VERSION "dbc-export 1 2026.26.6.5"

NS_ :

BS_:

BU_: ADSP APB APP APS APSB BB BMS CC CMP CMPD CP DAS DI DIF DIR DPB EPAS3P EPAS3S EPASTP EPASTS EPBL EPBR ESP EVSE FC GTW HCML HCMR HVP IBST ICR IDB LS OCS1P ODIN PARK PCS PCS2 PLG PM PMF PMR PNCD PTC RADC RCM RCM2 RCM3 RCU SCCM SCM SCS SDCR TAS TCU TCU2 TPMS TRCM UDS UI UIS UMC USM V2G VC VCBATT VCBATT0 VCBATT1 VCBATT2 VCCC VCFRONT VCFRONT1 VCFRONT2 VCLEFT VCRIGHT VCSEAT2L VCSEAT2R VCSEC VEH

BO_ 800 BMS_alertMatrix: 8 BMS
 SG_ BMS_matrixIndex M : 0|4@1+ (1,0) [0|15] "" Vector__XXX
 SG_ BMS_a001_Pack_Config_Mismatch m0 : 4|1@1+ (1,0) [0|1] "" Vector__XXX
 SG_ BMS_a002_Pack_Performance_Config m0 : 5|1@1+ (1,0) [0|1] "" Vector__XXX
 SG_ BMS_a003_SW_Pack_Birth_Date_Miss m0 : 6|1@1+ (1,0) [0|1] "" Vector__XXX
 SG_ BMS_a004_Cal_Vs_Serial_Birth_Dat m0 : 7|1@1+ (1,0) [0|1] "" Vector__XXX
 SG_ BMS_a016_Pack_Module_Id_Mismatch m0 : 19|1@1+ (1,0) [0|1] "" Vector__XXX
 SG_ BMS_a017_SW_Brick_OV m0 : 20|1@1+ (1,0) [0|1] "" Vector__XXX
 SG_ BMS_a018_SW_Brick_UV m0 : 21|1@1+ (1,0) [0|1] "" Vector__XXX
 SG_ BMS_a019_SW_Module_OT m0 : 22|1@1+ (1,0) [0|1] "" Vector__XXX
 SG_ BMS_a020_SW_Brick_Instability m0 : 23|1@1+ (1,0) [0|1] "" Vector__XXX
 SG_ BMS_a021_SW_Dr_Limits_Regulation m0 : 24|1@1+ (1,0) [0|1] "" Vector__XXX
 SG_ BMS_a022_SW_Over_Current m0 : 25|1@1+ (1,0) [0|1] "" Vector__XXX
 SG_ BMS_a023_SW_Stack_OV m0 : 26|1@1+ (1,0) [0|1] "" Vector__XXX
 SG_ BMS_a024_SW_Islanded_Brick m0 : 27|1@1+ (1,0) [0|1] "" Vector__XXX
 SG_ BMS_a025_SW_PwrBalance_Anomaly m0 : 28|1@1+ (1,0) [0|1] "" Vector__XXX
 SG_ BMS_a026_SW_HFCurrent_Anomaly m0 : 29|1@1+ (1,0) [0|1] "" Vector__XXX
 SG_ BMS_a027_SW_Repeated_Isolation_F m0 : 30|1@1+ (1,0) [0|1] "" Vector__XXX
 SG_ BMS_a028_ShuntAsicCurrentOffsetD m0 : 31|1@1+ (1,0) [0|1] "" Vector__XXX
 SG_ BMS_a029_dSoc_Limiting m0 : 32|1@1+ (1,0) [0|1] "" Vector__XXX
 SG_ BMS_a030_Impedance_Deviation m0 : 33|1@1+ (1,0) [0|1] "" Vector__XXX
 SG_ BMS_a031_AlertsSetDuringSleep m0 : 34|1@1+ (1,0) [0|1] "" Vector__XXX
 SG_ BMS_a032_VoltageLoss m0 : 35|1@1+ (1,0) [0|1] "" Vector__XXX
 SG_ BMS_a033_VoltageDeviation m0 : 36|1@1+ (1,0) [0|1] "" Vector__XXX
 SG_ BMS_a034_SW_Passive_Isolation m0 : 37|1@1+ (1,0) [0|1] "" Vector__XXX
 SG_ BMS_a035_SW_Isolation m0 : 38|1@1+ (1,0) [0|1] "" Vector__XXX
 SG_ BMS_a036_SW_HvpHvilFault m0 : 39|1@1+ (1,0) [0|1] "" Vector__XXX
 SG_ BMS_a037_SW_Flood_Port_Open m0 : 40|1@1+ (1,0) [0|1] "" Vector__XXX
 SG_ BMS_a039_SW_DC_Link_Over_Voltage m0 : 42|1@1+ (1,0) [0|1] "" Vector__XXX
 SG_ BMS_a040_SW_Watch_Dog_HW_Trigger m0 : 43|1@1+ (1,0) [0|1] "" Vector__XXX
 SG_ BMS_a041_SW_Destructive_Reset_So m0 : 44|1@1+ (1,0) [0|1] "" Vector__XXX
 SG_ BMS_a042_SW_MPU_Error m0 : 45|1@1+ (1,0) [0|1] "" Vector__XXX
 SG_ BMS_a043_SW_Watch_Dog_Reset m0 : 46|1@1+ (1,0) [0|1] "" Vector__XXX
 SG_ BMS_a044_SW_Assertion m0 : 47|1@1+ (1,0) [0|1] "" Vector__XXX
 SG_ BMS_a045_SW_Exception m0 : 48|1@1+ (1,0) [0|1] "" Vector__XXX
 SG_ BMS_a046_SW_Task_Stack_Usage m0 : 49|1@1+ (1,0) [0|1] "" Vector__XXX
 SG_ BMS_a047_SW_Task_Stack_Overflow m0 : 50|1@1+ (1,0) [0|1] "" Vector__XXX
 SG_ BMS_a048_SW_Watch_Dog_Warning m0 : 51|1@1+ (1,0) [0|1] "" Vector__XXX
 SG_ BMS_a049_SW_Thermal_Event m0 : 52|1@1+ (1,0) [0|1] "" Vector__XXX
 SG_ BMS_a050_SW_Brick_Voltage_MIA m0 : 53|1@1+ (1,0) [0|1] "" Vector__XXX
 SG_ BMS_a051_SW_HVC_Vref_Bad m0 : 54|1@1+ (1,0) [0|1] "" Vector__XXX
 SG_ BMS_a052_SW_PCS_MIA m0 : 55|1@1+ (1,0) [0|1] "" Vector__XXX
 SG_ BMS_a054_SW_Ver_Supply_Fault m0 : 57|1@1+ (1,0) [0|1] "" Vector__XXX
 SG_ BMS_a055_SW_HvChain_Model_Fault m0 : 58|1@1+ (1,0) [0|1] "" Vector__XXX
 SG_ BMS_a056_SW_Standby_Supply_Fault m0 : 59|1@1+ (1,0) [0|1] "" Vector__XXX
 SG_ BMS_a057_SW_Bandolier_Model_Warn m0 : 60|1@1+ (1,0) [0|1] "" Vector__XXX
 SG_ BMS_a058_SW_Bandolier_Model_Rese m0 : 61|1@1+ (1,0) [0|1] "" Vector__XXX
 SG_ BMS_a059_SW_Pack_Voltage_Sensing m0 : 62|1@1+ (1,0) [0|1] "" Vector__XXX
 SG_ BMS_a060_SW_Leakage_Test_Failure m0 : 63|1@1+ (1,0) [0|1] "" Vector__XXX
 SG_ BMS_a061_SW_BrickV_Change m1 : 4|1@1+ (1,0) [0|1] "" Vector__XXX
 SG_ BMS_a062_SW_BrickV_Imbalance m1 : 5|1@1+ (1,0) [0|1] "" Vector__XXX
 SG_ BMS_a063_SW_ChargePort_Fault m1 : 6|1@1+ (1,0) [0|1] "" Vector__XXX
 SG_ BMS_a064_SW_SOC_Imbalance m1 : 7|1@1+ (1,0) [0|1] "" Vector__XXX
 SG_ BMS_a065_SW_CAC_Imbalance m1 : 8|1@1+ (1,0) [0|1] "" Vector__XXX
 SG_ BMS_a066_SOC_Imbalance_Warning m1 : 9|1@1+ (1,0) [0|1] "" Vector__XXX
 SG_ BMS_a067_CAC_Imbalance_Limiting m1 : 10|1@1+ (1,0) [0|1] "" Vector__XXX
 SG_ BMS_a068_CAC_Imbalance_Limp m1 : 11|1@1+ (1,0) [0|1] "" Vector__XXX
 SG_ BMS_a069_SW_Low_Power m1 : 12|1@1+ (1,0) [0|1] "" Vector__XXX
 SG_ BMS_a070_BrickV_Imbalance_Limiti m1 : 13|1@1+ (1,0) [0|1] "" Vector__XXX
 SG_ BMS_a071_SW_SM_TransCon_Not_Met m1 : 14|1@1+ (1,0) [0|1] "" Vector__XXX
 SG_ BMS_a072_Module_Brick_Split m1 : 15|1@1+ (1,0) [0|1] "" Vector__XXX
 SG_ BMS_a073_Unexpected_Loss_Of_Lv m1 : 16|1@1+ (1,0) [0|1] "" Vector__XXX
 SG_ BMS_a074_Max_Charge_Level_Reduce m1 : 17|1@1+ (1,0) [0|1] "" Vector__XXX
 SG_ BMS_a075_SW_Chg_Disable_Failure m1 : 18|1@1+ (1,0) [0|1] "" Vector__XXX
 SG_ BMS_a076_SW_Dch_While_Charging m1 : 19|1@1+ (1,0) [0|1] "" Vector__XXX
 SG_ BMS_a077_SW_Charger_Regulation m1 : 20|1@1+ (1,0) [0|1] "" Vector__XXX
 SG_ BMS_a078_Rapid_Dch_While_Chargin m1 : 21|1@1+ (1,0) [0|1] "" Vector__XXX
 SG_ BMS_a079_Max_Charge_Level_Exceed m1 : 22|1@1+ (1,0) [0|1] "" Vector__XXX
 SG_ BMS_a080_SW_Pack_Ctr_Impedance m1 : 23|1@1+ (1,0) [0|1] "" Vector__XXX
 SG_ BMS_a081_SW_Ctr_Close_Blocked m1 : 24|1@1+ (1,0) [0|1] "" Vector__XXX
 SG_ BMS_a082_SW_Ctr_Force_Open m1 : 25|1@1+ (1,0) [0|1] "" Vector__XXX
 SG_ BMS_a083_SW_Ctr_Close_Failure m1 : 26|1@1+ (1,0) [0|1] "" Vector__XXX
 SG_ BMS_a084_SW_Sleep_Wake_Aborted m1 : 27|1@1+ (1,0) [0|1] "" Vector__XXX
 SG_ BMS_a085_SW_Pack_Contactor_Misma m1 : 28|1@1+ (1,0) [0|1] "" Vector__XXX
 SG_ BMS_a086_SW_FC_Contactor_Mismatc m1 : 29|1@1+ (1,0) [0|1] "" Vector__XXX
 SG_ BMS_a087_SW_Feim_Test_Blocked m1 : 30|1@1+ (1,0) [0|1] "" Vector__XXX
 SG_ BMS_a088_SW_VcFront_MIA_InDrive m1 : 31|1@1+ (1,0) [0|1] "" Vector__XXX
 SG_ BMS_a089_SW_VcFront_MIA m1 : 32|1@1+ (1,0) [0|1] "" Vector__XXX
 SG_ BMS_a090_SW_Gateway_MIA m1 : 33|1@1+ (1,0) [0|1] "" Vector__XXX
 SG_ BMS_a091_SW_ChargePort_MIA m1 : 34|1@1+ (1,0) [0|1] "" Vector__XXX
 SG_ BMS_a092_SW_ChargePort_Mia_On_Hv m1 : 35|1@1+ (1,0) [0|1] "" Vector__XXX
 SG_ BMS_a094_SW_Drive_Inverter_MIA m1 : 37|1@1+ (1,0) [0|1] "" Vector__XXX
 SG_ BMS_a095_SW_UI_MIA m1 : 38|1@1+ (1,0) [0|1] "" Vector__XXX
 SG_ BMS_a097_SW_BMB_Over_CAN_Communi m1 : 40|1@1+ (1,0) [0|1] "" Vector__XXX
 SG_ BMS_a098_SW_BMB_Data_Integrity_L m1 : 41|1@1+ (1,0) [0|1] "" Vector__XXX
 SG_ BMS_a099_SW_BMB_Communication m1 : 42|1@1+ (1,0) [0|1] "" Vector__XXX
 SG_ BMS_a100_ThermalEventSuspected m1 : 43|1@1+ (1,0) [0|1] "" Vector__XXX
 SG_ BMS_a105_SW_One_Module_Tsense m1 : 48|1@1+ (1,0) [0|1] "" Vector__XXX
 SG_ BMS_a106_SW_All_Module_Tsense m1 : 49|1@1+ (1,0) [0|1] "" Vector__XXX
 SG_ BMS_a107_SW_Stack_Voltage_MIA m1 : 50|1@1+ (1,0) [0|1] "" Vector__XXX
 SG_ BMS_a108_SW_BMB_Device_OT m1 : 51|1@1+ (1,0) [0|1] "" Vector__XXX
 SG_ BMS_a109_HW_BMB_Mute_Status_Mism m1 : 52|1@1+ (1,0) [0|1] "" Vector__XXX
 SG_ BMS_a110_LifeModel_AvgOffset_Cha m1 : 53|1@1+ (1,0) [0|1] "" Vector__XXX
 SG_ BMS_a111_LifeModel_Spread_Change m1 : 54|1@1+ (1,0) [0|1] "" Vector__XXX
 SG_ BMS_a112_LifeModel_Discontinuity m1 : 55|1@1+ (1,0) [0|1] "" Vector__XXX
 SG_ BMS_a115_Energy_Rubberbanding_Re m1 : 58|1@1+ (1,0) [0|1] "" Vector__XXX
 SG_ BMS_a117_SW_Delta_SOC_Weak_Short m1 : 60|1@1+ (1,0) [0|1] "" Vector__XXX
 SG_ BMS_a118_SW_Delta_SOC_Weak_Short m1 : 61|1@1+ (1,0) [0|1] "" Vector__XXX
 SG_ BMS_a119_Fast_Open_Vsh_Detected m1 : 62|1@1+ (1,0) [0|1] "" Vector__XXX
 SG_ BMS_a120_SW_Delta_SOC_User_Warni m1 : 63|1@1+ (1,0) [0|1] "" Vector__XXX
 SG_ BMS_a121_SW_NVRAM_Config_Error m2 : 4|1@1+ (1,0) [0|1] "" Vector__XXX
 SG_ BMS_a122_SW_BMS_Therm_Irrational m2 : 5|1@1+ (1,0) [0|1] "" Vector__XXX
 SG_ BMS_a123_SW_Internal_Isolation m2 : 6|1@1+ (1,0) [0|1] "" Vector__XXX
 SG_ BMS_a124_Battery_Coolant_Flood m2 : 7|1@1+ (1,0) [0|1] "" Vector__XXX
 SG_ BMS_a126_SW_Thermistor_Failure m2 : 9|1@1+ (1,0) [0|1] "" Vector__XXX
 SG_ BMS_a127_SW_shunt_SNA m2 : 10|1@1+ (1,0) [0|1] "" Vector__XXX
 SG_ BMS_a128_SW_shunt_MIA m2 : 11|1@1+ (1,0) [0|1] "" Vector__XXX
 SG_ BMS_a129_SW_VSH_Failure m2 : 12|1@1+ (1,0) [0|1] "" Vector__XXX
 SG_ BMS_a130_IO_CAN_Error m2 : 13|1@1+ (1,0) [0|1] "" Vector__XXX
 SG_ BMS_a131_Bleed_FET_Failure m2 : 14|1@1+ (1,0) [0|1] "" Vector__XXX
 SG_ BMS_a132_HW_BMB_OTP_Uncorrctbl m2 : 15|1@1+ (1,0) [0|1] "" Vector__XXX
 SG_ BMS_a133_IO_CAN_Bus_Off m2 : 16|1@1+ (1,0) [0|1] "" Vector__XXX
 SG_ BMS_a134_SW_Delayed_Ctr_Off m2 : 17|1@1+ (1,0) [0|1] "" Vector__XXX
 SG_ BMS_a135_HW_BMB_Diagnostics_Fail m2 : 18|1@1+ (1,0) [0|1] "" Vector__XXX
 SG_ BMS_a136_SW_Module_OT_Warning m2 : 19|1@1+ (1,0) [0|1] "" Vector__XXX
 SG_ BMS_a137_SW_Brick_UV_Warning m2 : 20|1@1+ (1,0) [0|1] "" Vector__XXX
 SG_ BMS_a138_SW_Brick_OV_Warning m2 : 21|1@1+ (1,0) [0|1] "" Vector__XXX
 SG_ BMS_a139_SW_DC_Link_V_Irrational m2 : 22|1@1+ (1,0) [0|1] "" Vector__XXX
 SG_ BMS_a140_HW_BMB_Status_Fault m2 : 23|1@1+ (1,0) [0|1] "" Vector__XXX
 SG_ BMS_a141_SW_BMB_Status_Warning m2 : 24|1@1+ (1,0) [0|1] "" Vector__XXX
 SG_ BMS_a142_SW_Isolation_Degradatio m2 : 25|1@1+ (1,0) [0|1] "" Vector__XXX
 SG_ BMS_a143_SW_CAC_Change m2 : 26|1@1+ (1,0) [0|1] "" Vector__XXX
 SG_ BMS_a144_Hvp_Config_Mismatch m2 : 27|1@1+ (1,0) [0|1] "" Vector__XXX
 SG_ BMS_a145_SW_SOC_Change m2 : 28|1@1+ (1,0) [0|1] "" Vector__XXX
 SG_ BMS_a146_SW_Brick_Overdischarged m2 : 29|1@1+ (1,0) [0|1] "" Vector__XXX
 SG_ BMS_a147_SW_SOC_High_Ah_Error m2 : 30|1@1+ (1,0) [0|1] "" Vector__XXX
 SG_ BMS_a148_SW_Unsupported_BMB_ASIC m2 : 31|1@1+ (1,0) [0|1] "" Vector__XXX
 SG_ BMS_a149_SW_Missing_Config_Block m2 : 32|1@1+ (1,0) [0|1] "" Vector__XXX
 SG_ BMS_a150_SW_Missing_Part_Number m2 : 33|1@1+ (1,0) [0|1] "" Vector__XXX
 SG_ BMS_a151_SW_external_isolation m2 : 34|1@1+ (1,0) [0|1] "" Vector__XXX
 SG_ BMS_a152_Isolation_In_Dc_Charge m2 : 35|1@1+ (1,0) [0|1] "" Vector__XXX
 SG_ BMS_a153_GridFormFaulted m2 : 36|1@1+ (1,0) [0|1] "" Vector__XXX
 SG_ BMS_a154_SW_Brick_OV_Warning_Sto m2 : 37|1@1+ (1,0) [0|1] "" Vector__XXX
 SG_ BMS_a155_SW_Weak_short_impedence m2 : 38|1@1+ (1,0) [0|1] "" Vector__XXX
 SG_ BMS_a156_SW_BMB_Vref_bad m2 : 39|1@1+ (1,0) [0|1] "" Vector__XXX
 SG_ BMS_a157_SW_Hist_Update_Missed m2 : 40|1@1+ (1,0) [0|1] "" Vector__XXX
 SG_ BMS_a158_SW_HVP_HVI_Comms m2 : 41|1@1+ (1,0) [0|1] "" Vector__XXX
 SG_ BMS_a159_SW_HVP_ECU_Error m2 : 42|1@1+ (1,0) [0|1] "" Vector__XXX
 SG_ BMS_a160_SW_FC_Ctr_Clean_Failed m2 : 43|1@1+ (1,0) [0|1] "" Vector__XXX
 SG_ BMS_a161_SW_BMB_Vref_warning m2 : 44|1@1+ (1,0) [0|1] "" Vector__XXX
 SG_ BMS_a162_SW_No_Power_For_Support m2 : 45|1@1+ (1,0) [0|1] "" Vector__XXX
 SG_ BMS_a163_GridFormAborted m2 : 46|1@1+ (1,0) [0|1] "" Vector__XXX
 SG_ BMS_a164_SW_Uncontrolled_Regen m2 : 47|1@1+ (1,0) [0|1] "" Vector__XXX
 SG_ BMS_a165_SW_Pack_Partial_Weld m2 : 48|1@1+ (1,0) [0|1] "" Vector__XXX
 SG_ BMS_a166_SW_Pack_Full_Weld m2 : 49|1@1+ (1,0) [0|1] "" Vector__XXX
 SG_ BMS_a167_SW_FC_Partial_Weld m2 : 50|1@1+ (1,0) [0|1] "" Vector__XXX
 SG_ BMS_a168_SW_FC_Full_Weld m2 : 51|1@1+ (1,0) [0|1] "" Vector__XXX
 SG_ BMS_a169_SW_FC_Pack_Weld m2 : 52|1@1+ (1,0) [0|1] "" Vector__XXX
 SG_ BMS_a170_SW_Limp_Mode m2 : 53|1@1+ (1,0) [0|1] "" Vector__XXX
 SG_ BMS_a171_SW_Stack_Voltage_Sense m2 : 54|1@1+ (1,0) [0|1] "" Vector__XXX
 SG_ BMS_a172_SW_Isolation_Failure_In m2 : 55|1@1+ (1,0) [0|1] "" Vector__XXX
 SG_ BMS_a173_FullPackEnergyDegraded m2 : 56|1@1+ (1,0) [0|1] "" Vector__XXX
 SG_ BMS_a174_SW_Charge_Failure m2 : 57|1@1+ (1,0) [0|1] "" Vector__XXX
 SG_ BMS_a175_Charge_Failure_External m2 : 58|1@1+ (1,0) [0|1] "" Vector__XXX
 SG_ BMS_a176_SW_GracefulPowerOff m2 : 59|1@1+ (1,0) [0|1] "" Vector__XXX
 SG_ BMS_a177_SW_Energy_Buffer_Size m2 : 60|1@1+ (1,0) [0|1] "" Vector__XXX
 SG_ BMS_a178_SW_Uncontrolled_Regen_P m2 : 61|1@1+ (1,0) [0|1] "" Vector__XXX
 SG_ BMS_a179_HvpGpoRequestActive m2 : 62|1@1+ (1,0) [0|1] "" Vector__XXX
 SG_ BMS_a180_SW_ECU_reset_blocked m2 : 63|1@1+ (1,0) [0|1] "" Vector__XXX
 SG_ BMS_a181_SW_Shunt_Over_Temperatu m3 : 4|1@1+ (1,0) [0|1] "" Vector__XXX
 SG_ BMS_a182_LifeModel_NoCurrentLoss m3 : 5|1@1+ (1,0) [0|1] "" Vector__XXX
 SG_ BMS_a183_LifeModel_StoDcrGrowth_ m3 : 6|1@1+ (1,0) [0|1] "" Vector__XXX
 SG_ BMS_a184_LifeModel_CyclingLoss_C m3 : 7|1@1+ (1,0) [0|1] "" Vector__XXX
 SG_ BMS_a185_LifeModel_CyclingDcrGro m3 : 8|1@1+ (1,0) [0|1] "" Vector__XXX
 SG_ BMS_a186_RippleHeatingChargeFaul m3 : 9|1@1+ (1,0) [0|1] "" Vector__XXX
 SG_ BMS_a187_RippleHeatingEmergencyS m3 : 10|1@1+ (1,0) [0|1] "" Vector__XXX
 SG_ BMS_a188_PowershareChargeCurrent m3 : 11|1@1+ (1,0) [0|1] "" Vector__XXX
 SG_ BMS_a189_PowershareDischargeCurr m3 : 12|1@1+ (1,0) [0|1] "" Vector__XXX
 SG_ BMS_a190_PowershareMaxVoltageVio m3 : 13|1@1+ (1,0) [0|1] "" Vector__XXX
 SG_ BMS_a191_PowershareMinVoltageVio m3 : 14|1@1+ (1,0) [0|1] "" Vector__XXX
 SG_ BMS_a192_PowershareExternalCharg m3 : 15|1@1+ (1,0) [0|1] "" Vector__XXX
 SG_ BMS_a193_PowershareMaxBrickVolta m3 : 16|1@1+ (1,0) [0|1] "" Vector__XXX
 SG_ BMS_a194_PowershareLimitViolatio m3 : 17|1@1+ (1,0) [0|1] "" Vector__XXX
 SG_ BMS_a195_SW_DeltaTempOverThresho m3 : 18|1@1+ (1,0) [0|1] "" Vector__XXX
 SG_ BMS_a196_SW_PackVoltageUnderThre m3 : 19|1@1+ (1,0) [0|1] "" Vector__XXX
 SG_ BMS_a197_SW_High_SOC_OV m3 : 20|1@1+ (1,0) [0|1] "" Vector__XXX
 SG_ BMS_a198_SW_SOC_Abrupt_Change m3 : 21|1@1+ (1,0) [0|1] "" Vector__XXX
 SG_ BMS_a199_GridFollowAborted m3 : 22|1@1+ (1,0) [0|1] "" Vector__XXX
 SG_ BMS_a200_GridFollowFaulted m3 : 23|1@1+ (1,0) [0|1] "" Vector__XXX
 SG_ BMS_a201_SW_Brick_OV_During_Char m3 : 24|1@1+ (1,0) [0|1] "" Vector__XXX
 SG_ BMS_a202_AcChargeFaulted m3 : 25|1@1+ (1,0) [0|1] "" Vector__XXX
 SG_ BMS_a204_AcCpEmergencyShutdownRe m3 : 27|1@1+ (1,0) [0|1] "" Vector__XXX
 SG_ BMS_a214_AcChargeAborted m3 : 37|1@1+ (1,0) [0|1] "" Vector__XXX
 SG_ BMS_a221_PcsEmergencyShutdownReq m3 : 44|1@1+ (1,0) [0|1] "" Vector__XXX
 SG_ BMS_a227_ExcessChargeCurrentInCh m3 : 50|1@1+ (1,0) [0|1] "" Vector__XXX
 SG_ BMS_a254_LdcsCacImbalance m4 : 17|1@1+ (1,0) [0|1] "" Vector__XXX
 SG_ BMS_a255_EstimatedRangeReduced m4 : 18|1@1+ (1,0) [0|1] "" Vector__XXX
 SG_ BMS_a256_SW_Low_Power_Warning m4 : 19|1@1+ (1,0) [0|1] "" Vector__XXX
 SG_ BMS_d257_internalIsolationFault m4 : 20|1@1+ (1,0) [0|1] "" Vector__XXX
 SG_ BMS_d258_externalIsolationFault m4 : 21|1@1+ (1,0) [0|1] "" Vector__XXX
 SG_ BMS_d259_highVoltageInterlockFai m4 : 22|1@1+ (1,0) [0|1] "" Vector__XXX
 SG_ BMS_d260_chargePortInterlockFail m4 : 23|1@1+ (1,0) [0|1] "" Vector__XXX
 SG_ BMS_d261_batteryPackCellVoltageH m4 : 24|1@1+ (1,0) [0|1] "" Vector__XXX
 SG_ BMS_d262_batteryPackLowStateOfCh m4 : 25|1@1+ (1,0) [0|1] "" Vector__XXX
 SG_ BMS_d263_batterySystemCurrentHig m4 : 26|1@1+ (1,0) [0|1] "" Vector__XXX
 SG_ BMS_d264_invalidFirmwareConfig m4 : 27|1@1+ (1,0) [0|1] "" Vector__XXX
 SG_ BMS_d265_replaceBatteryPack m4 : 28|1@1+ (1,0) [0|1] "" Vector__XXX
 SG_ BMS_d266_energyReserveVoltageLow m4 : 29|1@1+ (1,0) [0|1] "" Vector__XXX
 SG_ BMS_d267_batteryPackCellVoltageS m4 : 30|1@1+ (1,0) [0|1] "" Vector__XXX
 SG_ BMS_d268_hvpInvalidFirmwareConfi m4 : 31|1@1+ (1,0) [0|1] "" Vector__XXX
 SG_ BMS_d269_highVoltageFuseABlown m4 : 32|1@1+ (1,0) [0|1] "" Vector__XXX
 SG_ BMS_d270_hvpCommsLost m4 : 33|1@1+ (1,0) [0|1] "" Vector__XXX
 SG_ BMS_d271_batteryPackSensorFailur m4 : 34|1@1+ (1,0) [0|1] "" Vector__XXX
 SG_ BMS_d272_batteryPackSensorCommsL m4 : 35|1@1+ (1,0) [0|1] "" Vector__XXX
 SG_ BMS_d273_vcFrontCommsLost m4 : 36|1@1+ (1,0) [0|1] "" Vector__XXX
 SG_ BMS_d274_packCurrentSensorACircu m4 : 37|1@1+ (1,0) [0|1] "" Vector__XXX
 SG_ BMS_d275_packPosContactorACircui m4 : 38|1@1+ (1,0) [0|1] "" Vector__XXX
 SG_ BMS_d276_packPosContactorAStuckC m4 : 39|1@1+ (1,0) [0|1] "" Vector__XXX
 SG_ BMS_d277_packNegContactorACircui m4 : 40|1@1+ (1,0) [0|1] "" Vector__XXX
 SG_ BMS_d278_packNegContactorAStuckC m4 : 41|1@1+ (1,0) [0|1] "" Vector__XXX
 SG_ BMS_d279_fastChargePosContactorA m4 : 42|1@1+ (1,0) [0|1] "" Vector__XXX
 SG_ BMS_d280_fastChargePosContactorA m4 : 43|1@1+ (1,0) [0|1] "" Vector__XXX
 SG_ BMS_d281_fastChargePosContactorA m4 : 44|1@1+ (1,0) [0|1] "" Vector__XXX
 SG_ BMS_d282_fastChargeNegContactorA m4 : 45|1@1+ (1,0) [0|1] "" Vector__XXX
 SG_ BMS_d283_fastChargeNegContactorA m4 : 46|1@1+ (1,0) [0|1] "" Vector__XXX
 SG_ BMS_d284_fastChargeNegContactorA m4 : 47|1@1+ (1,0) [0|1] "" Vector__XXX
 SG_ BMS_d285_packVoltageSensorACircu m4 : 48|1@1+ (1,0) [0|1] "" Vector__XXX
 SG_ BMS_d286_dcLinkVoltageHigh m4 : 49|1@1+ (1,0) [0|1] "" Vector__XXX
 SG_ BMS_d287_systemIsolationWarning m4 : 50|1@1+ (1,0) [0|1] "" Vector__XXX
 SG_ BMS_d288_batteryPackCellVoltageL m4 : 51|1@1+ (1,0) [0|1] "" Vector__XXX
 SG_ BMS_d289_batteryPackAOverTempera m4 : 52|1@1+ (1,0) [0|1] "" Vector__XXX
 SG_ BMS_d290_batteryPackTempSensorAC m4 : 53|1@1+ (1,0) [0|1] "" Vector__XXX
 SG_ BMS_a291_SOC_Imbalance_By_Delta_ m4 : 54|1@1+ (1,0) [0|1] "" Vector__XXX
 SG_ BMS_a299_PowershareFailure m4 : 62|1@1+ (1,0) [0|1] "" Vector__XXX

BO_ 818 BMS_bmbMinMax: 6 BMS
 SG_ BMS_bmbMinMaxMultiplexer M : 0|2@1+ (1,0) [0|3] "" Vector__XXX
 SG_ BMS_thermistorNumTMin m0 : 2|4@1+ (1,0) [0|15] "" Vector__XXX
 SG_ BMS_thermistorNumTMax m0 : 8|4@1+ (1,0) [0|15] "" Vector__XXX
 SG_ BMS_thermistorTMax m0 : 16|8@1+ (0.5,-40) [-40|87.5] "DegC" Vector__XXX
 SG_ BMS_thermistorTMin m0 : 24|8@1+ (0.5,-40) [-40|87.5] "DegC" Vector__XXX
 SG_ BMS_thermistorTAvg m0 : 32|8@1+ (0.5,-40) [-40|87.5] "DegC" Vector__XXX
 SG_ BMS_brickVoltageMax m1 : 2|12@1+ (0.002,0) [0|5] "V" Vector__XXX
 SG_ BMS_brickVoltageMin m1 : 16|12@1+ (0.002,0) [0|5] "V" Vector__XXX
 SG_ BMS_brickNumVoltageMax m1 : 32|7@1+ (1,1) [1|128] "" Vector__XXX
 SG_ BMS_brickNumVoltageMin m1 : 40|7@1+ (1,1) [1|128] "" Vector__XXX

BO_ 1025 BMS_brickMeasurements: 8 BMS
 SG_ BMS_brickVoltageMultiplexer M : 0|8@1+ (1,0) [0|255] "" Vector__XXX
 SG_ BMS_brickVoltageCounter : 14|2@1+ (1,0) [0|3] "" Vector__XXX
 SG_ BMS_brickVoltageStatus1 m0 : 8|2@1+ (1,0) [0|3] "" Vector__XXX
 SG_ BMS_brickVoltageStatus2 m0 : 10|2@1+ (1,0) [0|3] "" Vector__XXX
 SG_ BMS_brickVoltageStatus3 m0 : 12|2@1+ (1,0) [0|3] "" Vector__XXX
 SG_ BMS_brickVoltage1 m0 : 16|16@1+ (0.0001,0) [0|5] "V" Vector__XXX
 SG_ BMS_brickVoltage2 m0 : 32|16@1+ (0.0001,0) [0|5] "V" Vector__XXX
 SG_ BMS_brickVoltage3 m0 : 48|16@1+ (0.0001,0) [0|5] "V" Vector__XXX
 SG_ BMS_brickVoltageStatus4 m1 : 8|2@1+ (1,0) [0|3] "" Vector__XXX
 SG_ BMS_brickVoltageStatus5 m1 : 10|2@1+ (1,0) [0|3] "" Vector__XXX
 SG_ BMS_brickVoltageStatus6 m1 : 12|2@1+ (1,0) [0|3] "" Vector__XXX
 SG_ BMS_brickVoltage4 m1 : 16|16@1+ (0.0001,0) [0|5] "V" Vector__XXX
 SG_ BMS_brickVoltage5 m1 : 32|16@1+ (0.0001,0) [0|5] "V" Vector__XXX
 SG_ BMS_brickVoltage6 m1 : 48|16@1+ (0.0001,0) [0|5] "V" Vector__XXX
 SG_ BMS_brickVoltageStatus7 m2 : 8|2@1+ (1,0) [0|3] "" Vector__XXX
 SG_ BMS_brickVoltageStatus8 m2 : 10|2@1+ (1,0) [0|3] "" Vector__XXX
 SG_ BMS_brickVoltageStatus9 m2 : 12|2@1+ (1,0) [0|3] "" Vector__XXX
 SG_ BMS_brickVoltage7 m2 : 16|16@1+ (0.0001,0) [0|5] "V" Vector__XXX
 SG_ BMS_brickVoltage8 m2 : 32|16@1+ (0.0001,0) [0|5] "V" Vector__XXX
 SG_ BMS_brickVoltage9 m2 : 48|16@1+ (0.0001,0) [0|5] "V" Vector__XXX
 SG_ BMS_brickVoltageStatus10 m3 : 8|2@1+ (1,0) [0|3] "" Vector__XXX
 SG_ BMS_brickVoltageStatus11 m3 : 10|2@1+ (1,0) [0|3] "" Vector__XXX
 SG_ BMS_brickVoltageStatus12 m3 : 12|2@1+ (1,0) [0|3] "" Vector__XXX
 SG_ BMS_brickVoltage10 m3 : 16|16@1+ (0.0001,0) [0|5] "V" Vector__XXX
 SG_ BMS_brickVoltage11 m3 : 32|16@1+ (0.0001,0) [0|5] "V" Vector__XXX
 SG_ BMS_brickVoltage12 m3 : 48|16@1+ (0.0001,0) [0|5] "V" Vector__XXX
 SG_ BMS_brickVoltageStatus13 m4 : 8|2@1+ (1,0) [0|3] "" Vector__XXX
 SG_ BMS_brickVoltageStatus14 m4 : 10|2@1+ (1,0) [0|3] "" Vector__XXX
 SG_ BMS_brickVoltageStatus15 m4 : 12|2@1+ (1,0) [0|3] "" Vector__XXX
 SG_ BMS_brickVoltage13 m4 : 16|16@1+ (0.0001,0) [0|5] "V" Vector__XXX
 SG_ BMS_brickVoltage14 m4 : 32|16@1+ (0.0001,0) [0|5] "V" Vector__XXX
 SG_ BMS_brickVoltage15 m4 : 48|16@1+ (0.0001,0) [0|5] "V" Vector__XXX
 SG_ BMS_brickVoltageStatus16 m5 : 8|2@1+ (1,0) [0|3] "" Vector__XXX
 SG_ BMS_brickVoltageStatus17 m5 : 10|2@1+ (1,0) [0|3] "" Vector__XXX
 SG_ BMS_brickVoltageStatus18 m5 : 12|2@1+ (1,0) [0|3] "" Vector__XXX
 SG_ BMS_brickVoltage16 m5 : 16|16@1+ (0.0001,0) [0|5] "V" Vector__XXX
 SG_ BMS_brickVoltage17 m5 : 32|16@1+ (0.0001,0) [0|5] "V" Vector__XXX
 SG_ BMS_brickVoltage18 m5 : 48|16@1+ (0.0001,0) [0|5] "V" Vector__XXX
 SG_ BMS_brickVoltageStatus19 m6 : 8|2@1+ (1,0) [0|3] "" Vector__XXX
 SG_ BMS_brickVoltageStatus20 m6 : 10|2@1+ (1,0) [0|3] "" Vector__XXX
 SG_ BMS_brickVoltageStatus21 m6 : 12|2@1+ (1,0) [0|3] "" Vector__XXX
 SG_ BMS_brickVoltage19 m6 : 16|16@1+ (0.0001,0) [0|5] "V" Vector__XXX
 SG_ BMS_brickVoltage20 m6 : 32|16@1+ (0.0001,0) [0|5] "V" Vector__XXX
 SG_ BMS_brickVoltage21 m6 : 48|16@1+ (0.0001,0) [0|5] "V" Vector__XXX
 SG_ BMS_brickVoltageStatus22 m7 : 8|2@1+ (1,0) [0|3] "" Vector__XXX
 SG_ BMS_brickVoltageStatus23 m7 : 10|2@1+ (1,0) [0|3] "" Vector__XXX
 SG_ BMS_brickVoltageStatus24 m7 : 12|2@1+ (1,0) [0|3] "" Vector__XXX
 SG_ BMS_brickVoltage22 m7 : 16|16@1+ (0.0001,0) [0|5] "V" Vector__XXX
 SG_ BMS_brickVoltage23 m7 : 32|16@1+ (0.0001,0) [0|5] "V" Vector__XXX
 SG_ BMS_brickVoltage24 m7 : 48|16@1+ (0.0001,0) [0|5] "V" Vector__XXX
 SG_ BMS_brickVoltageStatus25 m8 : 8|2@1+ (1,0) [0|3] "" Vector__XXX
 SG_ BMS_brickVoltageStatus26 m8 : 10|2@1+ (1,0) [0|3] "" Vector__XXX
 SG_ BMS_brickVoltageStatus27 m8 : 12|2@1+ (1,0) [0|3] "" Vector__XXX
 SG_ BMS_brickVoltage25 m8 : 16|16@1+ (0.0001,0) [0|5] "V" Vector__XXX
 SG_ BMS_brickVoltage26 m8 : 32|16@1+ (0.0001,0) [0|5] "V" Vector__XXX
 SG_ BMS_brickVoltage27 m8 : 48|16@1+ (0.0001,0) [0|5] "V" Vector__XXX
 SG_ BMS_brickVoltageStatus28 m9 : 8|2@1+ (1,0) [0|3] "" Vector__XXX
 SG_ BMS_brickVoltageStatus29 m9 : 10|2@1+ (1,0) [0|3] "" Vector__XXX
 SG_ BMS_brickVoltageStatus30 m9 : 12|2@1+ (1,0) [0|3] "" Vector__XXX
 SG_ BMS_brickVoltage28 m9 : 16|16@1+ (0.0001,0) [0|5] "V" Vector__XXX
 SG_ BMS_brickVoltage29 m9 : 32|16@1+ (0.0001,0) [0|5] "V" Vector__XXX
 SG_ BMS_brickVoltage30 m9 : 48|16@1+ (0.0001,0) [0|5] "V" Vector__XXX
 SG_ BMS_brickVoltageStatus31 m10 : 8|2@1+ (1,0) [0|3] "" Vector__XXX
 SG_ BMS_brickVoltageStatus32 m10 : 10|2@1+ (1,0) [0|3] "" Vector__XXX
 SG_ BMS_brickVoltageStatus33 m10 : 12|2@1+ (1,0) [0|3] "" Vector__XXX
 SG_ BMS_brickVoltage31 m10 : 16|16@1+ (0.0001,0) [0|5] "V" Vector__XXX
 SG_ BMS_brickVoltage32 m10 : 32|16@1+ (0.0001,0) [0|5] "V" Vector__XXX
 SG_ BMS_brickVoltage33 m10 : 48|16@1+ (0.0001,0) [0|5] "V" Vector__XXX
 SG_ BMS_brickVoltageStatus34 m11 : 8|2@1+ (1,0) [0|3] "" Vector__XXX
 SG_ BMS_brickVoltageStatus35 m11 : 10|2@1+ (1,0) [0|3] "" Vector__XXX
 SG_ BMS_brickVoltageStatus36 m11 : 12|2@1+ (1,0) [0|3] "" Vector__XXX
 SG_ BMS_brickVoltage34 m11 : 16|16@1+ (0.0001,0) [0|5] "V" Vector__XXX
 SG_ BMS_brickVoltage35 m11 : 32|16@1+ (0.0001,0) [0|5] "V" Vector__XXX
 SG_ BMS_brickVoltage36 m11 : 48|16@1+ (0.0001,0) [0|5] "V" Vector__XXX
 SG_ BMS_brickVoltageStatus37 m12 : 8|2@1+ (1,0) [0|3] "" Vector__XXX
 SG_ BMS_brickVoltageStatus38 m12 : 10|2@1+ (1,0) [0|3] "" Vector__XXX
 SG_ BMS_brickVoltageStatus39 m12 : 12|2@1+ (1,0) [0|3] "" Vector__XXX
 SG_ BMS_brickVoltage37 m12 : 16|16@1+ (0.0001,0) [0|5] "V" Vector__XXX
 SG_ BMS_brickVoltage38 m12 : 32|16@1+ (0.0001,0) [0|5] "V" Vector__XXX
 SG_ BMS_brickVoltage39 m12 : 48|16@1+ (0.0001,0) [0|5] "V" Vector__XXX
 SG_ BMS_brickVoltageStatus40 m13 : 8|2@1+ (1,0) [0|3] "" Vector__XXX
 SG_ BMS_brickVoltageStatus41 m13 : 10|2@1+ (1,0) [0|3] "" Vector__XXX
 SG_ BMS_brickVoltageStatus42 m13 : 12|2@1+ (1,0) [0|3] "" Vector__XXX
 SG_ BMS_brickVoltage40 m13 : 16|16@1+ (0.0001,0) [0|5] "V" Vector__XXX
 SG_ BMS_brickVoltage41 m13 : 32|16@1+ (0.0001,0) [0|5] "V" Vector__XXX
 SG_ BMS_brickVoltage42 m13 : 48|16@1+ (0.0001,0) [0|5] "V" Vector__XXX
 SG_ BMS_brickVoltageStatus43 m14 : 8|2@1+ (1,0) [0|3] "" Vector__XXX
 SG_ BMS_brickVoltageStatus44 m14 : 10|2@1+ (1,0) [0|3] "" Vector__XXX
 SG_ BMS_brickVoltageStatus45 m14 : 12|2@1+ (1,0) [0|3] "" Vector__XXX
 SG_ BMS_brickVoltage43 m14 : 16|16@1+ (0.0001,0) [0|5] "V" Vector__XXX
 SG_ BMS_brickVoltage44 m14 : 32|16@1+ (0.0001,0) [0|5] "V" Vector__XXX
 SG_ BMS_brickVoltage45 m14 : 48|16@1+ (0.0001,0) [0|5] "V" Vector__XXX
 SG_ BMS_brickVoltageStatus46 m15 : 8|2@1+ (1,0) [0|3] "" Vector__XXX
 SG_ BMS_brickVoltageStatus47 m15 : 10|2@1+ (1,0) [0|3] "" Vector__XXX
 SG_ BMS_brickVoltageStatus48 m15 : 12|2@1+ (1,0) [0|3] "" Vector__XXX
 SG_ BMS_brickVoltage46 m15 : 16|16@1+ (0.0001,0) [0|5] "V" Vector__XXX
 SG_ BMS_brickVoltage47 m15 : 32|16@1+ (0.0001,0) [0|5] "V" Vector__XXX
 SG_ BMS_brickVoltage48 m15 : 48|16@1+ (0.0001,0) [0|5] "V" Vector__XXX
 SG_ BMS_brickVoltageStatus49 m16 : 8|2@1+ (1,0) [0|3] "" Vector__XXX
 SG_ BMS_brickVoltageStatus50 m16 : 10|2@1+ (1,0) [0|3] "" Vector__XXX
 SG_ BMS_brickVoltageStatus51 m16 : 12|2@1+ (1,0) [0|3] "" Vector__XXX
 SG_ BMS_brickVoltage49 m16 : 16|16@1+ (0.0001,0) [0|5] "V" Vector__XXX
 SG_ BMS_brickVoltage50 m16 : 32|16@1+ (0.0001,0) [0|5] "V" Vector__XXX
 SG_ BMS_brickVoltage51 m16 : 48|16@1+ (0.0001,0) [0|5] "V" Vector__XXX
 SG_ BMS_brickVoltageStatus52 m17 : 8|2@1+ (1,0) [0|3] "" Vector__XXX
 SG_ BMS_brickVoltageStatus53 m17 : 10|2@1+ (1,0) [0|3] "" Vector__XXX
 SG_ BMS_brickVoltageStatus54 m17 : 12|2@1+ (1,0) [0|3] "" Vector__XXX
 SG_ BMS_brickVoltage52 m17 : 16|16@1+ (0.0001,0) [0|5] "V" Vector__XXX
 SG_ BMS_brickVoltage53 m17 : 32|16@1+ (0.0001,0) [0|5] "V" Vector__XXX
 SG_ BMS_brickVoltage54 m17 : 48|16@1+ (0.0001,0) [0|5] "V" Vector__XXX
 SG_ BMS_brickVoltageStatus55 m18 : 8|2@1+ (1,0) [0|3] "" Vector__XXX
 SG_ BMS_brickVoltageStatus56 m18 : 10|2@1+ (1,0) [0|3] "" Vector__XXX
 SG_ BMS_brickVoltageStatus57 m18 : 12|2@1+ (1,0) [0|3] "" Vector__XXX
 SG_ BMS_brickVoltage55 m18 : 16|16@1+ (0.0001,0) [0|5] "V" Vector__XXX
 SG_ BMS_brickVoltage56 m18 : 32|16@1+ (0.0001,0) [0|5] "V" Vector__XXX
 SG_ BMS_brickVoltage57 m18 : 48|16@1+ (0.0001,0) [0|5] "V" Vector__XXX
 SG_ BMS_brickVoltageStatus58 m19 : 8|2@1+ (1,0) [0|3] "" Vector__XXX
 SG_ BMS_brickVoltageStatus59 m19 : 10|2@1+ (1,0) [0|3] "" Vector__XXX
 SG_ BMS_brickVoltageStatus60 m19 : 12|2@1+ (1,0) [0|3] "" Vector__XXX
 SG_ BMS_brickVoltage58 m19 : 16|16@1+ (0.0001,0) [0|5] "V" Vector__XXX
 SG_ BMS_brickVoltage59 m19 : 32|16@1+ (0.0001,0) [0|5] "V" Vector__XXX
 SG_ BMS_brickVoltage60 m19 : 48|16@1+ (0.0001,0) [0|5] "V" Vector__XXX
 SG_ BMS_brickVoltageStatus61 m20 : 8|2@1+ (1,0) [0|3] "" Vector__XXX
 SG_ BMS_brickVoltageStatus62 m20 : 10|2@1+ (1,0) [0|3] "" Vector__XXX
 SG_ BMS_brickVoltageStatus63 m20 : 12|2@1+ (1,0) [0|3] "" Vector__XXX
 SG_ BMS_brickVoltage61 m20 : 16|16@1+ (0.0001,0) [0|5] "V" Vector__XXX
 SG_ BMS_brickVoltage62 m20 : 32|16@1+ (0.0001,0) [0|5] "V" Vector__XXX
 SG_ BMS_brickVoltage63 m20 : 48|16@1+ (0.0001,0) [0|5] "V" Vector__XXX
 SG_ BMS_brickVoltageStatus64 m21 : 8|2@1+ (1,0) [0|3] "" Vector__XXX
 SG_ BMS_brickVoltageStatus65 m21 : 10|2@1+ (1,0) [0|3] "" Vector__XXX
 SG_ BMS_brickVoltageStatus66 m21 : 12|2@1+ (1,0) [0|3] "" Vector__XXX
 SG_ BMS_brickVoltage64 m21 : 16|16@1+ (0.0001,0) [0|5] "V" Vector__XXX
 SG_ BMS_brickVoltage65 m21 : 32|16@1+ (0.0001,0) [0|5] "V" Vector__XXX
 SG_ BMS_brickVoltage66 m21 : 48|16@1+ (0.0001,0) [0|5] "V" Vector__XXX
 SG_ BMS_brickVoltageStatus67 m22 : 8|2@1+ (1,0) [0|3] "" Vector__XXX
 SG_ BMS_brickVoltageStatus68 m22 : 10|2@1+ (1,0) [0|3] "" Vector__XXX
 SG_ BMS_brickVoltageStatus69 m22 : 12|2@1+ (1,0) [0|3] "" Vector__XXX
 SG_ BMS_brickVoltage67 m22 : 16|16@1+ (0.0001,0) [0|5] "V" Vector__XXX
 SG_ BMS_brickVoltage68 m22 : 32|16@1+ (0.0001,0) [0|5] "V" Vector__XXX
 SG_ BMS_brickVoltage69 m22 : 48|16@1+ (0.0001,0) [0|5] "V" Vector__XXX
 SG_ BMS_brickVoltageStatus70 m23 : 8|2@1+ (1,0) [0|3] "" Vector__XXX
 SG_ BMS_brickVoltageStatus71 m23 : 10|2@1+ (1,0) [0|3] "" Vector__XXX
 SG_ BMS_brickVoltageStatus72 m23 : 12|2@1+ (1,0) [0|3] "" Vector__XXX
 SG_ BMS_brickVoltage70 m23 : 16|16@1+ (0.0001,0) [0|5] "V" Vector__XXX
 SG_ BMS_brickVoltage71 m23 : 32|16@1+ (0.0001,0) [0|5] "V" Vector__XXX
 SG_ BMS_brickVoltage72 m23 : 48|16@1+ (0.0001,0) [0|5] "V" Vector__XXX
 SG_ BMS_brickVoltageStatus73 m24 : 8|2@1+ (1,0) [0|3] "" Vector__XXX
 SG_ BMS_brickVoltageStatus74 m24 : 10|2@1+ (1,0) [0|3] "" Vector__XXX
 SG_ BMS_brickVoltageStatus75 m24 : 12|2@1+ (1,0) [0|3] "" Vector__XXX
 SG_ BMS_brickVoltage73 m24 : 16|16@1+ (0.0001,0) [0|5] "V" Vector__XXX
 SG_ BMS_brickVoltage74 m24 : 32|16@1+ (0.0001,0) [0|5] "V" Vector__XXX
 SG_ BMS_brickVoltage75 m24 : 48|16@1+ (0.0001,0) [0|5] "V" Vector__XXX
 SG_ BMS_brickVoltageStatus76 m25 : 8|2@1+ (1,0) [0|3] "" Vector__XXX
 SG_ BMS_brickVoltageStatus77 m25 : 10|2@1+ (1,0) [0|3] "" Vector__XXX
 SG_ BMS_brickVoltageStatus78 m25 : 12|2@1+ (1,0) [0|3] "" Vector__XXX
 SG_ BMS_brickVoltage76 m25 : 16|16@1+ (0.0001,0) [0|5] "V" Vector__XXX
 SG_ BMS_brickVoltage77 m25 : 32|16@1+ (0.0001,0) [0|5] "V" Vector__XXX
 SG_ BMS_brickVoltage78 m25 : 48|16@1+ (0.0001,0) [0|5] "V" Vector__XXX
 SG_ BMS_brickVoltageStatus79 m26 : 8|2@1+ (1,0) [0|3] "" Vector__XXX
 SG_ BMS_brickVoltageStatus80 m26 : 10|2@1+ (1,0) [0|3] "" Vector__XXX
 SG_ BMS_brickVoltageStatus81 m26 : 12|2@1+ (1,0) [0|3] "" Vector__XXX
 SG_ BMS_brickVoltage79 m26 : 16|16@1+ (0.0001,0) [0|5] "V" Vector__XXX
 SG_ BMS_brickVoltage80 m26 : 32|16@1+ (0.0001,0) [0|5] "V" Vector__XXX
 SG_ BMS_brickVoltage81 m26 : 48|16@1+ (0.0001,0) [0|5] "V" Vector__XXX
 SG_ BMS_brickVoltageStatus82 m27 : 8|2@1+ (1,0) [0|3] "" Vector__XXX
 SG_ BMS_brickVoltageStatus83 m27 : 10|2@1+ (1,0) [0|3] "" Vector__XXX
 SG_ BMS_brickVoltageStatus84 m27 : 12|2@1+ (1,0) [0|3] "" Vector__XXX
 SG_ BMS_brickVoltage82 m27 : 16|16@1+ (0.0001,0) [0|5] "V" Vector__XXX
 SG_ BMS_brickVoltage83 m27 : 32|16@1+ (0.0001,0) [0|5] "V" Vector__XXX
 SG_ BMS_brickVoltage84 m27 : 48|16@1+ (0.0001,0) [0|5] "V" Vector__XXX
 SG_ BMS_brickVoltageStatus85 m28 : 8|2@1+ (1,0) [0|3] "" Vector__XXX
 SG_ BMS_brickVoltageStatus86 m28 : 10|2@1+ (1,0) [0|3] "" Vector__XXX
 SG_ BMS_brickVoltageStatus87 m28 : 12|2@1+ (1,0) [0|3] "" Vector__XXX
 SG_ BMS_brickVoltage85 m28 : 16|16@1+ (0.0001,0) [0|5] "V" Vector__XXX
 SG_ BMS_brickVoltage86 m28 : 32|16@1+ (0.0001,0) [0|5] "V" Vector__XXX
 SG_ BMS_brickVoltage87 m28 : 48|16@1+ (0.0001,0) [0|5] "V" Vector__XXX
 SG_ BMS_brickVoltageStatus88 m29 : 8|2@1+ (1,0) [0|3] "" Vector__XXX
 SG_ BMS_brickVoltageStatus89 m29 : 10|2@1+ (1,0) [0|3] "" Vector__XXX
 SG_ BMS_brickVoltageStatus90 m29 : 12|2@1+ (1,0) [0|3] "" Vector__XXX
 SG_ BMS_brickVoltage88 m29 : 16|16@1+ (0.0001,0) [0|5] "V" Vector__XXX
 SG_ BMS_brickVoltage89 m29 : 32|16@1+ (0.0001,0) [0|5] "V" Vector__XXX
 SG_ BMS_brickVoltage90 m29 : 48|16@1+ (0.0001,0) [0|5] "V" Vector__XXX
 SG_ BMS_brickVoltageStatus91 m30 : 8|2@1+ (1,0) [0|3] "" Vector__XXX
 SG_ BMS_brickVoltageStatus92 m30 : 10|2@1+ (1,0) [0|3] "" Vector__XXX
 SG_ BMS_brickVoltageStatus93 m30 : 12|2@1+ (1,0) [0|3] "" Vector__XXX
 SG_ BMS_brickVoltage91 m30 : 16|16@1+ (0.0001,0) [0|5] "V" Vector__XXX
 SG_ BMS_brickVoltage92 m30 : 32|16@1+ (0.0001,0) [0|5] "V" Vector__XXX
 SG_ BMS_brickVoltage93 m30 : 48|16@1+ (0.0001,0) [0|5] "V" Vector__XXX
 SG_ BMS_brickVoltageStatus94 m31 : 8|2@1+ (1,0) [0|3] "" Vector__XXX
 SG_ BMS_brickVoltageStatus95 m31 : 10|2@1+ (1,0) [0|3] "" Vector__XXX
 SG_ BMS_brickVoltageStatus96 m31 : 12|2@1+ (1,0) [0|3] "" Vector__XXX
 SG_ BMS_brickVoltage94 m31 : 16|16@1+ (0.0001,0) [0|5] "V" Vector__XXX
 SG_ BMS_brickVoltage95 m31 : 32|16@1+ (0.0001,0) [0|5] "V" Vector__XXX
 SG_ BMS_brickVoltage96 m31 : 48|16@1+ (0.0001,0) [0|5] "V" Vector__XXX
 SG_ BMS_brickVoltageStatus97 m32 : 8|2@1+ (1,0) [0|3] "" Vector__XXX
 SG_ BMS_brickVoltageStatus98 m32 : 10|2@1+ (1,0) [0|3] "" Vector__XXX
 SG_ BMS_brickVoltageStatus99 m32 : 12|2@1+ (1,0) [0|3] "" Vector__XXX
 SG_ BMS_brickVoltage97 m32 : 16|16@1+ (0.0001,0) [0|5] "V" Vector__XXX
 SG_ BMS_brickVoltage98 m32 : 32|16@1+ (0.0001,0) [0|5] "V" Vector__XXX
 SG_ BMS_brickVoltage99 m32 : 48|16@1+ (0.0001,0) [0|5] "V" Vector__XXX
 SG_ BMS_brickVoltageStatus100 m33 : 8|2@1+ (1,0) [0|3] "" Vector__XXX
 SG_ BMS_brickVoltageStatus101 m33 : 10|2@1+ (1,0) [0|3] "" Vector__XXX
 SG_ BMS_brickVoltageStatus102 m33 : 12|2@1+ (1,0) [0|3] "" Vector__XXX
 SG_ BMS_brickVoltage100 m33 : 16|16@1+ (0.0001,0) [0|5] "V" Vector__XXX
 SG_ BMS_brickVoltage101 m33 : 32|16@1+ (0.0001,0) [0|5] "V" Vector__XXX
 SG_ BMS_brickVoltage102 m33 : 48|16@1+ (0.0001,0) [0|5] "V" Vector__XXX
 SG_ BMS_brickVoltageStatus103 m34 : 8|2@1+ (1,0) [0|3] "" Vector__XXX
 SG_ BMS_brickVoltageStatus104 m34 : 10|2@1+ (1,0) [0|3] "" Vector__XXX
 SG_ BMS_brickVoltageStatus105 m34 : 12|2@1+ (1,0) [0|3] "" Vector__XXX
 SG_ BMS_brickVoltage103 m34 : 16|16@1+ (0.0001,0) [0|5] "V" Vector__XXX
 SG_ BMS_brickVoltage104 m34 : 32|16@1+ (0.0001,0) [0|5] "V" Vector__XXX
 SG_ BMS_brickVoltage105 m34 : 48|16@1+ (0.0001,0) [0|5] "V" Vector__XXX
 SG_ BMS_brickVoltageStatus106 m35 : 8|2@1+ (1,0) [0|3] "" Vector__XXX
 SG_ BMS_brickVoltageStatus107 m35 : 10|2@1+ (1,0) [0|3] "" Vector__XXX
 SG_ BMS_brickVoltageStatus108 m35 : 12|2@1+ (1,0) [0|3] "" Vector__XXX
 SG_ BMS_brickVoltage106 m35 : 16|16@1+ (0.0001,0) [0|5] "V" Vector__XXX
 SG_ BMS_brickVoltage107 m35 : 32|16@1+ (0.0001,0) [0|5] "V" Vector__XXX
 SG_ BMS_brickVoltage108 m35 : 48|16@1+ (0.0001,0) [0|5] "V" Vector__XXX

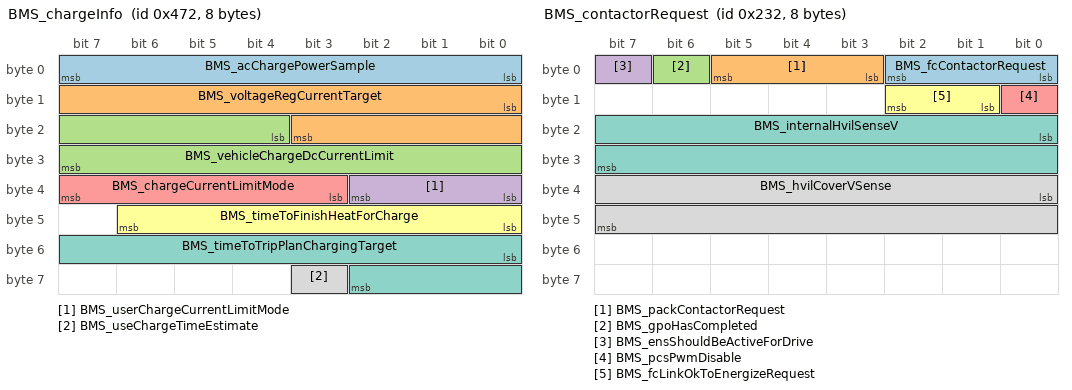
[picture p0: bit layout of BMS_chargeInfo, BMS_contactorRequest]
BO_ 1138 BMS_chargeInfo: 8 BMS
 SG_ BMS_acChargePowerSample : 0|8@1+ (0.1,0) [0|25] "kW" Vector__XXX
 SG_ BMS_voltageRegCurrentTarget : 8|12@1+ (0.5,0) [0|2047.5] "A" Vector__XXX
 SG_ BMS_vehicleChargeDcCurrentLimit : 20|12@1+ (0.5,0) [0|2047.5] "A" Vector__XXX
 SG_ BMS_userChargeCurrentLimitMode : 32|3@1+ (1,0) [0|7] "" Vector__XXX
 SG_ BMS_chargeCurrentLimitMode : 35|5@1+ (1,0) [0|31] "" Vector__XXX
 SG_ BMS_timeToFinishHeatForCharge : 40|7@1+ (5,0) [0|600] "min" Vector__XXX
 SG_ BMS_timeToTripPlanChargingTarget : 48|11@1+ (1,0) [0|2046] "min" Vector__XXX
 SG_ BMS_useChargeTimeEstimate : 59|1@1+ (1,0) [0|1] "" Vector__XXX

BO_ 562 BMS_contactorRequest: 8 BMS
 SG_ BMS_fcContactorRequest : 0|3@1+ (1,0) [0|7] "" Vector__XXX
 SG_ BMS_packContactorRequest : 3|3@1+ (1,0) [0|7] "" Vector__XXX
 SG_ BMS_gpoHasCompleted : 6|1@1+ (1,0) [0|1] "" Vector__XXX
 SG_ BMS_ensShouldBeActiveForDrive : 7|1@1+ (1,0) [0|1] "" Vector__XXX
 SG_ BMS_pcsPwmDisable : 8|1@1+ (1,0) [0|1] "" Vector__XXX
 SG_ BMS_fcLinkOkToEnergizeRequest : 9|2@1+ (1,0) [0|3] "" Vector__XXX
 SG_ BMS_internalHvilSenseV : 16|16@1+ (0.001,0) [0|65.534] "V" Vector__XXX
 SG_ BMS_hvilCoverVSense : 32|16@1+ (0.001,0) [0|65.534] "V" Vector__XXX

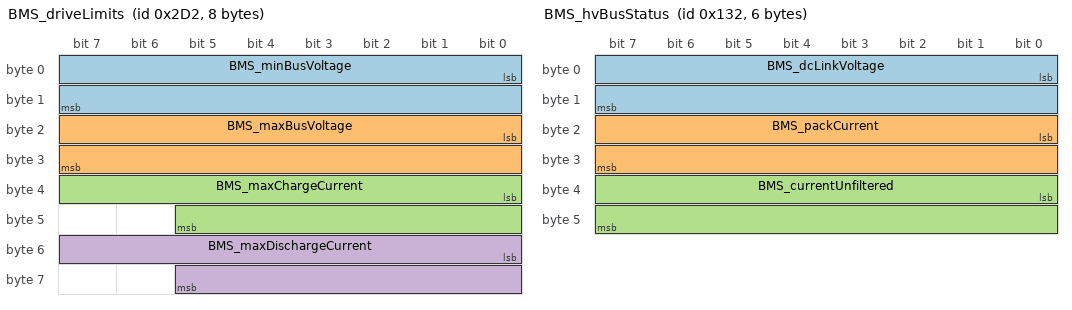
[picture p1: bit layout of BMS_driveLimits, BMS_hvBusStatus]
BO_ 722 BMS_driveLimits: 8 BMS
 SG_ BMS_minBusVoltage : 0|16@1+ (0.02,0) [0|1200] "V" Vector__XXX
 SG_ BMS_maxBusVoltage : 16|16@1+ (0.02,0) [0|1200] "V" Vector__XXX
 SG_ BMS_maxChargeCurrent : 32|14@1+ (0.1,0) [0|1638.2] "A" Vector__XXX
 SG_ BMS_maxDischargeCurrent : 48|14@1+ (0.15,0) [0|2455] "A" Vector__XXX

BO_ 690 BMS_energyStatus: 8 BMS
 SG_ BMS_energyStatusMultiplexer M : 0|2@1+ (1,0) [0|3] "" Vector__XXX
 SG_ BMS_nominalFullPackEnergy m0 : 16|16@1+ (0.02,0) [0|1310.68] "kWh" Vector__XXX
 SG_ BMS_nominalEnergyRemaining m0 : 32|16@1+ (0.02,0) [0|1310.68] "kWh" Vector__XXX
 SG_ BMS_idealEnergyRemaining m0 : 48|16@1+ (0.02,0) [0|1310.68] "kWh" Vector__XXX
 SG_ BMS_fullChargeComplete m1 : 15|1@1+ (1,0) [0|1] "" Vector__XXX
 SG_ BMS_energyBuffer m1 : 16|16@1+ (0.01,0) [0|655.34] "kWh" Vector__XXX
 SG_ BMS_expectedEnergyRemaining m1 : 32|16@1+ (0.02,0) [0|1310.68] "kWh" Vector__XXX
 SG_ BMS_energyToChargeComplete m1 : 48|16@1+ (0.02,0) [0|1310.68] "kWh" Vector__XXX
 SG_ BMS_energyRemainingDisplay m2 : 8|16@1+ (0.02,0) [0|1310.68] "kWh" Vector__XXX
 SG_ BMS_energyRemainingTDisplay m2 : 24|16@1+ (0.02,0) [0|1310.68] "kWh" Vector__XXX
 SG_ BMS_energyDisplayErrorBlendRate m2 : 40|12@1+ (0.0156288165599,0) [0|64] "%" Vector__XXX
 SG_ BMS_userFacingSoe m2 : 52|11@1+ (0.05,0) [0|100] "%" Vector__XXX

BO_ 306 BMS_hvBusStatus: 6 BMS
 SG_ BMS_dcLinkVoltage : 0|16@1+ (0.01,0) [0|655.35] "V" Vector__XXX
 SG_ BMS_packCurrent : 16|16@1- (0.1,0) [-3276.7|3276.7] "A" Vector__XXX
 SG_ BMS_currentUnfiltered : 32|16@1- (0.05,-822) [-2460.3|816.3] "A" Vector__XXX

BO_ 768 BMS_info: 8 BMS
 SG_ BMS_infoIndex M : 0|8@1+ (1,0) [0|255] "" Vector__XXX
 SG_ BMS_buildType m10 : 8|3@1+ (1,0) [0|7] "" Vector__XXX
 SG_ BMS_buildConfigId m10 : 16|16@1+ (1,0) [0|65535] "" Vector__XXX
 SG_ BMS_hardwareId m10 : 32|16@1+ (1,0) [0|65535] "" Vector__XXX
 SG_ BMS_componentId m10 : 48|16@1+ (1,0) [0|65535] "" Vector__XXX
 SG_ BMS_pcbaId m11 : 16|8@1+ (1,0) [0|255] "" Vector__XXX
 SG_ BMS_assemblyId m11 : 24|8@1+ (1,0) [0|255] "" Vector__XXX
 SG_ BMS_usageId m11 : 32|16@1+ (1,0) [0|65535] "" Vector__XXX
 SG_ BMS_subUsageId m11 : 48|16@1+ (1,0) [0|65535] "" Vector__XXX
 SG_ BMS_platformType m13 : 8|8@1+ (1,0) [0|255] "" Vector__XXX
 SG_ BMS_appCrc m13 : 32|32@1+ (1,0) [0|4294967295] "" Vector__XXX
 SG_ BMS_appGitHash m17 : 8|56@1+ (1,0) [0|7.20575940379e+16] "" Vector__XXX
 SG_ BMS_bootGitHash m18 : 8|56@1+ (1,0) [0|7.20575940379e+16] "" Vector__XXX
 SG_ BMS_bootUdsProtoVersion m20 : 8|8@1+ (1,0) [0|255] "" Vector__XXX
 SG_ BMS_bootCrc m20 : 32|32@1+ (1,0) [0|4294967295] "" Vector__XXX

BO_ 978 BMS_kwhCounter: 8 BMS
 SG_ BMS_kwhDischargeTotal : 0|32@1+ (0.001,0) [0|268435.456] "KWh" Vector__XXX
 SG_ BMS_kwhChargeTotal : 32|32@1+ (0.001,0) [0|268435.456] "KWh" Vector__XXX

BO_ 1010 BMS_kwhCountersMultiplexed: 8 BMS
 SG_ BMS_kwhCounter_Id M : 0|4@1+ (1,0) [0|15] "" Vector__XXX
 SG_ BMS_acChargerKwhTotal m0 : 8|32@1+ (0.001,0) [0|268435.456] "KWh" Vector__XXX
 SG_ BMS_dcChargerKwhTotal m1 : 8|32@1+ (0.001,0) [0|268435.456] "KWh" Vector__XXX
 SG_ BMS_kwhRegenChargeTotal m2 : 8|32@1+ (0.001,0) [0|268435.456] "KWh" Vector__XXX
 SG_ BMS_kwhDriveDischargeTotal m3 : 8|32@1+ (0.001,0) [0|268435.456] "KWh" Vector__XXX
 SG_ BMS_kwhDischargeTotalModule1 m4 : 8|28@1+ (0.001,0) [0|268435.455] "KWh" Vector__XXX
 SG_ BMS_kwhChargeTotalModule1 m4 : 36|28@1+ (0.001,0) [0|268435.455] "KWh" Vector__XXX
 SG_ BMS_kwhAcChargeTotalModule1 m5 : 8|28@1+ (0.001,0) [0|268435.455] "KWh" Vector__XXX
 SG_ BMS_kwhDcChargeTotalModule1 m5 : 36|28@1+ (0.001,0) [0|268435.455] "KWh" Vector__XXX
 SG_ BMS_kwhDischargeTotalModule2 m6 : 8|28@1+ (0.001,0) [0|268435.455] "KWh" Vector__XXX
 SG_ BMS_kwhChargeTotalModule2 m6 : 36|28@1+ (0.001,0) [0|268435.455] "KWh" Vector__XXX
 SG_ BMS_kwhAcChargeTotalModule2 m7 : 8|28@1+ (0.001,0) [0|268435.455] "KWh" Vector__XXX
 SG_ BMS_kwhDcChargeTotalModule2 m7 : 36|28@1+ (0.001,0) [0|268435.455] "KWh" Vector__XXX
 SG_ BMS_kwhDischargeTotalModule3 m8 : 8|28@1+ (0.001,0) [0|268435.455] "KWh" Vector__XXX
 SG_ BMS_kwhChargeTotalModule3 m8 : 36|28@1+ (0.001,0) [0|268435.455] "KWh" Vector__XXX
 SG_ BMS_kwhAcChargeTotalModule3 m9 : 8|28@1+ (0.001,0) [0|268435.455] "KWh" Vector__XXX
 SG_ BMS_kwhDcChargeTotalModule3 m9 : 36|28@1+ (0.001,0) [0|268435.455] "KWh" Vector__XXX
 SG_ BMS_kwhDischargeTotalModule4 m10 : 8|28@1+ (0.001,0) [0|268435.455] "KWh" Vector__XXX
 SG_ BMS_kwhChargeTotalModule4 m10 : 36|28@1+ (0.001,0) [0|268435.455] "KWh" Vector__XXX
 SG_ BMS_kwhAcChargeTotalModule4 m11 : 8|28@1+ (0.001,0) [0|268435.455] "KWh" Vector__XXX
 SG_ BMS_kwhDcChargeTotalModule4 m11 : 36|28@1+ (0.001,0) [0|268435.455] "KWh" Vector__XXX

BO_ 884 BMS_log1: 8 BMS
 SG_ BMS_log1MuxId M : 0|8@1+ (1,0) [0|255] "" Vector__XXX
 SG_ BMS_powerTransferStatus m4 : 16|4@1+ (1,0) [0|15] "" Vector__XXX
 SG_ BMS_extDcPrechargeVoltageLimit m4 : 20|12@1+ (0.146502256393,0) [0|599.926739929] "V" Vector__XXX
 SG_ BMS_dcChargeCurrentRequest m4 : 32|14@1- (0.25,0) [-2048|2047.75] "A" Vector__XXX
 SG_ BMS_dcChargeCurrentLimit m4 : 46|13@1- (0.5,0) [-2048|2047.5] "A" Vector__XXX
 SG_ BMS_dcDischargeEnabled m4 : 59|1@1+ (1,0) [0|1] "" Vector__XXX
 SG_ BMS_rippleChargeRetryCount m4 : 60|3@1+ (1,0) [0|7] "" Vector__XXX
 SG_ BMS_dcChargeVoltageLimit m5 : 8|12@1+ (0.146502256393,0) [0|599.926739929] "V" Vector__XXX
 SG_ BMS_dcChargePowerLimit m5 : 20|12@1- (1,0) [-2048|2047] "kW" Vector__XXX
 SG_ BMS_acRealPowerRequest m5 : 32|16@1- (0.002,0) [-40|40] "kW" Vector__XXX
 SG_ BMS_maxExtIsoFcLinkV m5 : 48|13@1+ (0.134293735027,0) [0|1099.99998361] "V" Vector__XXX
 SG_ BMS_minModeledPackTemp m6 : 8|11@1+ (0.1,-50) [-50|154.7] "C" Vector__XXX
 SG_ BMS_maxModeledPackTemp m6 : 19|11@1+ (0.1,-50) [-50|154.7] "C" Vector__XXX
 SG_ BMS_energyMaxPredictedBrickTemp m13 : 8|8@1+ (1,-50) [-50|205] "C" Vector__XXX
 SG_ BMS_energyTempGradientAtMaxTemp m13 : 16|9@1+ (0.1,0) [0|51.1] "C" Vector__XXX
 SG_ BMS_energyWalkMaxSoc m13 : 25|10@1+ (0.1,0) [0|102.3] "%" Vector__XXX
 SG_ BMS_energyWalkMinSoc m13 : 35|10@1+ (0.1,0) [0|102.3] "%" Vector__XXX
 SG_ BMS_chargeEnergyWalkState m13 : 45|2@1+ (1,0) [0|3] "" Vector__XXX
 SG_ BMS_packVoltage m13 : 48|16@1+ (0.01,0) [0|655.35] "V" Vector__XXX
 SG_ BMS_energyWalkMaxPackCurrent m14 : 8|16@1- (0.1,0) [-3276.7|3276.7] "A" Vector__XXX
 SG_ BMS_energyWalkMaxVehiclePower m14 : 24|11@1- (1,500) [-524|1523] "kW" Vector__XXX
 SG_ BMS_battTempPct m14 : 35|8@1+ (0.4,0) [0|100] "%" Vector__XXX
 SG_ BMS_powerTransferDisableType m14 : 43|2@1+ (1,0) [0|3] "" Vector__XXX
 SG_ BMS_powerTransferDisableReason m14 : 45|6@1+ (1,0) [0|63] "" Vector__XXX
 SG_ BMS_powerTransferWaitCondition m14 : 51|6@1+ (1,0) [0|63] "" Vector__XXX
 SG_ BMS_dischargeRetryCount m14 : 57|3@1+ (1,0) [0|7] "" Vector__XXX
 SG_ BMS_acChargeDesired m14 : 60|1@1+ (1,0) [0|1] "" Vector__XXX
 SG_ BMS_tetheringDesired m14 : 61|1@1+ (1,0) [0|1] "" Vector__XXX
 SG_ BMS_gridFormDesired m14 : 62|1@1+ (1,0) [0|1] "" Vector__XXX
 SG_ BMS_gridFollowDesired m14 : 63|1@1+ (1,0) [0|1] "" Vector__XXX

BO_ 946 BMS_log2: 8 BMS
 SG_ BMS_log2MuxId M : 0|7@1+ (1,0) [0|127] "" Vector__XXX
 SG_ BMS_maxChargeRestartNeededByVolt m0 : 7|1@1+ (1,0) [0|1] "" Vector__XXX
 SG_ BMS_cacAvg m0 : 8|13@1+ (0.1,0) [0|819.1] "Ah" Vector__XXX
 SG_ BMS_maxChargeNearComplete m0 : 21|1@1+ (1,0) [0|1] "" Vector__XXX
 SG_ BMS_cacMin m0 : 24|13@1+ (0.1,0) [0|819.1] "Ah" Vector__XXX
 SG_ BMS_cacMinBrickId m0 : 37|7@1+ (1,1) [1|128] "" Vector__XXX
 SG_ BMS_cacMax m0 : 44|13@1+ (0.1,0) [0|819.1] "Ah" Vector__XXX
 SG_ BMS_cacMaxBrickId m0 : 57|7@1+ (1,1) [1|128] "" Vector__XXX
 SG_ BMS_acRippleConfigNvramValid m18 : 7|1@1+ (1,0) [0|1] "" Vector__XXX
 SG_ BMS_hvChain_useLeakyBucket m18 : 8|1@1+ (1,0) [0|1] "" Vector__XXX
 SG_ BMS_hvChain_iLimit m18 : 9|14@1+ (0.2,0) [0|3275] "A" Vector__XXX
 SG_ BMS_hvChain_limitingState m18 : 23|9@1+ (1,1) [1|511] "" Vector__XXX
 SG_ BMS_hvChain_limitingStateTempera m18 : 32|13@1- (0.1,367.6) [-40|775] "DegC" Vector__XXX
 SG_ BMS_acRippleIsSupported m18 : 45|1@1+ (1,0) [0|1] "" Vector__XXX
 SG_ BMS_acRippleStartTemperatureMax m18 : 46|9@1+ (0.25,-25) [-25|100] "DegC" Vector__XXX
 SG_ BMS_acRippleStartTemperatureMin m18 : 55|9@1+ (0.25,-25) [-25|100] "DegC" Vector__XXX
 SG_ BMS_fcLinkTestDecayTime m20 : 8|10@1+ (2,0) [0|2044] "mS" Vector__XXX
 SG_ BMS_fcLinkTestTimeSinceLastRun m20 : 18|12@1+ (0.0175824183971,0) [0|71.99] "Hours" Vector__XXX
 SG_ BMS_pcsPrechargeRequest m20 : 30|2@1+ (1,0) [0|3] "" Vector__XXX
 SG_ BMS_pcsPrechargeTargetVoltage m20 : 32|16@1- (0.1,0) [-3276.8|3276.7] "V" Vector__XXX
 SG_ BMS_recentOvUvAlert m20 : 48|1@1+ (1,0) [0|1] "" Vector__XXX
 SG_ BMS_recentIsoAlert m20 : 49|1@1+ (1,0) [0|1] "" Vector__XXX
 SG_ BMS_recentBmbMiaAlert m20 : 50|1@1+ (1,0) [0|1] "" Vector__XXX
 SG_ BMS_cacBlendingConfigNvramValid m20 : 51|1@1+ (1,0) [0|1] "" Vector__XXX
 SG_ BMS_cacBlendingEnabled m20 : 52|1@1+ (1,0) [0|1] "" Vector__XXX
 SG_ BMS_cacBlendPercentPerCycle m20 : 53|10@1+ (0.001,0) [0|1.023] "%" Vector__XXX
 SG_ BMS_energyVariableChgRequested m21 : 8|1@1+ (1,0) [0|1] "" Vector__XXX
 SG_ BMS_packRestTime m21 : 9|12@1+ (0.0175824183971,0) [0|71.99] "Hours" Vector__XXX
 SG_ BMS_idealEnergyFloor m21 : 21|10@1+ (0.1,0) [0|102.2] "KWh" Vector__XXX
 SG_ BMS_thmGradientSlopeCondition m21 : 31|1@1+ (1,0) [0|1] "" Vector__XXX
 SG_ BMS_recentSlopeConditon m21 : 32|1@1+ (1,0) [0|1] "" Vector__XXX
 SG_ BMS_dynamicEnergyBuffer m21 : 33|10@1+ (0.1,0) [0|102.2] "KWh" Vector__XXX
 SG_ BMS_temperatureCondition m21 : 43|1@1+ (1,0) [0|1] "" Vector__XXX
 SG_ BMS_thmGradientSlope m21 : 44|10@1- (0.01,0) [-5.12|5.11] "C/min" Vector__XXX
 SG_ BMS_thmGradient m21 : 56|8@1+ (0.1,0) [0|25.5] "C" Vector__XXX
 SG_ BMS_epochTimeEstimate m29 : 8|32@1+ (1,0) [0|4294967295] "s" Vector__XXX
 SG_ BMS_histogramStartTimeIrrational m30 : 57|1@1+ (1,0) [0|1] "" Vector__XXX
 SG_ BMS_histogramDischargeThroughput m30 : 58|1@1+ (1,0) [0|1] "" Vector__XXX
 SG_ BMS_histogramChargeThroughputIrr m30 : 59|1@1+ (1,0) [0|1] "" Vector__XXX
 SG_ BMS_histogramTotalTimeIrrational m30 : 60|1@1+ (1,0) [0|1] "" Vector__XXX
 SG_ BMS_histogramStorageDataIsLow m30 : 61|1@1+ (1,0) [0|1] "" Vector__XXX
 SG_ BMS_tempVsSocTotalChgEnergy m31 : 7|25@1+ (0.000149011611938,0) [0|4999.99985097] "wh/wh" Vector__XXX
 SG_ BMS_powerVsVoltageTotalChgEnergy m31 : 32|25@1+ (0.000149011611938,0) [0|4999.99985097] "wh/wh" Vector__XXX
 SG_ BMS_lifeModelOutputsAreTrustwort m31 : 57|1@1+ (1,0) [0|1] "" Vector__XXX
 SG_ BMS_dSocNormalizedMin m33 : 8|12@1+ (0.0030517578125,-12.4969482422) [-12.4969482422|-0.003051757825] "%" Vector__XXX
 SG_ BMS_dSocNormalizedFiltMin m33 : 20|12@1+ (0.0030517578125,-12.4969482422) [-12.4969482422|-0.003051757825] "%" Vector__XXX
 SG_ BMS_dSocMinAlpha m33 : 32|12@1+ (0.0030517578125,-12.4969482422) [-12.4969482422|-0.003051757825] "%" Vector__XXX
 SG_ BMS_dSocMaxLowAlphaCounter m33 : 44|4@1+ (1,0) [0|15] "" Vector__XXX
 SG_ BMS_dSocMinAlphaBrickID m33 : 48|7@1+ (1,1) [1|128] "" Vector__XXX
 SG_ BMS_dSocCacMargin m33 : 55|9@1+ (0.0030517578125,0) [0|1.55639648438] "%" Vector__XXX
 SG_ BMS_lifeModelNoCurrentStorageCap m54 : 7|9@1+ (0.1,0) [0|51] "%" Vector__XXX
 SG_ BMS_lifeModelShortDcr m54 : 16|8@1+ (0.01,0) [0|2.54] "mOhm" Vector__XXX
 SG_ BMS_lifeModelLongDcr m54 : 24|13@1- (0.1,309.6) [-100|719] "mOhm" Vector__XXX
 SG_ BMS_lifeModelStorageCapacityLoss m54 : 37|9@1+ (0.1,0) [0|51] "%" Vector__XXX
 SG_ BMS_lifeModelThroughputCapacityL m54 : 46|9@1+ (0.1,0) [0|51] "%" Vector__XXX
 SG_ BMS_passiveCoolCellTargetT m54 : 55|9@1+ (0.25,-25) [-25|100] "DegC" Vector__XXX
 SG_ BMS_lifeModelAvgTempSeverity m55 : 8|5@1+ (0.1,0) [0|3] "-" Vector__XXX
 SG_ BMS_lifeModelDepthOfDischargeSev m55 : 16|8@1+ (0.01,0) [0|1.5] "-" Vector__XXX
 SG_ BMS_lifeModelHistogramCapacityLo m55 : 24|9@1+ (0.1,0) [0|51] "%" Vector__XXX
 SG_ BMS_lifeModelHistogramBrickCapac m55 : 33|13@1+ (0.1,0) [0|819] "Ah" Vector__XXX
 SG_ BMS_lifeModelDcrGrowthPercent m55 : 48|14@1- (0.1,200) [-100|500] "%" Vector__XXX
 SG_ BMS_nominalFullPackEnergyRaw m56 : 8|16@1+ (0.02,0) [0|1310.68] "kWh" Vector__XXX
 SG_ BMS_nominalEnergyRemainingBuffer m56 : 24|16@1+ (0.02,0) [0|1310.68] "kWh" Vector__XXX
 SG_ BMS_idealEnergyRemainingBuffered m56 : 40|16@1+ (0.02,0) [0|1310.68] "kWh" Vector__XXX
 SG_ BMS_largestSynchronizedCacErrorP m56 : 56|8@1+ (0.1,0) [0|25.4] "%" Vector__XXX
 SG_ BMS_lifeModelSpreadMinOffset m60 : 8|10@1- (0.1,0) [-51.1|51.1] "Ah" Vector__XXX
 SG_ BMS_lifeModelSpreadMaxOffset m60 : 18|10@1- (0.1,0) [-51.1|51.1] "Ah" Vector__XXX
 SG_ BMS_largestCacSpreadErrorLower m64 : 8|12@1+ (0.1,0) [0|409.4] "Ah" Vector__XXX
 SG_ BMS_lifeModelAverageCac m64 : 20|12@1+ (0.1,0) [0|409.4] "Ah" Vector__XXX
 SG_ BMS_lifeModelCacBrick1 m64 : 32|12@1+ (0.1,0) [0|409.4] "Ah" Vector__XXX
 SG_ BMS_lifeModelAverageOffset m64 : 44|10@1- (0.1,0) [-51.1|51.1] "Ah" Vector__XXX
 SG_ BMS_percentCacUpdatesInTimeWindo m64 : 54|10@1+ (0.1,0) [0|100] "%" Vector__XXX
 SG_ BMS_lifeModelMaxCacBrickId m65 : 8|8@1+ (1,1) [1|255] "" Vector__XXX
 SG_ BMS_lifeModelMaxCac m65 : 16|12@1+ (0.1,0) [0|409.4] "Ah" Vector__XXX
 SG_ BMS_lifeModelMinCacBrickId m65 : 28|8@1+ (1,1) [1|255] "" Vector__XXX
 SG_ BMS_lifeModelMinCac m65 : 36|12@1+ (0.1,0) [0|409.4] "Ah" Vector__XXX
 SG_ BMS_restingPointCacAvg m65 : 48|12@1+ (0.1,0) [0|409.4] "Ah" Vector__XXX
 SG_ BMS_cacEstimationSource m65 : 60|2@1+ (1,0) [0|3] "" Vector__XXX
 SG_ BMS_packCalibrationBirthDateBinn m67 : 26|32@1+ (1,0) [0|4294967295] "" Vector__XXX
 SG_ BMS_synchronizedCacMaxRaw m71 : 8|12@1+ (0.1,0) [0|409.4] "Ah" Vector__XXX
 SG_ BMS_synchronizedCacMinRaw m71 : 20|12@1+ (0.1,0) [0|409.4] "Ah" Vector__XXX
 SG_ BMS_largestSyncCacErrorStartSoc m71 : 32|10@1+ (0.1,0) [0|102.2] "%" Vector__XXX
 SG_ BMS_largestSyncCacErrorEndSoc m71 : 42|10@1+ (0.1,0) [0|102.2] "%" Vector__XXX
 SG_ BMS_runtimeSocConfigNvramValid m71 : 52|1@1+ (1,0) [0|1] "" Vector__XXX
 SG_ BMS_runtimeSocCorrectionsEnabled m71 : 53|1@1+ (1,0) [0|1] "" Vector__XXX
 SG_ BMS_rubberBandingEnabled m71 : 54|1@1+ (1,0) [0|1] "" Vector__XXX
 SG_ BMS_rubberBandingConfigNvramVali m71 : 55|1@1+ (1,0) [0|1] "" Vector__XXX
 SG_ BMS_runtimeSocMinTempForModel m71 : 56|6@1+ (0.5,0) [0|20] "DegC" Vector__XXX
 SG_ BMS_energyBufferConfigNvramValid m71 : 62|1@1+ (1,0) [0|1] "" Vector__XXX
 SG_ BMS_thermalEvent1pDetectConfigDi m71 : 63|1@1+ (1,0) [0|1] "" Vector__XXX
 SG_ BMS_sohEnergy m79 : 8|11@1+ (0.1,0) [0|204.6] "KWh" Vector__XXX
 SG_ BMS_fullCapacitySohEnergy m79 : 19|11@1+ (0.1,0) [0|204.6] "KWh" Vector__XXX
 SG_ BMS_calibratedCapacitySohEnergy m79 : 30|11@1+ (0.1,0) [0|204.6] "KWh" Vector__XXX
 SG_ BMS_estimatedCapacitySohEnergy m79 : 41|11@1+ (0.1,0) [0|204.6] "KWh" Vector__XXX
 SG_ BMS_prevUserFacingSohEnergy m79 : 52|11@1+ (0.1,0) [0|204.6] "KWh" Vector__XXX
 SG_ BMS_stateOfHealthMinCac m80 : 8|13@1+ (0.1,0) [0|819] "Ah" Vector__XXX
 SG_ BMS_lifeModelStorageLossPackAge m80 : 24|14@1+ (1,0) [0|16382] "days" Vector__XXX
 SG_ BMS_lifeModelThroughputDcrCycleC m80 : 38|12@1+ (1,0) [0|4094] "Cycles" Vector__XXX
 SG_ BMS_stateOfHealthMinCacLowerBoun m80 : 50|13@1+ (0.1,0) [0|819] "Ah" Vector__XXX
 SG_ BMS_energyWalkCounter m83 : 8|8@1+ (1,0) [0|255] "" Vector__XXX
 SG_ BMS_energyWalkTimeoutCounter m83 : 16|8@1+ (1,0) [0|255] "" Vector__XXX
 SG_ BMS_dynamicCcvEnabled m83 : 24|1@1+ (1,0) [0|1] "" Vector__XXX
 SG_ BMS_chargeTargetLookupSoc m83 : 25|10@1+ (0.1,0) [0|102.2] "%" Vector__XXX
 SG_ BMS_stateOfHealth m83 : 35|10@1+ (0.1,0) [0|100] "%" Vector__XXX
 SG_ BMS_avgShuntAsicCurrentOffset m83 : 48|15@1- (0.2,0) [-3276.6|3276.6] "mA" Vector__XXX
 SG_ BMS_cellAttributesGeneralAttribu m85 : 7|32@1+ (1,0) [1|4294967295] "" Vector__XXX
 SG_ BMS_cellAttributesPackManufactur m85 : 39|3@1+ (1,0) [1|7] "" Vector__XXX
 SG_ BMS_cellAttributesRemanufactured m85 : 42|1@1+ (1,0) [0|1] "" Vector__XXX
 SG_ BMS_cellAttributesConfigNvramVal m85 : 43|1@1+ (1,0) [0|1] "" Vector__XXX
 SG_ BMS_cellAttributesCellType m85 : 44|6@1+ (1,0) [1|63] "" Vector__XXX
 SG_ BMS_cellAttributesAutocloseAndSc m85 : 50|1@1+ (1,0) [0|1] "" Vector__XXX
 SG_ BMS_cellAttributesShipPackForFai m85 : 51|1@1+ (1,0) [0|1] "" Vector__XXX
 SG_ BMS_lifeModelThroughputCycleCoun m85 : 52|12@1+ (1,0) [0|4094] "Cycles" Vector__XXX
 SG_ BMS_limpChargeCurrentLimit m89 : 8|10@1+ (1,0) [0|1022] "A" Vector__XXX
 SG_ BMS_energyRemainingDisplayError m89 : 18|10@1- (0.1,0) [-50|50] "kWh" Vector__XXX
 SG_ BMS_energyRemainingTDisplayError m89 : 28|10@1- (0.1,0) [-50|50] "kWh" Vector__XXX
 SG_ BMS_numOfThermistors m89 : 38|5@1+ (1,0) [0|31] "" Vector__XXX
 SG_ BMS_numOfBricks m89 : 43|8@1+ (1,0) [0|255] "" Vector__XXX
 SG_ BMS_cellChargeDcCurrentLimit m89 : 51|12@1+ (0.5,0) [0|2047.5] "A" Vector__XXX
 SG_ BMS_socByDeltaVEnabled m90 : 8|1@1+ (1,0) [0|1] "" Vector__XXX
 SG_ BMS_socByDvMaxSocLimit m90 : 9|10@1+ (0.1,0) [0|102.2] "%" Vector__XXX
 SG_ BMS_socByDvVoltageChangeOverAh m90 : 19|9@1+ (0.002,0) [0|1] "V" Vector__XXX
 SG_ BMS_socByDvMaxSocByAhCorrected m90 : 28|10@1+ (0.1,0) [0|102.2] "%" Vector__XXX
 SG_ BMS_socByDvMaxBrickVoltage m90 : 40|12@1+ (0.002,0) [0|5] "V" Vector__XXX
 SG_ BMS_socByDvMaxBrickId m90 : 56|8@1+ (1,1) [1|256] "" Vector__XXX
 SG_ BMS_socByDvMaxSocByAhRaw m91 : 8|10@1+ (0.1,0) [0|102.2] "%" Vector__XXX
 SG_ BMS_voltageInstabilityExcessNois m91 : 18|12@1+ (0.1,0) [0|408] "counts" Vector__XXX
 SG_ BMS_maxModelThermistorTempDelta m91 : 30|10@1- (0.1,0) [-51.2|51.1] "C" Vector__XXX
 SG_ BMS_activeCoolCellTargetT m91 : 40|9@1+ (0.25,-25) [-25|100] "DegC" Vector__XXX
 SG_ BMS_cellTempTargetMode m91 : 49|4@1+ (1,0) [0|15] "" Vector__XXX
 SG_ BMS_minPackTempForChargeToStart m91 : 56|7@1+ (0.5,-40) [-40|23.5] "C" Vector__XXX

BO_ 914 BMS_packConfig: 8 BMS
 SG_ BMS_packConfigMultiplexer M : 0|8@1+ (1,0) [0|255] "" Vector__XXX
 SG_ BMS_reservedConfig_0 m0 : 8|6@1+ (1,0) [0|63] "" Vector__XXX
 SG_ BMS_moduleType m1 : 8|3@1+ (1,0) [0|7] "" Vector__XXX
 SG_ BMS_thermalPackType m1 : 11|4@1+ (1,0) [0|15] "" Vector__XXX
 SG_ BMS_packMass m1 : 16|8@1+ (1,300) [342|540] "kg" Vector__XXX
 SG_ BMS_platformMaxBusVoltage m1 : 24|10@1+ (1,300) [300|1300] "V" Vector__XXX
 SG_ BMS_standbySupplyContinuousPower m1 : 36|2@1+ (1,0) [0|3] "" Vector__XXX
 SG_ BMS_beginningOfLifePackEnergy m1 : 40|10@1+ (0.1,0) [0|102.2] "KWh" Vector__XXX

BO_TX_BU_ 800 : BMS;
BO_TX_BU_ 818 : BMS;
BO_TX_BU_ 1025 : BMS;
BO_TX_BU_ 1138 : BMS;
BO_TX_BU_ 562 : BMS;
BO_TX_BU_ 722 : BMS;
BO_TX_BU_ 690 : BMS;
BO_TX_BU_ 306 : BMS;
BO_TX_BU_ 768 : BMS;
BO_TX_BU_ 978 : BMS;
BO_TX_BU_ 1010 : BMS;
BO_TX_BU_ 884 : BMS;
BO_TX_BU_ 946 : BMS;
BO_TX_BU_ 914 : BMS;
CM_ BO_ 800 "High-voltage battery management system message: alert matrix";
CM_ SG_ 800 BMS_matrixIndex "High-voltage battery management system: matrix index";
CM_ SG_ 800 BMS_a001_Pack_Config_Mismatch "High-voltage battery management system: a001 pack config mismatch";
CM_ SG_ 800 BMS_a002_Pack_Performance_Config "High-voltage battery management system: a002 pack performance config mismatch";
CM_ SG_ 800 BMS_a003_SW_Pack_Birth_Date_Miss "High-voltage battery management system: a003 SW pack birth date missing";
CM_ SG_ 800 BMS_a004_Cal_Vs_Serial_Birth_Dat "High-voltage battery management system: a004 cal vs serial birth date mismatch";
CM_ SG_ 800 BMS_a016_Pack_Module_Id_Mismatch "High-voltage battery management system: a016 pack module id mismatch";
CM_ SG_ 800 BMS_a017_SW_Brick_OV "High-voltage battery management system: a017 SW brick OV";
CM_ SG_ 800 BMS_a018_SW_Brick_UV "High-voltage battery management system: a018 SW brick UV";
CM_ SG_ 800 BMS_a019_SW_Module_OT "High-voltage battery management system: a019 SW module OT";
CM_ SG_ 800 BMS_a020_SW_Brick_Instability "High-voltage battery management system: a020 SW brick instability";
CM_ SG_ 800 BMS_a021_SW_Dr_Limits_Regulation "High-voltage battery management system: a021 SW dr limits regulation";
CM_ SG_ 800 BMS_a022_SW_Over_Current "High-voltage battery management system: a022 SW over current";
CM_ SG_ 800 BMS_a023_SW_Stack_OV "High-voltage battery management system: a023 SW stack OV";
CM_ SG_ 800 BMS_a024_SW_Islanded_Brick "High-voltage battery management system: a024 SW islanded brick";
CM_ SG_ 800 BMS_a025_SW_PwrBalance_Anomaly "High-voltage battery management system: a025 SW pwr balance anomaly";
CM_ SG_ 800 BMS_a026_SW_HFCurrent_Anomaly "High-voltage battery management system: a026 SW HF current anomaly";
CM_ SG_ 800 BMS_a027_SW_Repeated_Isolation_F "High-voltage battery management system: a027 SW repeated isolation failure in drive";
CM_ SG_ 800 BMS_a028_ShuntAsicCurrentOffsetD "High-voltage battery management system: a028 shunt asic current offset deviation";
CM_ SG_ 800 BMS_a029_dSoc_Limiting "High-voltage battery management system: a029 d soc limiting";
CM_ SG_ 800 BMS_a030_Impedance_Deviation "High-voltage battery management system: a030 impedance deviation";
CM_ SG_ 800 BMS_a031_AlertsSetDuringSleep "High-voltage battery management system: a031 alerts set during sleep";
CM_ SG_ 800 BMS_a032_VoltageLoss "High-voltage battery management system: a032 voltage loss";
CM_ SG_ 800 BMS_a033_VoltageDeviation "High-voltage battery management system: a033 voltage deviation";
CM_ SG_ 800 BMS_a034_SW_Passive_Isolation "High-voltage battery management system: a034 SW passive isolation";
CM_ SG_ 800 BMS_a035_SW_Isolation "High-voltage battery management system: a035 SW isolation";
CM_ SG_ 800 BMS_a036_SW_HvpHvilFault "High-voltage battery management system: a036 SW hvp hvil fault";
CM_ SG_ 800 BMS_a037_SW_Flood_Port_Open "High-voltage battery management system: a037 SW flood port open";
CM_ SG_ 800 BMS_a039_SW_DC_Link_Over_Voltage "High-voltage battery management system: a039 SW DC link over voltage";
CM_ SG_ 800 BMS_a040_SW_Watch_Dog_HW_Trigger "High-voltage battery management system: a040 SW watch dog HW triggered";
CM_ SG_ 800 BMS_a041_SW_Destructive_Reset_So "High-voltage battery management system: a041 SW destructive reset source";
CM_ SG_ 800 BMS_a042_SW_MPU_Error "High-voltage battery management system: a042 SW MPU error";
CM_ SG_ 800 BMS_a043_SW_Watch_Dog_Reset "High-voltage battery management system: a043 SW watch dog reset";
CM_ SG_ 800 BMS_a044_SW_Assertion "High-voltage battery management system: a044 SW assertion";
CM_ SG_ 800 BMS_a045_SW_Exception "High-voltage battery management system: a045 SW exception";
CM_ SG_ 800 BMS_a046_SW_Task_Stack_Usage "High-voltage battery management system: a046 SW task stack usage";
CM_ SG_ 800 BMS_a047_SW_Task_Stack_Overflow "High-voltage battery management system: a047 SW task stack overflow";
CM_ SG_ 800 BMS_a048_SW_Watch_Dog_Warning "High-voltage battery management system: a048 SW watch dog warning";
CM_ SG_ 800 BMS_a049_SW_Thermal_Event "High-voltage battery management system: a049 SW thermal event";
CM_ SG_ 800 BMS_a050_SW_Brick_Voltage_MIA "High-voltage battery management system: a050 SW brick voltage MIA";
CM_ SG_ 800 BMS_a051_SW_HVC_Vref_Bad "High-voltage battery management system: a051 SW HVC vref bad";
CM_ SG_ 800 BMS_a052_SW_PCS_MIA "High-voltage battery management system: a052 SW PCS MIA";
CM_ SG_ 800 BMS_a054_SW_Ver_Supply_Fault "High-voltage battery management system: a054 SW ver supply fault";
CM_ SG_ 800 BMS_a055_SW_HvChain_Model_Fault "High-voltage battery management system: a055 SW hv chain model fault";
CM_ SG_ 800 BMS_a056_SW_Standby_Supply_Fault "High-voltage battery management system: a056 SW standby supply fault";
CM_ SG_ 800 BMS_a057_SW_Bandolier_Model_Warn "High-voltage battery management system: a057 SW bandolier model warning";
CM_ SG_ 800 BMS_a058_SW_Bandolier_Model_Rese "High-voltage battery management system: a058 SW bandolier model reset";
CM_ SG_ 800 BMS_a059_SW_Pack_Voltage_Sensing "High-voltage battery management system: a059 SW pack voltage sensing";
CM_ SG_ 800 BMS_a060_SW_Leakage_Test_Failure "High-voltage battery management system: a060 SW leakage test failure";
CM_ SG_ 800 BMS_a061_SW_BrickV_Change "High-voltage battery management system: a061 SW brick v change";
CM_ SG_ 800 BMS_a062_SW_BrickV_Imbalance "High-voltage battery management system: a062 SW brick v imbalance";
CM_ SG_ 800 BMS_a063_SW_ChargePort_Fault "High-voltage battery management system: a063 SW charge port fault";
CM_ SG_ 800 BMS_a064_SW_SOC_Imbalance "High-voltage battery management system: a064 SW SOC imbalance";
CM_ SG_ 800 BMS_a065_SW_CAC_Imbalance "High-voltage battery management system: a065 SW CAC imbalance";
CM_ SG_ 800 BMS_a066_SOC_Imbalance_Warning "High-voltage battery management system: a066 SOC imbalance warning";
CM_ SG_ 800 BMS_a067_CAC_Imbalance_Limiting "High-voltage battery management system: a067 CAC imbalance limiting";
CM_ SG_ 800 BMS_a068_CAC_Imbalance_Limp "High-voltage battery management system: a068 CAC imbalance limp";
CM_ SG_ 800 BMS_a069_SW_Low_Power "High-voltage battery management system: a069 SW low power";
CM_ SG_ 800 BMS_a070_BrickV_Imbalance_Limiti "High-voltage battery management system: a070 brick v imbalance limiting";
CM_ SG_ 800 BMS_a071_SW_SM_TransCon_Not_Met "High-voltage battery management system: a071 SW SM trans con not met";
CM_ SG_ 800 BMS_a072_Module_Brick_Split "High-voltage battery management system: a072 module brick split";
CM_ SG_ 800 BMS_a073_Unexpected_Loss_Of_Lv "High-voltage battery management system: a073 unexpected loss of lv";
CM_ SG_ 800 BMS_a074_Max_Charge_Level_Reduce "High-voltage battery management system: a074 max charge level reduced";
CM_ SG_ 800 BMS_a075_SW_Chg_Disable_Failure "High-voltage battery management system: a075 SW chg disable failure";
CM_ SG_ 800 BMS_a076_SW_Dch_While_Charging "High-voltage battery management system: a076 SW dch while charging";
CM_ SG_ 800 BMS_a077_SW_Charger_Regulation "High-voltage battery management system: a077 SW charger regulation";
CM_ SG_ 800 BMS_a078_Rapid_Dch_While_Chargin "High-voltage battery management system: a078 rapid dch while charging";
CM_ SG_ 800 BMS_a079_Max_Charge_Level_Exceed "High-voltage battery management system: a079 max charge level exceeded";
CM_ SG_ 800 BMS_a080_SW_Pack_Ctr_Impedance "High-voltage battery management system: a080 SW pack ctr impedance";
CM_ SG_ 800 BMS_a081_SW_Ctr_Close_Blocked "High-voltage battery management system: a081 SW ctr close blocked";
CM_ SG_ 800 BMS_a082_SW_Ctr_Force_Open "High-voltage battery management system: a082 SW ctr force open";
CM_ SG_ 800 BMS_a083_SW_Ctr_Close_Failure "High-voltage battery management system: a083 SW ctr close failure";
CM_ SG_ 800 BMS_a084_SW_Sleep_Wake_Aborted "High-voltage battery management system: a084 SW sleep wake aborted";
CM_ SG_ 800 BMS_a085_SW_Pack_Contactor_Misma "High-voltage battery management system: a085 SW pack contactor mismatch";
CM_ SG_ 800 BMS_a086_SW_FC_Contactor_Mismatc "High-voltage battery management system: a086 SW FC contactor mismatch";
CM_ SG_ 800 BMS_a087_SW_Feim_Test_Blocked "High-voltage battery management system: a087 SW feim test blocked";
CM_ SG_ 800 BMS_a088_SW_VcFront_MIA_InDrive "High-voltage battery management system: a088 SW vc front MIA in drive";
CM_ SG_ 800 BMS_a089_SW_VcFront_MIA "High-voltage battery management system: a089 SW vc front MIA";
CM_ SG_ 800 BMS_a090_SW_Gateway_MIA "High-voltage battery management system: a090 SW gateway MIA";
CM_ SG_ 800 BMS_a091_SW_ChargePort_MIA "High-voltage battery management system: a091 SW charge port MIA";
CM_ SG_ 800 BMS_a092_SW_ChargePort_Mia_On_Hv "High-voltage battery management system: a092 SW charge port mia on hvs";
CM_ SG_ 800 BMS_a094_SW_Drive_Inverter_MIA "High-voltage battery management system: a094 SW drive inverter MIA";
CM_ SG_ 800 BMS_a095_SW_UI_MIA "High-voltage battery management system: a095 SW UI MIA";
CM_ SG_ 800 BMS_a097_SW_BMB_Over_CAN_Communi "High-voltage battery management system: a097 SW BMB over CAN communication";
CM_ SG_ 800 BMS_a098_SW_BMB_Data_Integrity_L "High-voltage battery management system: a098 SW BMB data integrity loss";
CM_ SG_ 800 BMS_a099_SW_BMB_Communication "High-voltage battery management system: a099 SW BMB communication";
CM_ SG_ 800 BMS_a100_ThermalEventSuspected "High-voltage battery management system: a100 thermal event suspected";
CM_ SG_ 800 BMS_a105_SW_One_Module_Tsense "High-voltage battery management system: a105 SW one module tsense";
CM_ SG_ 800 BMS_a106_SW_All_Module_Tsense "High-voltage battery management system: a106 SW all module tsense";
CM_ SG_ 800 BMS_a107_SW_Stack_Voltage_MIA "High-voltage battery management system: a107 SW stack voltage MIA";
CM_ SG_ 800 BMS_a108_SW_BMB_Device_OT "High-voltage battery management system: a108 SW BMB device OT";
CM_ SG_ 800 BMS_a109_HW_BMB_Mute_Status_Mism "High-voltage battery management system: a109 HW BMB mute status mismatch";
CM_ SG_ 800 BMS_a110_LifeModel_AvgOffset_Cha "High-voltage battery management system: a110 life model avg offset change";
CM_ SG_ 800 BMS_a111_LifeModel_Spread_Change "High-voltage battery management system: a111 life model spread change";
CM_ SG_ 800 BMS_a112_LifeModel_Discontinuity "High-voltage battery management system: a112 life model discontinuity";
CM_ SG_ 800 BMS_a115_Energy_Rubberbanding_Re "High-voltage battery management system: a115 energy rubberbanding reset";
CM_ SG_ 800 BMS_a117_SW_Delta_SOC_Weak_Short "High-voltage battery management system: a117 SW delta SOC weak short";
CM_ SG_ 800 BMS_a118_SW_Delta_SOC_Weak_Short "High-voltage battery management system: a118 SW delta SOC weak short warning";
CM_ SG_ 800 BMS_a119_Fast_Open_Vsh_Detected "High-voltage battery management system: a119 fast open vsh detected";
CM_ SG_ 800 BMS_a120_SW_Delta_SOC_User_Warni "High-voltage battery management system: a120 SW delta SOC user warning";
CM_ SG_ 800 BMS_a121_SW_NVRAM_Config_Error "High-voltage battery management system: a121 SW NVRAM config error";
CM_ SG_ 800 BMS_a122_SW_BMS_Therm_Irrational "High-voltage battery management system: a122 SW BMS therm irrational";
CM_ SG_ 800 BMS_a123_SW_Internal_Isolation "High-voltage battery management system: a123 SW internal isolation";
CM_ SG_ 800 BMS_a124_Battery_Coolant_Flood "High-voltage battery management system: a124 battery coolant flood";
CM_ SG_ 800 BMS_a126_SW_Thermistor_Failure "High-voltage battery management system: a126 SW thermistor failure";
CM_ SG_ 800 BMS_a127_SW_shunt_SNA "High-voltage battery management system: a127 SW shunt SNA";
CM_ SG_ 800 BMS_a128_SW_shunt_MIA "High-voltage battery management system: a128 SW shunt MIA";
CM_ SG_ 800 BMS_a129_SW_VSH_Failure "High-voltage battery management system: a129 SW VSH failure";
CM_ SG_ 800 BMS_a130_IO_CAN_Error "High-voltage battery management system: a130 IO CAN error";
CM_ SG_ 800 BMS_a131_Bleed_FET_Failure "High-voltage battery management system: a131 bleed FET failure";
CM_ SG_ 800 BMS_a132_HW_BMB_OTP_Uncorrctbl "High-voltage battery management system: a132 HW BMB OTP uncorrctbl";
CM_ SG_ 800 BMS_a133_IO_CAN_Bus_Off "High-voltage battery management system: a133 IO CAN bus off";
CM_ SG_ 800 BMS_a134_SW_Delayed_Ctr_Off "High-voltage battery management system: a134 SW delayed ctr off";
CM_ SG_ 800 BMS_a135_HW_BMB_Diagnostics_Fail "High-voltage battery management system: a135 HW BMB diagnostics failure";
CM_ SG_ 800 BMS_a136_SW_Module_OT_Warning "High-voltage battery management system: a136 SW module OT warning";
CM_ SG_ 800 BMS_a137_SW_Brick_UV_Warning "High-voltage battery management system: a137 SW brick UV warning";
CM_ SG_ 800 BMS_a138_SW_Brick_OV_Warning "High-voltage battery management system: a138 SW brick OV warning";
CM_ SG_ 800 BMS_a139_SW_DC_Link_V_Irrational "High-voltage battery management system: a139 SW DC link v irrational";
CM_ SG_ 800 BMS_a140_HW_BMB_Status_Fault "High-voltage battery management system: a140 HW BMB status fault";
CM_ SG_ 800 BMS_a141_SW_BMB_Status_Warning "High-voltage battery management system: a141 SW BMB status warning";
CM_ SG_ 800 BMS_a142_SW_Isolation_Degradatio "High-voltage battery management system: a142 SW isolation degradation";
CM_ SG_ 800 BMS_a143_SW_CAC_Change "High-voltage battery management system: a143 SW CAC change";
CM_ SG_ 800 BMS_a144_Hvp_Config_Mismatch "High-voltage battery management system: a144 hvp config mismatch";
CM_ SG_ 800 BMS_a145_SW_SOC_Change "High-voltage battery management system: a145 SW SOC change";
CM_ SG_ 800 BMS_a146_SW_Brick_Overdischarged "High-voltage battery management system: a146 SW brick overdischarged";
CM_ SG_ 800 BMS_a147_SW_SOC_High_Ah_Error "High-voltage battery management system: a147 SW SOC high ah error";
CM_ SG_ 800 BMS_a148_SW_Unsupported_BMB_ASIC "High-voltage battery management system: a148 SW unsupported BMB ASIC type";
CM_ SG_ 800 BMS_a149_SW_Missing_Config_Block "High-voltage battery management system: a149 SW missing config block";
CM_ SG_ 800 BMS_a150_SW_Missing_Part_Number "High-voltage battery management system: a150 SW missing part number";
CM_ SG_ 800 BMS_a151_SW_external_isolation "High-voltage battery management system: a151 SW external isolation";
CM_ SG_ 800 BMS_a152_Isolation_In_Dc_Charge "High-voltage battery management system: a152 isolation in dc charge";
CM_ SG_ 800 BMS_a153_GridFormFaulted "High-voltage battery management system: a153 grid form faulted";
CM_ SG_ 800 BMS_a154_SW_Brick_OV_Warning_Sto "High-voltage battery management system: a154 SW brick OV warning stop charge";
CM_ SG_ 800 BMS_a155_SW_Weak_short_impedence "High-voltage battery management system: a155 SW weak short impedence";
CM_ SG_ 800 BMS_a156_SW_BMB_Vref_bad "High-voltage battery management system: a156 SW BMB vref bad";
CM_ SG_ 800 BMS_a157_SW_Hist_Update_Missed "High-voltage battery management system: a157 SW hist update missed";
CM_ SG_ 800 BMS_a158_SW_HVP_HVI_Comms "High-voltage battery management system: a158 SW HVP HVI comms";
CM_ SG_ 800 BMS_a159_SW_HVP_ECU_Error "High-voltage battery management system: a159 SW HVP ECU error";
CM_ SG_ 800 BMS_a160_SW_FC_Ctr_Clean_Failed "High-voltage battery management system: a160 SW FC ctr clean failed";
CM_ SG_ 800 BMS_a161_SW_BMB_Vref_warning "High-voltage battery management system: a161 SW BMB vref warning";
CM_ SG_ 800 BMS_a162_SW_No_Power_For_Support "High-voltage battery management system: a162 SW no power for support";
CM_ SG_ 800 BMS_a163_GridFormAborted "High-voltage battery management system: a163 grid form aborted";
CM_ SG_ 800 BMS_a164_SW_Uncontrolled_Regen "High-voltage battery management system: a164 SW uncontrolled regen";
CM_ SG_ 800 BMS_a165_SW_Pack_Partial_Weld "High-voltage battery management system: a165 SW pack partial weld";
CM_ SG_ 800 BMS_a166_SW_Pack_Full_Weld "High-voltage battery management system: a166 SW pack full weld";
CM_ SG_ 800 BMS_a167_SW_FC_Partial_Weld "High-voltage battery management system: a167 SW FC partial weld";
CM_ SG_ 800 BMS_a168_SW_FC_Full_Weld "High-voltage battery management system: a168 SW FC full weld";
CM_ SG_ 800 BMS_a169_SW_FC_Pack_Weld "High-voltage battery management system: a169 SW FC pack weld";
CM_ SG_ 800 BMS_a170_SW_Limp_Mode "High-voltage battery management system: a170 SW limp mode";
CM_ SG_ 800 BMS_a171_SW_Stack_Voltage_Sense "High-voltage battery management system: a171 SW stack voltage sense";
CM_ SG_ 800 BMS_a172_SW_Isolation_Failure_In "High-voltage battery management system: a172 SW isolation failure in drive warning";
CM_ SG_ 800 BMS_a173_FullPackEnergyDegraded "High-voltage battery management system: a173 full pack energy degraded";
CM_ SG_ 800 BMS_a174_SW_Charge_Failure "High-voltage battery management system: a174 SW charge failure";
CM_ SG_ 800 BMS_a175_Charge_Failure_External "High-voltage battery management system: a175 charge failure external";
CM_ SG_ 800 BMS_a176_SW_GracefulPowerOff "High-voltage battery management system: a176 SW graceful power off";
CM_ SG_ 800 BMS_a177_SW_Energy_Buffer_Size "High-voltage battery management system: a177 SW energy buffer size";
CM_ SG_ 800 BMS_a178_SW_Uncontrolled_Regen_P "High-voltage battery management system: a178 SW uncontrolled regen pwr b";
CM_ SG_ 800 BMS_a179_HvpGpoRequestActive "High-voltage battery management system: a179 hvp gpo request active";
CM_ SG_ 800 BMS_a180_SW_ECU_reset_blocked "High-voltage battery management system: a180 SW ECU reset blocked";
CM_ SG_ 800 BMS_a181_SW_Shunt_Over_Temperatu "High-voltage battery management system: a181 SW shunt over temperature";
CM_ SG_ 800 BMS_a182_LifeModel_NoCurrentLoss "High-voltage battery management system: a182 life model no current loss change";
CM_ SG_ 800 BMS_a183_LifeModel_StoDcrGrowth_ "High-voltage battery management system: a183 life model sto dcr growth change";
CM_ SG_ 800 BMS_a184_LifeModel_CyclingLoss_C "High-voltage battery management system: a184 life model cycling loss change";
CM_ SG_ 800 BMS_a185_LifeModel_CyclingDcrGro "High-voltage battery management system: a185 life model cycling dcr growth change";
CM_ SG_ 800 BMS_a186_RippleHeatingChargeFaul "High-voltage battery management system: a186 ripple heating charge fault";
CM_ SG_ 800 BMS_a187_RippleHeatingEmergencyS "High-voltage battery management system: a187 ripple heating emergency shutdown";
CM_ SG_ 800 BMS_a188_PowershareChargeCurrent "High-voltage battery management system: a188 powershare charge current violation";
CM_ SG_ 800 BMS_a189_PowershareDischargeCurr "High-voltage battery management system: a189 powershare discharge current violation";
CM_ SG_ 800 BMS_a190_PowershareMaxVoltageVio "High-voltage battery management system: a190 powershare max voltage violation";
CM_ SG_ 800 BMS_a191_PowershareMinVoltageVio "High-voltage battery management system: a191 powershare min voltage violation";
CM_ SG_ 800 BMS_a192_PowershareExternalCharg "High-voltage battery management system: a192 powershare external charge regulation";
CM_ SG_ 800 BMS_a193_PowershareMaxBrickVolta "High-voltage battery management system: a193 powershare max brick voltage violation";
CM_ SG_ 800 BMS_a194_PowershareLimitViolatio "High-voltage battery management system: a194 powershare limit violation";
CM_ SG_ 800 BMS_a195_SW_DeltaTempOverThresho "High-voltage battery management system: a195 SW delta temp over threshold";
CM_ SG_ 800 BMS_a196_SW_PackVoltageUnderThre "High-voltage battery management system: a196 SW pack voltage under threshold";
CM_ SG_ 800 BMS_a197_SW_High_SOC_OV "High-voltage battery management system: a197 SW high SOC OV";
CM_ SG_ 800 BMS_a198_SW_SOC_Abrupt_Change "High-voltage battery management system: a198 SW SOC abrupt change";
CM_ SG_ 800 BMS_a199_GridFollowAborted "High-voltage battery management system: a199 grid follow aborted";
CM_ SG_ 800 BMS_a200_GridFollowFaulted "High-voltage battery management system: a200 grid follow faulted";
CM_ SG_ 800 BMS_a201_SW_Brick_OV_During_Char "High-voltage battery management system: a201 SW brick OV during charge";
CM_ SG_ 800 BMS_a202_AcChargeFaulted "High-voltage battery management system: a202 ac charge faulted";
CM_ SG_ 800 BMS_a204_AcCpEmergencyShutdownRe "High-voltage battery management system: a204 ac cp emergency shutdown requested";
CM_ SG_ 800 BMS_a214_AcChargeAborted "High-voltage battery management system: a214 ac charge aborted";
CM_ SG_ 800 BMS_a221_PcsEmergencyShutdownReq "High-voltage battery management system: a221 pcs emergency shutdown requested";
CM_ SG_ 800 BMS_a227_ExcessChargeCurrentInCh "High-voltage battery management system: a227 excess charge current in charge";
CM_ SG_ 800 BMS_a254_LdcsCacImbalance "High-voltage battery management system: a254 ldcs cac imbalance";
CM_ SG_ 800 BMS_a255_EstimatedRangeReduced "High-voltage battery management system: a255 estimated range reduced";
CM_ SG_ 800 BMS_a256_SW_Low_Power_Warning "High-voltage battery management system: a256 SW low power warning";
CM_ SG_ 800 BMS_d257_internalIsolationFault "High-voltage battery management system: d257 internal isolation fault";
CM_ SG_ 800 BMS_d258_externalIsolationFault "High-voltage battery management system: d258 external isolation fault";
CM_ SG_ 800 BMS_d259_highVoltageInterlockFai "High-voltage battery management system: d259 high voltage interlock failure";
CM_ SG_ 800 BMS_d260_chargePortInterlockFail "High-voltage battery management system: d260 charge port interlock failure";
CM_ SG_ 800 BMS_d261_batteryPackCellVoltageH "High-voltage battery management system: d261 battery pack cell voltage high";
CM_ SG_ 800 BMS_d262_batteryPackLowStateOfCh "High-voltage battery management system: d262 battery pack low state of charge";
CM_ SG_ 800 BMS_d263_batterySystemCurrentHig "High-voltage battery management system: d263 battery system current high";
CM_ SG_ 800 BMS_d264_invalidFirmwareConfig "High-voltage battery management system: d264 invalid firmware config";
CM_ SG_ 800 BMS_d265_replaceBatteryPack "High-voltage battery management system: d265 replace battery pack";
CM_ SG_ 800 BMS_d266_energyReserveVoltageLow "High-voltage battery management system: d266 energy reserve voltage low";
CM_ SG_ 800 BMS_d267_batteryPackCellVoltageS "High-voltage battery management system: d267 battery pack cell voltage sense harness failure";
CM_ SG_ 800 BMS_d268_hvpInvalidFirmwareConfi "High-voltage battery management system: d268 hvp invalid firmware config";
CM_ SG_ 800 BMS_d269_highVoltageFuseABlown "High-voltage battery management system: d269 high voltage fuse a blown";
CM_ SG_ 800 BMS_d270_hvpCommsLost "High-voltage battery management system: d270 hvp comms lost";
CM_ SG_ 800 BMS_d271_batteryPackSensorFailur "High-voltage battery management system: d271 battery pack sensor failure";
CM_ SG_ 800 BMS_d272_batteryPackSensorCommsL "High-voltage battery management system: d272 battery pack sensor comms lost";
CM_ SG_ 800 BMS_d273_vcFrontCommsLost "High-voltage battery management system: d273 vc front comms lost";
CM_ SG_ 800 BMS_d274_packCurrentSensorACircu "High-voltage battery management system: d274 pack current sensor a circuit failure";
CM_ SG_ 800 BMS_d275_packPosContactorACircui "High-voltage battery management system: d275 pack pos contactor a circuit failure";
CM_ SG_ 800 BMS_d276_packPosContactorAStuckC "High-voltage battery management system: d276 pack pos contactor a stuck closed";
CM_ SG_ 800 BMS_d277_packNegContactorACircui "High-voltage battery management system: d277 pack neg contactor a circuit failure";
CM_ SG_ 800 BMS_d278_packNegContactorAStuckC "High-voltage battery management system: d278 pack neg contactor a stuck closed";
CM_ SG_ 800 BMS_d279_fastChargePosContactorA "High-voltage battery management system: d279 fast charge pos contactor a circuit failure";
CM_ SG_ 800 BMS_d280_fastChargePosContactorA "High-voltage battery management system: d280 fast charge pos contactor a stuck closed";
CM_ SG_ 800 BMS_d281_fastChargePosContactorA "High-voltage battery management system: d281 fast charge pos contactor a stuck open";
CM_ SG_ 800 BMS_d282_fastChargeNegContactorA "High-voltage battery management system: d282 fast charge neg contactor a circuit failure";
CM_ SG_ 800 BMS_d283_fastChargeNegContactorA "High-voltage battery management system: d283 fast charge neg contactor a stuck closed";
CM_ SG_ 800 BMS_d284_fastChargeNegContactorA "High-voltage battery management system: d284 fast charge neg contactor a stuck open";
CM_ SG_ 800 BMS_d285_packVoltageSensorACircu "High-voltage battery management system: d285 pack voltage sensor a circuit failure";
CM_ SG_ 800 BMS_d286_dcLinkVoltageHigh "High-voltage battery management system: d286 dc link voltage high";
CM_ SG_ 800 BMS_d287_systemIsolationWarning "High-voltage battery management system: d287 system isolation warning";
CM_ SG_ 800 BMS_d288_batteryPackCellVoltageL "High-voltage battery management system: d288 battery pack cell voltage low";
CM_ SG_ 800 BMS_d289_batteryPackAOverTempera "High-voltage battery management system: d289 battery pack a over temperature";
CM_ SG_ 800 BMS_d290_batteryPackTempSensorAC "High-voltage battery management system: d290 battery pack temp sensor a circuit failure";
CM_ SG_ 800 BMS_a291_SOC_Imbalance_By_Delta_ "High-voltage battery management system: a291 SOC imbalance by delta voltage over delta SOC";
CM_ SG_ 800 BMS_a299_PowershareFailure "High-voltage battery management system: a299 powershare failure";
CM_ BO_ 818 "High-voltage battery management system message: bmb min max";
CM_ SG_ 818 BMS_bmbMinMaxMultiplexer "High-voltage battery management system: bmb min max multiplexer";
CM_ SG_ 818 BMS_thermistorNumTMin "BMB module number with minimum temperature.";
CM_ SG_ 818 BMS_thermistorNumTMax "BMB module number with maximum temperature.";
CM_ SG_ 818 BMS_thermistorTMax "Max temperature of all valid filtered thermistors";
CM_ SG_ 818 BMS_thermistorTMin "Min temperature of all valid filtered thermistors";
CM_ SG_ 818 BMS_thermistorTAvg "Average temperature of all valid filtered thermistors";
CM_ SG_ 818 BMS_brickVoltageMax "Brick voltage maximum.";
CM_ SG_ 818 BMS_brickVoltageMin "Brick voltage minimum.";
CM_ SG_ 818 BMS_brickNumVoltageMax "Brick number with maximum voltage (1 indexed)";
CM_ SG_ 818 BMS_brickNumVoltageMin "Brick number with minimum voltage (1 indexed)";
CM_ BO_ 1025 "High-voltage battery management system message: brick measurements";
CM_ SG_ 1025 BMS_brickVoltageMultiplexer "High-voltage battery management system: brick voltage multiplexer";
CM_ SG_ 1025 BMS_brickVoltageCounter "High-voltage battery management system: brick voltage counter";
CM_ SG_ 1025 BMS_brickVoltageStatus1 "High-voltage battery management system: brick voltage status1";
CM_ SG_ 1025 BMS_brickVoltageStatus2 "High-voltage battery management system: brick voltage status2";
CM_ SG_ 1025 BMS_brickVoltageStatus3 "High-voltage battery management system: brick voltage status3";
CM_ SG_ 1025 BMS_brickVoltage1 "High-voltage battery management system: brick voltage1";
CM_ SG_ 1025 BMS_brickVoltage2 "High-voltage battery management system: brick voltage2";
CM_ SG_ 1025 BMS_brickVoltage3 "High-voltage battery management system: brick voltage3";
CM_ SG_ 1025 BMS_brickVoltageStatus4 "High-voltage battery management system: brick voltage status4";
CM_ SG_ 1025 BMS_brickVoltageStatus5 "High-voltage battery management system: brick voltage status5";
CM_ SG_ 1025 BMS_brickVoltageStatus6 "High-voltage battery management system: brick voltage status6";
CM_ SG_ 1025 BMS_brickVoltage4 "High-voltage battery management system: brick voltage4";
CM_ SG_ 1025 BMS_brickVoltage5 "High-voltage battery management system: brick voltage5";
CM_ SG_ 1025 BMS_brickVoltage6 "High-voltage battery management system: brick voltage6";
CM_ SG_ 1025 BMS_brickVoltageStatus7 "High-voltage battery management system: brick voltage status7";
CM_ SG_ 1025 BMS_brickVoltageStatus8 "High-voltage battery management system: brick voltage status8";
CM_ SG_ 1025 BMS_brickVoltageStatus9 "High-voltage battery management system: brick voltage status9";
CM_ SG_ 1025 BMS_brickVoltage7 "High-voltage battery management system: brick voltage7";
CM_ SG_ 1025 BMS_brickVoltage8 "High-voltage battery management system: brick voltage8";
CM_ SG_ 1025 BMS_brickVoltage9 "High-voltage battery management system: brick voltage9";
CM_ SG_ 1025 BMS_brickVoltageStatus10 "High-voltage battery management system: brick voltage status10";
CM_ SG_ 1025 BMS_brickVoltageStatus11 "High-voltage battery management system: brick voltage status11";
CM_ SG_ 1025 BMS_brickVoltageStatus12 "High-voltage battery management system: brick voltage status12";
CM_ SG_ 1025 BMS_brickVoltage10 "High-voltage battery management system: brick voltage10";
CM_ SG_ 1025 BMS_brickVoltage11 "High-voltage battery management system: brick voltage11";
CM_ SG_ 1025 BMS_brickVoltage12 "High-voltage battery management system: brick voltage12";
CM_ SG_ 1025 BMS_brickVoltageStatus13 "High-voltage battery management system: brick voltage status13";
CM_ SG_ 1025 BMS_brickVoltageStatus14 "High-voltage battery management system: brick voltage status14";
CM_ SG_ 1025 BMS_brickVoltageStatus15 "High-voltage battery management system: brick voltage status15";
CM_ SG_ 1025 BMS_brickVoltage13 "High-voltage battery management system: brick voltage13";
CM_ SG_ 1025 BMS_brickVoltage14 "High-voltage battery management system: brick voltage14";
CM_ SG_ 1025 BMS_brickVoltage15 "High-voltage battery management system: brick voltage15";
CM_ SG_ 1025 BMS_brickVoltageStatus16 "High-voltage battery management system: brick voltage status16";
CM_ SG_ 1025 BMS_brickVoltageStatus17 "High-voltage battery management system: brick voltage status17";
CM_ SG_ 1025 BMS_brickVoltageStatus18 "High-voltage battery management system: brick voltage status18";
CM_ SG_ 1025 BMS_brickVoltage16 "High-voltage battery management system: brick voltage16";
CM_ SG_ 1025 BMS_brickVoltage17 "High-voltage battery management system: brick voltage17";
CM_ SG_ 1025 BMS_brickVoltage18 "High-voltage battery management system: brick voltage18";
CM_ SG_ 1025 BMS_brickVoltageStatus19 "High-voltage battery management system: brick voltage status19";
CM_ SG_ 1025 BMS_brickVoltageStatus20 "High-voltage battery management system: brick voltage status20";
CM_ SG_ 1025 BMS_brickVoltageStatus21 "High-voltage battery management system: brick voltage status21";
CM_ SG_ 1025 BMS_brickVoltage19 "High-voltage battery management system: brick voltage19";
CM_ SG_ 1025 BMS_brickVoltage20 "High-voltage battery management system: brick voltage20";
CM_ SG_ 1025 BMS_brickVoltage21 "High-voltage battery management system: brick voltage21";
CM_ SG_ 1025 BMS_brickVoltageStatus22 "High-voltage battery management system: brick voltage status22";
CM_ SG_ 1025 BMS_brickVoltageStatus23 "High-voltage battery management system: brick voltage status23";
CM_ SG_ 1025 BMS_brickVoltageStatus24 "High-voltage battery management system: brick voltage status24";
CM_ SG_ 1025 BMS_brickVoltage22 "High-voltage battery management system: brick voltage22";
CM_ SG_ 1025 BMS_brickVoltage23 "High-voltage battery management system: brick voltage23";
CM_ SG_ 1025 BMS_brickVoltage24 "High-voltage battery management system: brick voltage24";
CM_ SG_ 1025 BMS_brickVoltageStatus25 "High-voltage battery management system: brick voltage status25";
CM_ SG_ 1025 BMS_brickVoltageStatus26 "High-voltage battery management system: brick voltage status26";
CM_ SG_ 1025 BMS_brickVoltageStatus27 "High-voltage battery management system: brick voltage status27";
CM_ SG_ 1025 BMS_brickVoltage25 "High-voltage battery management system: brick voltage25";
CM_ SG_ 1025 BMS_brickVoltage26 "High-voltage battery management system: brick voltage26";
CM_ SG_ 1025 BMS_brickVoltage27 "High-voltage battery management system: brick voltage27";
CM_ SG_ 1025 BMS_brickVoltageStatus28 "High-voltage battery management system: brick voltage status28";
CM_ SG_ 1025 BMS_brickVoltageStatus29 "High-voltage battery management system: brick voltage status29";
CM_ SG_ 1025 BMS_brickVoltageStatus30 "High-voltage battery management system: brick voltage status30";
CM_ SG_ 1025 BMS_brickVoltage28 "High-voltage battery management system: brick voltage28";
CM_ SG_ 1025 BMS_brickVoltage29 "High-voltage battery management system: brick voltage29";
CM_ SG_ 1025 BMS_brickVoltage30 "High-voltage battery management system: brick voltage30";
CM_ SG_ 1025 BMS_brickVoltageStatus31 "High-voltage battery management system: brick voltage status31";
CM_ SG_ 1025 BMS_brickVoltageStatus32 "High-voltage battery management system: brick voltage status32";
CM_ SG_ 1025 BMS_brickVoltageStatus33 "High-voltage battery management system: brick voltage status33";
CM_ SG_ 1025 BMS_brickVoltage31 "High-voltage battery management system: brick voltage31";
CM_ SG_ 1025 BMS_brickVoltage32 "High-voltage battery management system: brick voltage32";
CM_ SG_ 1025 BMS_brickVoltage33 "High-voltage battery management system: brick voltage33";
CM_ SG_ 1025 BMS_brickVoltageStatus34 "High-voltage battery management system: brick voltage status34";
CM_ SG_ 1025 BMS_brickVoltageStatus35 "High-voltage battery management system: brick voltage status35";
CM_ SG_ 1025 BMS_brickVoltageStatus36 "High-voltage battery management system: brick voltage status36";
CM_ SG_ 1025 BMS_brickVoltage34 "High-voltage battery management system: brick voltage34";
CM_ SG_ 1025 BMS_brickVoltage35 "High-voltage battery management system: brick voltage35";
CM_ SG_ 1025 BMS_brickVoltage36 "High-voltage battery management system: brick voltage36";
CM_ SG_ 1025 BMS_brickVoltageStatus37 "High-voltage battery management system: brick voltage status37";
CM_ SG_ 1025 BMS_brickVoltageStatus38 "High-voltage battery management system: brick voltage status38";
CM_ SG_ 1025 BMS_brickVoltageStatus39 "High-voltage battery management system: brick voltage status39";
CM_ SG_ 1025 BMS_brickVoltage37 "High-voltage battery management system: brick voltage37";
CM_ SG_ 1025 BMS_brickVoltage38 "High-voltage battery management system: brick voltage38";
CM_ SG_ 1025 BMS_brickVoltage39 "High-voltage battery management system: brick voltage39";
CM_ SG_ 1025 BMS_brickVoltageStatus40 "High-voltage battery management system: brick voltage status40";
CM_ SG_ 1025 BMS_brickVoltageStatus41 "High-voltage battery management system: brick voltage status41";
CM_ SG_ 1025 BMS_brickVoltageStatus42 "High-voltage battery management system: brick voltage status42";
CM_ SG_ 1025 BMS_brickVoltage40 "High-voltage battery management system: brick voltage40";
CM_ SG_ 1025 BMS_brickVoltage41 "High-voltage battery management system: brick voltage41";
CM_ SG_ 1025 BMS_brickVoltage42 "High-voltage battery management system: brick voltage42";
CM_ SG_ 1025 BMS_brickVoltageStatus43 "High-voltage battery management system: brick voltage status43";
CM_ SG_ 1025 BMS_brickVoltageStatus44 "High-voltage battery management system: brick voltage status44";
CM_ SG_ 1025 BMS_brickVoltageStatus45 "High-voltage battery management system: brick voltage status45";
CM_ SG_ 1025 BMS_brickVoltage43 "High-voltage battery management system: brick voltage43";
CM_ SG_ 1025 BMS_brickVoltage44 "High-voltage battery management system: brick voltage44";
CM_ SG_ 1025 BMS_brickVoltage45 "High-voltage battery management system: brick voltage45";
CM_ SG_ 1025 BMS_brickVoltageStatus46 "High-voltage battery management system: brick voltage status46";
CM_ SG_ 1025 BMS_brickVoltageStatus47 "High-voltage battery management system: brick voltage status47";
CM_ SG_ 1025 BMS_brickVoltageStatus48 "High-voltage battery management system: brick voltage status48";
CM_ SG_ 1025 BMS_brickVoltage46 "High-voltage battery management system: brick voltage46";
CM_ SG_ 1025 BMS_brickVoltage47 "High-voltage battery management system: brick voltage47";
CM_ SG_ 1025 BMS_brickVoltage48 "High-voltage battery management system: brick voltage48";
CM_ SG_ 1025 BMS_brickVoltageStatus49 "High-voltage battery management system: brick voltage status49";
CM_ SG_ 1025 BMS_brickVoltageStatus50 "High-voltage battery management system: brick voltage status50";
CM_ SG_ 1025 BMS_brickVoltageStatus51 "High-voltage battery management system: brick voltage status51";
CM_ SG_ 1025 BMS_brickVoltage49 "High-voltage battery management system: brick voltage49";
CM_ SG_ 1025 BMS_brickVoltage50 "High-voltage battery management system: brick voltage50";
CM_ SG_ 1025 BMS_brickVoltage51 "High-voltage battery management system: brick voltage51";
CM_ SG_ 1025 BMS_brickVoltageStatus52 "High-voltage battery management system: brick voltage status52";
CM_ SG_ 1025 BMS_brickVoltageStatus53 "High-voltage battery management system: brick voltage status53";
CM_ SG_ 1025 BMS_brickVoltageStatus54 "High-voltage battery management system: brick voltage status54";
CM_ SG_ 1025 BMS_brickVoltage52 "High-voltage battery management system: brick voltage52";
CM_ SG_ 1025 BMS_brickVoltage53 "High-voltage battery management system: brick voltage53";
CM_ SG_ 1025 BMS_brickVoltage54 "High-voltage battery management system: brick voltage54";
CM_ SG_ 1025 BMS_brickVoltageStatus55 "High-voltage battery management system: brick voltage status55";
CM_ SG_ 1025 BMS_brickVoltageStatus56 "High-voltage battery management system: brick voltage status56";
CM_ SG_ 1025 BMS_brickVoltageStatus57 "High-voltage battery management system: brick voltage status57";
CM_ SG_ 1025 BMS_brickVoltage55 "High-voltage battery management system: brick voltage55";
CM_ SG_ 1025 BMS_brickVoltage56 "High-voltage battery management system: brick voltage56";
CM_ SG_ 1025 BMS_brickVoltage57 "High-voltage battery management system: brick voltage57";
CM_ SG_ 1025 BMS_brickVoltageStatus58 "High-voltage battery management system: brick voltage status58";
CM_ SG_ 1025 BMS_brickVoltageStatus59 "High-voltage battery management system: brick voltage status59";
CM_ SG_ 1025 BMS_brickVoltageStatus60 "High-voltage battery management system: brick voltage status60";
CM_ SG_ 1025 BMS_brickVoltage58 "High-voltage battery management system: brick voltage58";
CM_ SG_ 1025 BMS_brickVoltage59 "High-voltage battery management system: brick voltage59";
CM_ SG_ 1025 BMS_brickVoltage60 "High-voltage battery management system: brick voltage60";
CM_ SG_ 1025 BMS_brickVoltageStatus61 "High-voltage battery management system: brick voltage status61";
CM_ SG_ 1025 BMS_brickVoltageStatus62 "High-voltage battery management system: brick voltage status62";
CM_ SG_ 1025 BMS_brickVoltageStatus63 "High-voltage battery management system: brick voltage status63";
CM_ SG_ 1025 BMS_brickVoltage61 "High-voltage battery management system: brick voltage61";
CM_ SG_ 1025 BMS_brickVoltage62 "High-voltage battery management system: brick voltage62";
CM_ SG_ 1025 BMS_brickVoltage63 "High-voltage battery management system: brick voltage63";
CM_ SG_ 1025 BMS_brickVoltageStatus64 "High-voltage battery management system: brick voltage status64";
CM_ SG_ 1025 BMS_brickVoltageStatus65 "High-voltage battery management system: brick voltage status65";
CM_ SG_ 1025 BMS_brickVoltageStatus66 "High-voltage battery management system: brick voltage status66";
CM_ SG_ 1025 BMS_brickVoltage64 "High-voltage battery management system: brick voltage64";
CM_ SG_ 1025 BMS_brickVoltage65 "High-voltage battery management system: brick voltage65";
CM_ SG_ 1025 BMS_brickVoltage66 "High-voltage battery management system: brick voltage66";
CM_ SG_ 1025 BMS_brickVoltageStatus67 "High-voltage battery management system: brick voltage status67";
CM_ SG_ 1025 BMS_brickVoltageStatus68 "High-voltage battery management system: brick voltage status68";
CM_ SG_ 1025 BMS_brickVoltageStatus69 "High-voltage battery management system: brick voltage status69";
CM_ SG_ 1025 BMS_brickVoltage67 "High-voltage battery management system: brick voltage67";
CM_ SG_ 1025 BMS_brickVoltage68 "High-voltage battery management system: brick voltage68";
CM_ SG_ 1025 BMS_brickVoltage69 "High-voltage battery management system: brick voltage69";
CM_ SG_ 1025 BMS_brickVoltageStatus70 "High-voltage battery management system: brick voltage status70";
CM_ SG_ 1025 BMS_brickVoltageStatus71 "High-voltage battery management system: brick voltage status71";
CM_ SG_ 1025 BMS_brickVoltageStatus72 "High-voltage battery management system: brick voltage status72";
CM_ SG_ 1025 BMS_brickVoltage70 "High-voltage battery management system: brick voltage70";
CM_ SG_ 1025 BMS_brickVoltage71 "High-voltage battery management system: brick voltage71";
CM_ SG_ 1025 BMS_brickVoltage72 "High-voltage battery management system: brick voltage72";
CM_ SG_ 1025 BMS_brickVoltageStatus73 "High-voltage battery management system: brick voltage status73";
CM_ SG_ 1025 BMS_brickVoltageStatus74 "High-voltage battery management system: brick voltage status74";
CM_ SG_ 1025 BMS_brickVoltageStatus75 "High-voltage battery management system: brick voltage status75";
CM_ SG_ 1025 BMS_brickVoltage73 "High-voltage battery management system: brick voltage73";
CM_ SG_ 1025 BMS_brickVoltage74 "High-voltage battery management system: brick voltage74";
CM_ SG_ 1025 BMS_brickVoltage75 "High-voltage battery management system: brick voltage75";
CM_ SG_ 1025 BMS_brickVoltageStatus76 "High-voltage battery management system: brick voltage status76";
CM_ SG_ 1025 BMS_brickVoltageStatus77 "High-voltage battery management system: brick voltage status77";
CM_ SG_ 1025 BMS_brickVoltageStatus78 "High-voltage battery management system: brick voltage status78";
CM_ SG_ 1025 BMS_brickVoltage76 "High-voltage battery management system: brick voltage76";
CM_ SG_ 1025 BMS_brickVoltage77 "High-voltage battery management system: brick voltage77";
CM_ SG_ 1025 BMS_brickVoltage78 "High-voltage battery management system: brick voltage78";
CM_ SG_ 1025 BMS_brickVoltageStatus79 "High-voltage battery management system: brick voltage status79";
CM_ SG_ 1025 BMS_brickVoltageStatus80 "High-voltage battery management system: brick voltage status80";
CM_ SG_ 1025 BMS_brickVoltageStatus81 "High-voltage battery management system: brick voltage status81";
CM_ SG_ 1025 BMS_brickVoltage79 "High-voltage battery management system: brick voltage79";
CM_ SG_ 1025 BMS_brickVoltage80 "High-voltage battery management system: brick voltage80";
CM_ SG_ 1025 BMS_brickVoltage81 "High-voltage battery management system: brick voltage81";
CM_ SG_ 1025 BMS_brickVoltageStatus82 "High-voltage battery management system: brick voltage status82";
CM_ SG_ 1025 BMS_brickVoltageStatus83 "High-voltage battery management system: brick voltage status83";
CM_ SG_ 1025 BMS_brickVoltageStatus84 "High-voltage battery management system: brick voltage status84";
CM_ SG_ 1025 BMS_brickVoltage82 "High-voltage battery management system: brick voltage82";
CM_ SG_ 1025 BMS_brickVoltage83 "High-voltage battery management system: brick voltage83";
CM_ SG_ 1025 BMS_brickVoltage84 "High-voltage battery management system: brick voltage84";
CM_ SG_ 1025 BMS_brickVoltageStatus85 "High-voltage battery management system: brick voltage status85";
CM_ SG_ 1025 BMS_brickVoltageStatus86 "High-voltage battery management system: brick voltage status86";
CM_ SG_ 1025 BMS_brickVoltageStatus87 "High-voltage battery management system: brick voltage status87";
CM_ SG_ 1025 BMS_brickVoltage85 "High-voltage battery management system: brick voltage85";
CM_ SG_ 1025 BMS_brickVoltage86 "High-voltage battery management system: brick voltage86";
CM_ SG_ 1025 BMS_brickVoltage87 "High-voltage battery management system: brick voltage87";
CM_ SG_ 1025 BMS_brickVoltageStatus88 "High-voltage battery management system: brick voltage status88";
CM_ SG_ 1025 BMS_brickVoltageStatus89 "High-voltage battery management system: brick voltage status89";
CM_ SG_ 1025 BMS_brickVoltageStatus90 "High-voltage battery management system: brick voltage status90";
CM_ SG_ 1025 BMS_brickVoltage88 "High-voltage battery management system: brick voltage88";
CM_ SG_ 1025 BMS_brickVoltage89 "High-voltage battery management system: brick voltage89";
CM_ SG_ 1025 BMS_brickVoltage90 "High-voltage battery management system: brick voltage90";
CM_ SG_ 1025 BMS_brickVoltageStatus91 "High-voltage battery management system: brick voltage status91";
CM_ SG_ 1025 BMS_brickVoltageStatus92 "High-voltage battery management system: brick voltage status92";
CM_ SG_ 1025 BMS_brickVoltageStatus93 "High-voltage battery management system: brick voltage status93";
CM_ SG_ 1025 BMS_brickVoltage91 "High-voltage battery management system: brick voltage91";
CM_ SG_ 1025 BMS_brickVoltage92 "High-voltage battery management system: brick voltage92";
CM_ SG_ 1025 BMS_brickVoltage93 "High-voltage battery management system: brick voltage93";
CM_ SG_ 1025 BMS_brickVoltageStatus94 "High-voltage battery management system: brick voltage status94";
CM_ SG_ 1025 BMS_brickVoltageStatus95 "High-voltage battery management system: brick voltage status95";
CM_ SG_ 1025 BMS_brickVoltageStatus96 "High-voltage battery management system: brick voltage status96";
CM_ SG_ 1025 BMS_brickVoltage94 "High-voltage battery management system: brick voltage94";
CM_ SG_ 1025 BMS_brickVoltage95 "High-voltage battery management system: brick voltage95";
CM_ SG_ 1025 BMS_brickVoltage96 "High-voltage battery management system: brick voltage96";
CM_ SG_ 1025 BMS_brickVoltageStatus97 "High-voltage battery management system: brick voltage status97";
CM_ SG_ 1025 BMS_brickVoltageStatus98 "High-voltage battery management system: brick voltage status98";
CM_ SG_ 1025 BMS_brickVoltageStatus99 "High-voltage battery management system: brick voltage status99";
CM_ SG_ 1025 BMS_brickVoltage97 "High-voltage battery management system: brick voltage97";
CM_ SG_ 1025 BMS_brickVoltage98 "High-voltage battery management system: brick voltage98";
CM_ SG_ 1025 BMS_brickVoltage99 "High-voltage battery management system: brick voltage99";
CM_ SG_ 1025 BMS_brickVoltageStatus100 "High-voltage battery management system: brick voltage status100";
CM_ SG_ 1025 BMS_brickVoltageStatus101 "High-voltage battery management system: brick voltage status101";
CM_ SG_ 1025 BMS_brickVoltageStatus102 "High-voltage battery management system: brick voltage status102";
CM_ SG_ 1025 BMS_brickVoltage100 "High-voltage battery management system: brick voltage100";
CM_ SG_ 1025 BMS_brickVoltage101 "High-voltage battery management system: brick voltage101";
CM_ SG_ 1025 BMS_brickVoltage102 "High-voltage battery management system: brick voltage102";
CM_ SG_ 1025 BMS_brickVoltageStatus103 "High-voltage battery management system: brick voltage status103";
CM_ SG_ 1025 BMS_brickVoltageStatus104 "High-voltage battery management system: brick voltage status104";
CM_ SG_ 1025 BMS_brickVoltageStatus105 "High-voltage battery management system: brick voltage status105";
CM_ SG_ 1025 BMS_brickVoltage103 "High-voltage battery management system: brick voltage103";
CM_ SG_ 1025 BMS_brickVoltage104 "High-voltage battery management system: brick voltage104";
CM_ SG_ 1025 BMS_brickVoltage105 "High-voltage battery management system: brick voltage105";
CM_ SG_ 1025 BMS_brickVoltageStatus106 "High-voltage battery management system: brick voltage status106";
CM_ SG_ 1025 BMS_brickVoltageStatus107 "High-voltage battery management system: brick voltage status107";
CM_ SG_ 1025 BMS_brickVoltageStatus108 "High-voltage battery management system: brick voltage status108";
CM_ SG_ 1025 BMS_brickVoltage106 "High-voltage battery management system: brick voltage106";
CM_ SG_ 1025 BMS_brickVoltage107 "High-voltage battery management system: brick voltage107";
CM_ SG_ 1025 BMS_brickVoltage108 "High-voltage battery management system: brick voltage108";
CM_ BO_ 1138 "High-voltage battery management system message: charge info";
CM_ SG_ 1138 BMS_acChargePowerSample "High-voltage battery management system: ac charge power sample; raw 255 = signal not available (SNA)";
CM_ SG_ 1138 BMS_voltageRegCurrentTarget "DC current target based on voltage regulator";
CM_ SG_ 1138 BMS_vehicleChargeDcCurrentLimit "Charge current target after all aggregating all vehicle-side limits, exclude EVSE limits";
CM_ SG_ 1138 BMS_userChargeCurrentLimitMode "BMS' user-facing reason for charge being either limited or not limited";
CM_ SG_ 1138 BMS_chargeCurrentLimitMode "BMS charging current limiting factor";
CM_ SG_ 1138 BMS_timeToFinishHeatForCharge "High-voltage battery management system: time to finish heat for charge; raw 127 = signal not available (SNA)";
CM_ SG_ 1138 BMS_timeToTripPlanChargingTarget "High-voltage battery management system: time to trip plan charging target; raw 2047 = signal not available (SNA)";
CM_ SG_ 1138 BMS_useChargeTimeEstimate "High-voltage battery management system: use charge time estimate";
CM_ BO_ 562 "High-voltage battery management system message: contactor request";
CM_ SG_ 562 BMS_fcContactorRequest "Request indicating which state the BMS would like the fast charge contactors to enter. Position from firmware; message assignment inferred.";
CM_ SG_ 562 BMS_packContactorRequest "Request indicating which state the BMS would like the pack contactors to enter. Position from firmware; message assignment inferred.";
CM_ SG_ 562 BMS_gpoHasCompleted "Position from firmware; message assignment inferred.";
CM_ SG_ 562 BMS_ensShouldBeActiveForDrive "Position from firmware; message assignment inferred.";
CM_ SG_ 562 BMS_pcsPwmDisable "Position from firmware; message assignment inferred.";
CM_ SG_ 562 BMS_fcLinkOkToEnergizeRequest "Position from firmware; message assignment inferred.";
CM_ SG_ 562 BMS_internalHvilSenseV "High-voltage battery management system: internal hvil sense v";
CM_ SG_ 562 BMS_hvilCoverVSense "High-voltage battery management system: hvil cover v sense";
CM_ BO_ 722 "High-voltage battery management system message: drive limits";
CM_ SG_ 722 BMS_minBusVoltage "Calculated min bus voltage limit";
CM_ SG_ 722 BMS_maxBusVoltage "Calculated max bus voltage limit for the pack";
CM_ SG_ 722 BMS_maxChargeCurrent "Calculated max charge current limit for the pack";
CM_ SG_ 722 BMS_maxDischargeCurrent "Calculated max discharge current limit for the pack";
CM_ BO_ 690 "High-voltage battery management system message: energy status";
CM_ SG_ 690 BMS_energyStatusMultiplexer "High-voltage battery management system: energy status multiplexer";
CM_ SG_ 690 BMS_nominalFullPackEnergy "Full pack energy based on calculated pack energy from the full pack discharge energy walk; raw 65535 = signal not available (SNA)";
CM_ SG_ 690 BMS_nominalEnergyRemaining "Nominal energy remaining based on calculated pack energy from the nominal discharge energy walk; raw 65535 = signal not available (SNA)";
CM_ SG_ 690 BMS_idealEnergyRemaining "Ideal energy remaining based on calculated pack energy from ideal discharge energy walk; raw 65535 = signal not available (SNA)";
CM_ SG_ 690 BMS_fullChargeComplete "Indicates BMS is fully charged";
CM_ SG_ 690 BMS_energyBuffer "Rough indication of confidence in the energy estimation; raw 65535 = signal not available (SNA)";
CM_ SG_ 690 BMS_expectedEnergyRemaining "High-voltage battery management system: expected energy remaining; raw 65535 = signal not available (SNA)";
CM_ SG_ 690 BMS_energyToChargeComplete "Calculated energy required to reach charge complete; raw 65535 = signal not available (SNA)";
CM_ SG_ 690 BMS_energyRemainingDisplay "Rubber-banding energy remaining to be used for the UI facing miles remaining display; raw 65535 = signal not available (SNA)";
CM_ SG_ 690 BMS_energyRemainingTDisplay "Rubber-banding energy remaining to be used for the UI facing miles remaining display; raw 65535 = signal not available (SNA)";
CM_ SG_ 690 BMS_energyDisplayErrorBlendRate "Rubber-banding blend rate to be used to ensure consistency between the gauge display and UI energy algorithms";
CM_ SG_ 690 BMS_userFacingSoe "User facing state of energy; raw 2047 = signal not available (SNA)";
CM_ BO_ 306 "High-voltage battery management system message: hv bus status";
CM_ SG_ 306 BMS_dcLinkVoltage "High-voltage battery management system: dc link voltage";
CM_ SG_ 306 BMS_packCurrent "Current measured at the HV contactors of the HV battery; raw 32768 = signal not available (SNA)";
CM_ SG_ 306 BMS_currentUnfiltered "Pack current with no filters applied; raw 32768 = signal not available (SNA)";
CM_ BO_ 768 "High-voltage battery management system message: info";
CM_ SG_ 768 BMS_infoIndex "High-voltage battery management system: info index";
CM_ SG_ 768 BMS_buildType "High-voltage battery management system: build type";
CM_ SG_ 768 BMS_buildConfigId "High-voltage battery management system: build config id";
CM_ SG_ 768 BMS_hardwareId "High-voltage battery management system: hardware id";
CM_ SG_ 768 BMS_componentId "High-voltage battery management system: component id";
CM_ SG_ 768 BMS_pcbaId "BMS' assigned PCBA ID";
CM_ SG_ 768 BMS_assemblyId "BMS' assigned assembly ID";
CM_ SG_ 768 BMS_usageId "BMS' assigned usage ID";
CM_ SG_ 768 BMS_subUsageId "BMS' assigned subusage ID";
CM_ SG_ 768 BMS_platformType "High-voltage battery management system: platform type";
CM_ SG_ 768 BMS_appCrc "High-voltage battery management system: app crc";
CM_ SG_ 768 BMS_appGitHash "High-voltage battery management system: app git hash";
CM_ SG_ 768 BMS_bootGitHash "High-voltage battery management system: boot git hash";
CM_ SG_ 768 BMS_bootUdsProtoVersion "High-voltage battery management system: boot uds proto version";
CM_ SG_ 768 BMS_bootCrc "High-voltage battery management system: boot crc";
CM_ BO_ 978 "High-voltage battery management system message: kwh counter";
CM_ SG_ 978 BMS_kwhDischargeTotal "Total energy-lost kWh count during discharging";
CM_ SG_ 978 BMS_kwhChargeTotal "Total energy-gained kWh count during charging";
CM_ BO_ 1010 "High-voltage battery management system message: kwh counters multiplexed";
CM_ SG_ 1010 BMS_kwhCounter_Id "High-voltage battery management system: kwh counter id";
CM_ SG_ 1010 BMS_acChargerKwhTotal "Total energy-gained kWh count during AC charge";
CM_ SG_ 1010 BMS_dcChargerKwhTotal "Total energy-gained kWh count during DC charging";
CM_ SG_ 1010 BMS_kwhRegenChargeTotal "Total energy-gained kWh count during charging with regen";
CM_ SG_ 1010 BMS_kwhDriveDischargeTotal "Total energy-lost kWh count during discharging while driving";
CM_ SG_ 1010 BMS_kwhDischargeTotalModule1 "Total energy-lost kWh count during discharging for module number (1 indexed)";
CM_ SG_ 1010 BMS_kwhChargeTotalModule1 "Total energy-gained kWh count for module number (1 indexed)";
CM_ SG_ 1010 BMS_kwhAcChargeTotalModule1 "Total energy-gained kWh count during AC charge for module number (1 indexed)";
CM_ SG_ 1010 BMS_kwhDcChargeTotalModule1 "Total energy-gained kWh count during DC charge for module number (1 indexed)";
CM_ SG_ 1010 BMS_kwhDischargeTotalModule2 "Total energy-lost kWh count during discharging for module number (1 indexed)";
CM_ SG_ 1010 BMS_kwhChargeTotalModule2 "Total energy-gained kWh count for module number (1 indexed)";
CM_ SG_ 1010 BMS_kwhAcChargeTotalModule2 "Total energy-gained kWh count during AC charge for module number (1 indexed)";
CM_ SG_ 1010 BMS_kwhDcChargeTotalModule2 "Total energy-gained kWh count during DC charge for module number (1 indexed)";
CM_ SG_ 1010 BMS_kwhDischargeTotalModule3 "Total energy-lost kWh count during discharging for module number (1 indexed)";
CM_ SG_ 1010 BMS_kwhChargeTotalModule3 "Total energy-gained kWh count for module number (1 indexed)";
CM_ SG_ 1010 BMS_kwhAcChargeTotalModule3 "Total energy-gained kWh count during AC charge for module number (1 indexed)";
CM_ SG_ 1010 BMS_kwhDcChargeTotalModule3 "Total energy-gained kWh count during DC charge for module number (1 indexed)";
CM_ SG_ 1010 BMS_kwhDischargeTotalModule4 "Total energy-lost kWh count during discharging for module number (1 indexed)";
CM_ SG_ 1010 BMS_kwhChargeTotalModule4 "Total energy-gained kWh count for module number (1 indexed)";
CM_ SG_ 1010 BMS_kwhAcChargeTotalModule4 "Total energy-gained kWh count during AC charge for module number (1 indexed)";
CM_ SG_ 1010 BMS_kwhDcChargeTotalModule4 "Total energy-gained kWh count during DC charge for module number (1 indexed)";
CM_ BO_ 884 "High-voltage battery management system message: log1";
CM_ SG_ 884 BMS_log1MuxId "High-voltage battery management system: log1 mux id";
CM_ SG_ 884 BMS_powerTransferStatus "Reports the Battery Management System (BMS) power transfer interface state.";
CM_ SG_ 884 BMS_extDcPrechargeVoltageLimit "High-voltage battery management system: ext dc precharge voltage limit";
CM_ SG_ 884 BMS_dcChargeCurrentRequest "The BMS's instantaneous DC charge current request to the EVSE";
CM_ SG_ 884 BMS_dcChargeCurrentLimit "The vehicle's charge current limit on a DC EVSE's output";
CM_ SG_ 884 BMS_dcDischargeEnabled "High-voltage battery management system: dc discharge enabled";
CM_ SG_ 884 BMS_rippleChargeRetryCount "High-voltage battery management system: ripple charge retry count";
CM_ SG_ 884 BMS_dcChargeVoltageLimit "The vehicle's charge voltage limit on a DC EVSE's output";
CM_ SG_ 884 BMS_dcChargePowerLimit "Max power limit for pack during DC charging";
CM_ SG_ 884 BMS_acRealPowerRequest "Reports the instantaneous real AC power command during active power transfer.";
CM_ SG_ 884 BMS_maxExtIsoFcLinkV "The max voltage read on the FC link during the external isolation check";
CM_ SG_ 884 BMS_minModeledPackTemp "High-voltage battery management system: min modeled pack temp";
CM_ SG_ 884 BMS_maxModeledPackTemp "High-voltage battery management system: max modeled pack temp";
CM_ SG_ 884 BMS_energyMaxPredictedBrickTemp "High-voltage battery management system: energy max predicted brick temp";
CM_ SG_ 884 BMS_energyTempGradientAtMaxTemp "High-voltage battery management system: energy temp gradient at max temp";
CM_ SG_ 884 BMS_energyWalkMaxSoc "High-voltage battery management system: energy walk max soc";
CM_ SG_ 884 BMS_energyWalkMinSoc "High-voltage battery management system: energy walk min soc";
CM_ SG_ 884 BMS_chargeEnergyWalkState "High-voltage battery management system: charge energy walk state";
CM_ SG_ 884 BMS_packVoltage "Measures voltage on the battery side of the High Voltage (HV) contactors.";
CM_ SG_ 884 BMS_energyWalkMaxPackCurrent "High-voltage battery management system: energy walk max pack current; raw 32768 = signal not available (SNA)";
CM_ SG_ 884 BMS_energyWalkMaxVehiclePower "High-voltage battery management system: energy walk max vehicle power";
CM_ SG_ 884 BMS_battTempPct "High-voltage battery management system: batt temp pct; raw 255 = signal not available (SNA)";
CM_ SG_ 884 BMS_powerTransferDisableType "High-voltage battery management system: power transfer disable type";
CM_ SG_ 884 BMS_powerTransferDisableReason "High-voltage battery management system: power transfer disable reason";
CM_ SG_ 884 BMS_powerTransferWaitCondition "High-voltage battery management system: power transfer wait condition";
CM_ SG_ 884 BMS_dischargeRetryCount "High-voltage battery management system: discharge retry count";
CM_ SG_ 884 BMS_acChargeDesired "High-voltage battery management system: ac charge desired";
CM_ SG_ 884 BMS_tetheringDesired "High-voltage battery management system: tethering desired";
CM_ SG_ 884 BMS_gridFormDesired "High-voltage battery management system: grid form desired";
CM_ SG_ 884 BMS_gridFollowDesired "High-voltage battery management system: grid follow desired";
CM_ BO_ 946 "High-voltage battery management system message: log2";
CM_ SG_ 946 BMS_log2MuxId "High-voltage battery management system: log2 mux id";
CM_ SG_ 946 BMS_maxChargeRestartNeededByVolt "High-voltage battery management system: max charge restart needed by voltage";
CM_ SG_ 946 BMS_cacAvg "BMS Calculated Ah Capacity (CAC). This is the average of all the brick CACs";
CM_ SG_ 946 BMS_maxChargeNearComplete "High-voltage battery management system: max charge near complete";
CM_ SG_ 946 BMS_cacMin "BMS Calculated Ah Capacity (CAC). This is the min of all the brick CACs";
CM_ SG_ 946 BMS_cacMinBrickId "High-voltage battery management system: cac min brick id";
CM_ SG_ 946 BMS_cacMax "BMS Calculated Ah Capacity (CAC). This is the max of all the brick CACs";
CM_ SG_ 946 BMS_cacMaxBrickId "High-voltage battery management system: cac max brick id";
CM_ SG_ 946 BMS_acRippleConfigNvramValid "High-voltage battery management system: ac ripple config nvram valid";
CM_ SG_ 946 BMS_hvChain_useLeakyBucket "Is the leaky bucket being used - an indicator of the HV Chain Model health";
CM_ SG_ 946 BMS_hvChain_iLimit "High-voltage battery management system: hv chain i limit; raw 16383 = signal not available (SNA)";
CM_ SG_ 946 BMS_hvChain_limitingState "High-voltage battery management system: hv chain limiting state; raw 511 = signal not available (SNA)";
CM_ SG_ 946 BMS_hvChain_limitingStateTempera "High-voltage battery management system: hv chain limiting state temperature; raw 4096 = signal not available (SNA)";
CM_ SG_ 946 BMS_acRippleIsSupported "High-voltage battery management system: ac ripple is supported";
CM_ SG_ 946 BMS_acRippleStartTemperatureMax "High-voltage battery management system: ac ripple start temperature max";
CM_ SG_ 946 BMS_acRippleStartTemperatureMin "High-voltage battery management system: ac ripple start temperature min";
CM_ SG_ 946 BMS_fcLinkTestDecayTime "High-voltage battery management system: fc link test decay time; raw 1023 = signal not available (SNA)";
CM_ SG_ 946 BMS_fcLinkTestTimeSinceLastRun "High-voltage battery management system: fc link test time since last run";
CM_ SG_ 946 BMS_pcsPrechargeRequest "Enum indicating the active precharge request type from BMS to PCS";
CM_ SG_ 946 BMS_pcsPrechargeTargetVoltage "Target voltage for precharging HV bus";
CM_ SG_ 946 BMS_recentOvUvAlert "At least one of the Brick OV or UV alerts has been active recently; consumed by BMS_a049_SW_Thermal_Event set condition";
CM_ SG_ 946 BMS_recentIsoAlert "At least one of the isolation alerts has been active recently; consumed by BMS_a049_SW_Thermal_Event set condition";
CM_ SG_ 946 BMS_recentBmbMiaAlert "At least one of the BMB communication alerts has been active recently; consumed by BMS_a049_SW_Thermal_Event set condition";
CM_ SG_ 946 BMS_cacBlendingConfigNvramValid "High-voltage battery management system: cac blending config nvram valid";
CM_ SG_ 946 BMS_cacBlendingEnabled "High-voltage battery management system: cac blending enabled";
CM_ SG_ 946 BMS_cacBlendPercentPerCycle "High-voltage battery management system: cac blend percent per cycle";
CM_ SG_ 946 BMS_energyVariableChgRequested "High-voltage battery management system: energy variable chg requested";
CM_ SG_ 946 BMS_packRestTime "Minimum resting time of all bricks";
CM_ SG_ 946 BMS_idealEnergyFloor "Ideal energy estimate based on the min bounded SOC that accounts for accumulated shunt error; raw 1023 = signal not available (SNA)";
CM_ SG_ 946 BMS_thmGradientSlopeCondition "High-voltage battery management system: thm gradient slope condition";
CM_ SG_ 946 BMS_recentSlopeConditon "High-voltage battery management system: recent slope conditon";
CM_ SG_ 946 BMS_dynamicEnergyBuffer "BMS estimate of energy error based on SOC measurement inaccuracy; raw 1023 = signal not available (SNA)";
CM_ SG_ 946 BMS_temperatureCondition "High-voltage battery management system: temperature condition";
CM_ SG_ 946 BMS_thmGradientSlope "High-voltage battery management system: thm gradient slope";
CM_ SG_ 946 BMS_thmGradient "High-voltage battery management system: thm gradient";
CM_ SG_ 946 BMS_epochTimeEstimate "High-voltage battery management system: epoch time estimate";
CM_ SG_ 946 BMS_histogramStartTimeIrrational "High-voltage battery management system: histogram start time irrational";
CM_ SG_ 946 BMS_histogramDischargeThroughput "High-voltage battery management system: histogram discharge throughput irrational";
CM_ SG_ 946 BMS_histogramChargeThroughputIrr "High-voltage battery management system: histogram charge throughput irrational";
CM_ SG_ 946 BMS_histogramTotalTimeIrrational "High-voltage battery management system: histogram total time irrational";
CM_ SG_ 946 BMS_histogramStorageDataIsLow "High-voltage battery management system: histogram storage data is low";
CM_ SG_ 946 BMS_tempVsSocTotalChgEnergy "High-voltage battery management system: temp vs soc total chg energy";
CM_ SG_ 946 BMS_powerVsVoltageTotalChgEnergy "High-voltage battery management system: power vs voltage total chg energy";
CM_ SG_ 946 BMS_lifeModelOutputsAreTrustwort "High-voltage battery management system: life model outputs are trustworthy";
CM_ SG_ 946 BMS_dSocNormalizedMin "High-voltage battery management system: d soc normalized min; raw 4095 = signal not available (SNA)";
CM_ SG_ 946 BMS_dSocNormalizedFiltMin "High-voltage battery management system: d soc normalized filt min; raw 4095 = signal not available (SNA)";
CM_ SG_ 946 BMS_dSocMinAlpha "minimum calculated alpha value across all bricks and all dSOC calculations; raw 4095 = signal not available (SNA)";
CM_ SG_ 946 BMS_dSocMaxLowAlphaCounter "High-voltage battery management system: d soc max low alpha counter";
CM_ SG_ 946 BMS_dSocMinAlphaBrickID "High-voltage battery management system: d soc min alpha brick ID";
CM_ SG_ 946 BMS_dSocCacMargin "High-voltage battery management system: d soc cac margin; raw 511 = signal not available (SNA)";
CM_ SG_ 946 BMS_lifeModelNoCurrentStorageCap "High-voltage battery management system: life model no current storage capacity loss; raw 511 = signal not available (SNA)";
CM_ SG_ 946 BMS_lifeModelShortDcr "High-voltage battery management system: life model short dcr; raw 255 = signal not available (SNA)";
CM_ SG_ 946 BMS_lifeModelLongDcr "High-voltage battery management system: life model long dcr; raw 4096 = signal not available (SNA)";
CM_ SG_ 946 BMS_lifeModelStorageCapacityLoss "High-voltage battery management system: life model storage capacity loss; raw 511 = signal not available (SNA)";
CM_ SG_ 946 BMS_lifeModelThroughputCapacityL "High-voltage battery management system: life model throughput capacity loss; raw 511 = signal not available (SNA)";
CM_ SG_ 946 BMS_passiveCoolCellTargetT "High-voltage battery management system: passive cool cell target t";
CM_ SG_ 946 BMS_lifeModelAvgTempSeverity "High-voltage battery management system: life model avg temp severity; raw 31 = signal not available (SNA)";
CM_ SG_ 946 BMS_lifeModelDepthOfDischargeSev "High-voltage battery management system: life model depth of discharge severity; raw 255 = signal not available (SNA)";
CM_ SG_ 946 BMS_lifeModelHistogramCapacityLo "High-voltage battery management system: life model histogram capacity loss; raw 511 = signal not available (SNA)";
CM_ SG_ 946 BMS_lifeModelHistogramBrickCapac "High-voltage battery management system: life model histogram brick capacity; raw 8191 = signal not available (SNA)";
CM_ SG_ 946 BMS_lifeModelDcrGrowthPercent "High-voltage battery management system: life model dcr growth percent; raw 8192 = signal not available (SNA)";
CM_ SG_ 946 BMS_nominalFullPackEnergyRaw "Non-latched version of BMS_nominalEnergyRemaining; raw 65535 = signal not available (SNA)";
CM_ SG_ 946 BMS_nominalEnergyRemainingBuffer "Buffered version of BMS_nominalEnergyRemaining; raw 65535 = signal not available (SNA)";
CM_ SG_ 946 BMS_idealEnergyRemainingBuffered "Buffered version of BMS_idealEnergyRemaining; raw 65535 = signal not available (SNA)";
CM_ SG_ 946 BMS_largestSynchronizedCacErrorP "High-voltage battery management system: largest synchronized cac error pct; raw 255 = signal not available (SNA)";
CM_ SG_ 946 BMS_lifeModelSpreadMinOffset "High-voltage battery management system: life model spread min offset";
CM_ SG_ 946 BMS_lifeModelSpreadMaxOffset "High-voltage battery management system: life model spread max offset";
CM_ SG_ 946 BMS_largestCacSpreadErrorLower "High-voltage battery management system: largest cac spread error lower; raw 4095 = signal not available (SNA)";
CM_ SG_ 946 BMS_lifeModelAverageCac "High-voltage battery management system: life model average cac; raw 4095 = signal not available (SNA)";
CM_ SG_ 946 BMS_lifeModelCacBrick1 "High-voltage battery management system: life model cac brick1; raw 4095 = signal not available (SNA)";
CM_ SG_ 946 BMS_lifeModelAverageOffset "High-voltage battery management system: life model average offset; raw 512 = signal not available (SNA)";
CM_ SG_ 946 BMS_percentCacUpdatesInTimeWindo "High-voltage battery management system: percent cac updates in time window";
CM_ SG_ 946 BMS_lifeModelMaxCacBrickId "High-voltage battery management system: life model max cac brick id; raw 255 = signal not available (SNA)";
CM_ SG_ 946 BMS_lifeModelMaxCac "High-voltage battery management system: life model max cac; raw 4095 = signal not available (SNA)";
CM_ SG_ 946 BMS_lifeModelMinCacBrickId "High-voltage battery management system: life model min cac brick id; raw 255 = signal not available (SNA)";
CM_ SG_ 946 BMS_lifeModelMinCac "High-voltage battery management system: life model min cac; raw 4095 = signal not available (SNA)";
CM_ SG_ 946 BMS_restingPointCacAvg "High-voltage battery management system: resting point cac avg; raw 4095 = signal not available (SNA)";
CM_ SG_ 946 BMS_cacEstimationSource "High-voltage battery management system: cac estimation source";
CM_ SG_ 946 BMS_packCalibrationBirthDateBinn "High-voltage battery management system: pack calibration birth date binned";
CM_ SG_ 946 BMS_synchronizedCacMaxRaw "High-voltage battery management system: synchronized cac max raw; raw 4095 = signal not available (SNA)";
CM_ SG_ 946 BMS_synchronizedCacMinRaw "High-voltage battery management system: synchronized cac min raw; raw 4095 = signal not available (SNA)";
CM_ SG_ 946 BMS_largestSyncCacErrorStartSoc "Start SOC for CAC update from the brick with the highest synchronized CAC error";
CM_ SG_ 946 BMS_largestSyncCacErrorEndSoc "Start SOC for CAC update from the brick with the highest synchronized CAC error";
CM_ SG_ 946 BMS_runtimeSocConfigNvramValid "High-voltage battery management system: runtime soc config nvram valid";
CM_ SG_ 946 BMS_runtimeSocCorrectionsEnabled "High-voltage battery management system: runtime soc corrections enabled";
CM_ SG_ 946 BMS_rubberBandingEnabled "Reports whether rubber banding of output energy corrections is enabled.";
CM_ SG_ 946 BMS_rubberBandingConfigNvramVali "High-voltage battery management system: rubber banding config nvram valid";
CM_ SG_ 946 BMS_runtimeSocMinTempForModel "High-voltage battery management system: runtime soc min temp for model";
CM_ SG_ 946 BMS_energyBufferConfigNvramValid "High-voltage battery management system: energy buffer config nvram valid";
CM_ SG_ 946 BMS_thermalEvent1pDetectConfigDi "High-voltage battery management system: thermal event1p detect config disabled";
CM_ SG_ 946 BMS_sohEnergy "Battery SOH energy estimate. If calibrated SOH capacity is unavailable, this value is a filtered result from brick CACs; raw 2047 = signal not available (SNA)";
CM_ SG_ 946 BMS_fullCapacitySohEnergy "Energy estimate using nominal brick capacity at maximum SOC using SOH retention test conditions; raw 2047 = signal not available (SNA)";
CM_ SG_ 946 BMS_calibratedCapacitySohEnergy "Energy estimate using CAC from the most recent valid SOH test at maximum SOC using SOH retention test conditions; raw 2047 = signal not available (SNA)";
CM_ SG_ 946 BMS_estimatedCapacitySohEnergy "Energy estimate using filtered brick capacities at maximum SOC using SOH retention test conditions; raw 2047 = signal not available (SNA)";
CM_ SG_ 946 BMS_prevUserFacingSohEnergy "The last soh energy stored in NVM for rate limiting purposes; raw 2047 = signal not available (SNA)";
CM_ SG_ 946 BMS_stateOfHealthMinCac "Reports the minimum Calculated Amp-hour Capacity (CAC) by aged Open Circuit Voltage (OCV) raw values across bricks that could be used in State of Health (SOH) calculations; raw 8191 = signal not available (SNA)";
CM_ SG_ 946 BMS_lifeModelStorageLossPackAge "High-voltage battery management system: life model storage loss pack age; raw 16383 = signal not available (SNA)";
CM_ SG_ 946 BMS_lifeModelThroughputDcrCycleC "High-voltage battery management system: life model throughput dcr cycle count; raw 4095 = signal not available (SNA)";
CM_ SG_ 946 BMS_stateOfHealthMinCacLowerBoun "Reports the minimum Calculated Amp-hour Capacity (CAC) by aged Open Circuit Voltage (OCV) raw lower bound values across bricks that could be used in State of Health (SOH) calculations; raw 8191 = signal not available (SNA)";
CM_ SG_ 946 BMS_energyWalkCounter "High-voltage battery management system: energy walk counter";
CM_ SG_ 946 BMS_energyWalkTimeoutCounter "High-voltage battery management system: energy walk timeout counter";
CM_ SG_ 946 BMS_dynamicCcvEnabled "High-voltage battery management system: dynamic ccv enabled";
CM_ SG_ 946 BMS_chargeTargetLookupSoc "High-voltage battery management system: charge target lookup soc";
CM_ SG_ 946 BMS_stateOfHealth "Most recent battery capacity estimate, from a successful SOH test in %; raw 1023 = signal not available (SNA)";
CM_ SG_ 946 BMS_avgShuntAsicCurrentOffset "High-voltage battery management system: avg shunt asic current offset; raw 16384 = signal not available (SNA)";
CM_ SG_ 946 BMS_cellAttributesGeneralAttribu "High-voltage battery management system: cell attributes general attributes; raw 0 = signal not available (SNA)";
CM_ SG_ 946 BMS_cellAttributesPackManufactur "High-voltage battery management system: cell attributes pack manufacturing location; raw 0 = signal not available (SNA)";
CM_ SG_ 946 BMS_cellAttributesRemanufactured "High-voltage battery management system: cell attributes remanufactured pack";
CM_ SG_ 946 BMS_cellAttributesConfigNvramVal "High-voltage battery management system: cell attributes config nvram valid";
CM_ SG_ 946 BMS_cellAttributesCellType "High-voltage battery management system: cell attributes cell type; raw 0 = signal not available (SNA)";
CM_ SG_ 946 BMS_cellAttributesAutocloseAndSc "High-voltage battery management system: cell attributes autoclose and scrap pack on field return";
CM_ SG_ 946 BMS_cellAttributesShipPackForFai "High-voltage battery management system: cell attributes ship pack for failure analysis";
CM_ SG_ 946 BMS_lifeModelThroughputCycleCoun "High-voltage battery management system: life model throughput cycle count; raw 4095 = signal not available (SNA)";
CM_ SG_ 946 BMS_limpChargeCurrentLimit "DC current limit based on limp mode; raw 1023 = signal not available (SNA)";
CM_ SG_ 946 BMS_energyRemainingDisplayError "High-voltage battery management system: energy remaining display error";
CM_ SG_ 946 BMS_energyRemainingTDisplayError "High-voltage battery management system: energy remaining t display error";
CM_ SG_ 946 BMS_numOfThermistors "Measures the number of thermistors in the battery pack for temperature monitoring.";
CM_ SG_ 946 BMS_numOfBricks "Measures the number of battery bricks (modules or cell groups) in the pack.";
CM_ SG_ 946 BMS_cellChargeDcCurrentLimit "DC current target based on cell voltage & temp tables";
CM_ SG_ 946 BMS_socByDeltaVEnabled "High-voltage battery management system: soc by delta v enabled";
CM_ SG_ 946 BMS_socByDvMaxSocLimit "High-voltage battery management system: soc by dv max soc limit";
CM_ SG_ 946 BMS_socByDvVoltageChangeOverAh "High-voltage battery management system: soc by dv voltage change over ah";
CM_ SG_ 946 BMS_socByDvMaxSocByAhCorrected "High-voltage battery management system: soc by dv max soc by ah corrected";
CM_ SG_ 946 BMS_socByDvMaxBrickVoltage "High-voltage battery management system: soc by dv max brick voltage";
CM_ SG_ 946 BMS_socByDvMaxBrickId "High-voltage battery management system: soc by dv max brick id";
CM_ SG_ 946 BMS_socByDvMaxSocByAhRaw "High-voltage battery management system: soc by dv max soc by ah raw";
CM_ SG_ 946 BMS_voltageInstabilityExcessNois "High-voltage battery management system: voltage instability excess noise log";
CM_ SG_ 946 BMS_maxModelThermistorTempDelta "High-voltage battery management system: max model thermistor temp delta; raw 512 = signal not available (SNA)";
CM_ SG_ 946 BMS_activeCoolCellTargetT "High-voltage battery management system: active cool cell target t";
CM_ SG_ 946 BMS_cellTempTargetMode "Operating mode of the thermal controls for the Battery Management System (BMS)";
CM_ SG_ 946 BMS_minPackTempForChargeToStart "High-voltage battery management system: min pack temp for charge to start";
CM_ BO_ 914 "High-voltage battery management system message: pack config";
CM_ SG_ 914 BMS_packConfigMultiplexer "High-voltage battery management system: pack config multiplexer";
CM_ SG_ 914 BMS_reservedConfig_0 "High-voltage battery management system: reserved config 0";
CM_ SG_ 914 BMS_moduleType "High-voltage battery management system: module type";
CM_ SG_ 914 BMS_thermalPackType "High-voltage battery management system: thermal pack type";
CM_ SG_ 914 BMS_packMass "High-voltage battery management system: pack mass";
CM_ SG_ 914 BMS_platformMaxBusVoltage "High-voltage battery management system: platform max bus voltage";
CM_ SG_ 914 BMS_standbySupplyContinuousPower "High-voltage battery management system: standby supply continuous power limit";
CM_ SG_ 914 BMS_beginningOfLifePackEnergy "High-voltage battery management system: beginning of life pack energy; raw 1023 = signal not available (SNA)";
BA_DEF_ BO_ "GenMsgCycleTime" INT 0 3600000;
BA_DEF_ BO_ "GenMsgSendType" ENUM "Cyclic","NotUsed","NotUsed","NotUsed","NotUsed","NotUsed","NotUsed","IfActive","NoMsgSendType","NotUsed";
BA_DEF_ BO_ "VFrameFormat" ENUM "StandardCAN","ExtendedCAN","reserved","J1939PG","reserved","reserved","reserved","reserved","reserved","reserved","reserved","reserved","reserved","reserved","StandardCAN_FD","ExtendedCAN_FD";
BA_DEF_ BO_ "CANFD_BRS" ENUM "0","1";
BA_DEF_ SG_ "GenSigSNA" STRING;
BA_DEF_ SG_ "SystemSignalLongSymbol" STRING;
BA_DEF_ SG_ "Confidence" ENUM "validated","plausible","layout-only","contradicted";
BA_DEF_DEF_ "GenMsgCycleTime" 0;
BA_DEF_DEF_ "GenMsgSendType" "NoMsgSendType";
BA_DEF_DEF_ "VFrameFormat" "StandardCAN";
BA_DEF_DEF_ "CANFD_BRS" "1";
BA_DEF_DEF_ "GenSigSNA" "";
BA_DEF_DEF_ "SystemSignalLongSymbol" "";
BA_DEF_DEF_ "Confidence" "layout-only";
BA_ "GenMsgCycleTime" BO_ 800 1000;
BA_ "GenMsgSendType" BO_ 800 0;
BA_ "GenMsgCycleTime" BO_ 818 1000;
BA_ "GenMsgSendType" BO_ 818 0;
BA_ "GenMsgCycleTime" BO_ 1025 1000;
BA_ "GenMsgSendType" BO_ 1025 0;
BA_ "GenMsgCycleTime" BO_ 1138 1000;
BA_ "GenMsgSendType" BO_ 1138 0;
BA_ "GenMsgCycleTime" BO_ 562 1000;
BA_ "GenMsgSendType" BO_ 562 0;
BA_ "GenMsgCycleTime" BO_ 722 100;
BA_ "GenMsgSendType" BO_ 722 0;
BA_ "GenMsgCycleTime" BO_ 690 2000;
BA_ "GenMsgSendType" BO_ 690 0;
BA_ "GenMsgCycleTime" BO_ 306 10;
BA_ "GenMsgSendType" BO_ 306 0;
BA_ "GenMsgCycleTime" BO_ 768 1000;
BA_ "GenMsgSendType" BO_ 768 0;
BA_ "GenMsgCycleTime" BO_ 978 1000;
BA_ "GenMsgSendType" BO_ 978 0;
BA_ "GenMsgCycleTime" BO_ 1010 1000;
BA_ "GenMsgSendType" BO_ 1010 0;
BA_ "GenMsgCycleTime" BO_ 884 1000;
BA_ "GenMsgSendType" BO_ 884 0;
BA_ "GenMsgCycleTime" BO_ 946 30000;
BA_ "GenMsgSendType" BO_ 946 0;
BA_ "GenMsgCycleTime" BO_ 914 1000;
BA_ "GenMsgSendType" BO_ 914 0;
BA_ "Confidence" SG_ 800 BMS_matrixIndex 1;
BA_ "SystemSignalLongSymbol" SG_ 800 BMS_a002_Pack_Performance_Config "BMS_a002_Pack_Performance_Config_Mismatch";
BA_ "SystemSignalLongSymbol" SG_ 800 BMS_a003_SW_Pack_Birth_Date_Miss "BMS_a003_SW_Pack_Birth_Date_Missing";
BA_ "SystemSignalLongSymbol" SG_ 800 BMS_a004_Cal_Vs_Serial_Birth_Dat "BMS_a004_Cal_Vs_Serial_Birth_Date_Mismatch";
BA_ "SystemSignalLongSymbol" SG_ 800 BMS_a027_SW_Repeated_Isolation_F "BMS_a027_SW_Repeated_Isolation_Failure_In_Drive";
BA_ "SystemSignalLongSymbol" SG_ 800 BMS_a028_ShuntAsicCurrentOffsetD "BMS_a028_ShuntAsicCurrentOffsetDeviation";
BA_ "SystemSignalLongSymbol" SG_ 800 BMS_a040_SW_Watch_Dog_HW_Trigger "BMS_a040_SW_Watch_Dog_HW_Triggered";
BA_ "SystemSignalLongSymbol" SG_ 800 BMS_a041_SW_Destructive_Reset_So "BMS_a041_SW_Destructive_Reset_Source";
BA_ "SystemSignalLongSymbol" SG_ 800 BMS_a057_SW_Bandolier_Model_Warn "BMS_a057_SW_Bandolier_Model_Warning";
BA_ "SystemSignalLongSymbol" SG_ 800 BMS_a058_SW_Bandolier_Model_Rese "BMS_a058_SW_Bandolier_Model_Reset";
BA_ "SystemSignalLongSymbol" SG_ 800 BMS_a070_BrickV_Imbalance_Limiti "BMS_a070_BrickV_Imbalance_Limiting";
BA_ "SystemSignalLongSymbol" SG_ 800 BMS_a074_Max_Charge_Level_Reduce "BMS_a074_Max_Charge_Level_Reduced";
BA_ "SystemSignalLongSymbol" SG_ 800 BMS_a078_Rapid_Dch_While_Chargin "BMS_a078_Rapid_Dch_While_Charging";
BA_ "SystemSignalLongSymbol" SG_ 800 BMS_a079_Max_Charge_Level_Exceed "BMS_a079_Max_Charge_Level_Exceeded";
BA_ "SystemSignalLongSymbol" SG_ 800 BMS_a085_SW_Pack_Contactor_Misma "BMS_a085_SW_Pack_Contactor_Mismatch";
BA_ "SystemSignalLongSymbol" SG_ 800 BMS_a086_SW_FC_Contactor_Mismatc "BMS_a086_SW_FC_Contactor_Mismatch";
BA_ "SystemSignalLongSymbol" SG_ 800 BMS_a092_SW_ChargePort_Mia_On_Hv "BMS_a092_SW_ChargePort_Mia_On_Hvs";
BA_ "SystemSignalLongSymbol" SG_ 800 BMS_a097_SW_BMB_Over_CAN_Communi "BMS_a097_SW_BMB_Over_CAN_Communication";
BA_ "SystemSignalLongSymbol" SG_ 800 BMS_a098_SW_BMB_Data_Integrity_L "BMS_a098_SW_BMB_Data_Integrity_Loss";
BA_ "SystemSignalLongSymbol" SG_ 800 BMS_a109_HW_BMB_Mute_Status_Mism "BMS_a109_HW_BMB_Mute_Status_Mismatch";
BA_ "SystemSignalLongSymbol" SG_ 800 BMS_a110_LifeModel_AvgOffset_Cha "BMS_a110_LifeModel_AvgOffset_Change";
BA_ "SystemSignalLongSymbol" SG_ 800 BMS_a115_Energy_Rubberbanding_Re "BMS_a115_Energy_Rubberbanding_Reset";
BA_ "SystemSignalLongSymbol" SG_ 800 BMS_a118_SW_Delta_SOC_Weak_Short "BMS_a118_SW_Delta_SOC_Weak_Short_Warning";
BA_ "SystemSignalLongSymbol" SG_ 800 BMS_a120_SW_Delta_SOC_User_Warni "BMS_a120_SW_Delta_SOC_User_Warning";
BA_ "SystemSignalLongSymbol" SG_ 800 BMS_a135_HW_BMB_Diagnostics_Fail "BMS_a135_HW_BMB_Diagnostics_Failure";
BA_ "SystemSignalLongSymbol" SG_ 800 BMS_a142_SW_Isolation_Degradatio "BMS_a142_SW_Isolation_Degradation";
BA_ "SystemSignalLongSymbol" SG_ 800 BMS_a148_SW_Unsupported_BMB_ASIC "BMS_a148_SW_Unsupported_BMB_ASIC_Type";
BA_ "SystemSignalLongSymbol" SG_ 800 BMS_a154_SW_Brick_OV_Warning_Sto "BMS_a154_SW_Brick_OV_Warning_Stop_Charge";
BA_ "SystemSignalLongSymbol" SG_ 800 BMS_a172_SW_Isolation_Failure_In "BMS_a172_SW_Isolation_Failure_In_Drive_Warning";
BA_ "SystemSignalLongSymbol" SG_ 800 BMS_a178_SW_Uncontrolled_Regen_P "BMS_a178_SW_Uncontrolled_Regen_PwrB";
BA_ "SystemSignalLongSymbol" SG_ 800 BMS_a181_SW_Shunt_Over_Temperatu "BMS_a181_SW_Shunt_Over_Temperature";
BA_ "SystemSignalLongSymbol" SG_ 800 BMS_a182_LifeModel_NoCurrentLoss "BMS_a182_LifeModel_NoCurrentLoss_Change";
BA_ "SystemSignalLongSymbol" SG_ 800 BMS_a183_LifeModel_StoDcrGrowth_ "BMS_a183_LifeModel_StoDcrGrowth_Change";
BA_ "SystemSignalLongSymbol" SG_ 800 BMS_a184_LifeModel_CyclingLoss_C "BMS_a184_LifeModel_CyclingLoss_Change";
BA_ "SystemSignalLongSymbol" SG_ 800 BMS_a185_LifeModel_CyclingDcrGro "BMS_a185_LifeModel_CyclingDcrGrowth_Change";
BA_ "SystemSignalLongSymbol" SG_ 800 BMS_a186_RippleHeatingChargeFaul "BMS_a186_RippleHeatingChargeFault";
BA_ "SystemSignalLongSymbol" SG_ 800 BMS_a187_RippleHeatingEmergencyS "BMS_a187_RippleHeatingEmergencyShutdown";
BA_ "SystemSignalLongSymbol" SG_ 800 BMS_a188_PowershareChargeCurrent "BMS_a188_PowershareChargeCurrentViolation";
BA_ "SystemSignalLongSymbol" SG_ 800 BMS_a189_PowershareDischargeCurr "BMS_a189_PowershareDischargeCurrentViolation";
BA_ "SystemSignalLongSymbol" SG_ 800 BMS_a190_PowershareMaxVoltageVio "BMS_a190_PowershareMaxVoltageViolation";
BA_ "SystemSignalLongSymbol" SG_ 800 BMS_a191_PowershareMinVoltageVio "BMS_a191_PowershareMinVoltageViolation";
BA_ "SystemSignalLongSymbol" SG_ 800 BMS_a192_PowershareExternalCharg "BMS_a192_PowershareExternalChargeRegulation";
BA_ "SystemSignalLongSymbol" SG_ 800 BMS_a193_PowershareMaxBrickVolta "BMS_a193_PowershareMaxBrickVoltageViolation";
BA_ "SystemSignalLongSymbol" SG_ 800 BMS_a194_PowershareLimitViolatio "BMS_a194_PowershareLimitViolation";
BA_ "SystemSignalLongSymbol" SG_ 800 BMS_a195_SW_DeltaTempOverThresho "BMS_a195_SW_DeltaTempOverThreshold";
BA_ "SystemSignalLongSymbol" SG_ 800 BMS_a196_SW_PackVoltageUnderThre "BMS_a196_SW_PackVoltageUnderThreshold";
BA_ "SystemSignalLongSymbol" SG_ 800 BMS_a201_SW_Brick_OV_During_Char "BMS_a201_SW_Brick_OV_During_Charge";
BA_ "SystemSignalLongSymbol" SG_ 800 BMS_a204_AcCpEmergencyShutdownRe "BMS_a204_AcCpEmergencyShutdownRequested";
BA_ "SystemSignalLongSymbol" SG_ 800 BMS_a221_PcsEmergencyShutdownReq "BMS_a221_PcsEmergencyShutdownRequested";
BA_ "SystemSignalLongSymbol" SG_ 800 BMS_a227_ExcessChargeCurrentInCh "BMS_a227_ExcessChargeCurrentInCharge";
BA_ "SystemSignalLongSymbol" SG_ 800 BMS_d259_highVoltageInterlockFai "BMS_d259_highVoltageInterlockFailure";
BA_ "SystemSignalLongSymbol" SG_ 800 BMS_d260_chargePortInterlockFail "BMS_d260_chargePortInterlockFailure";
BA_ "SystemSignalLongSymbol" SG_ 800 BMS_d261_batteryPackCellVoltageH "BMS_d261_batteryPackCellVoltageHigh";
BA_ "SystemSignalLongSymbol" SG_ 800 BMS_d262_batteryPackLowStateOfCh "BMS_d262_batteryPackLowStateOfCharge";
BA_ "SystemSignalLongSymbol" SG_ 800 BMS_d263_batterySystemCurrentHig "BMS_d263_batterySystemCurrentHigh";
BA_ "SystemSignalLongSymbol" SG_ 800 BMS_d267_batteryPackCellVoltageS "BMS_d267_batteryPackCellVoltageSenseHarnessFailure";
BA_ "SystemSignalLongSymbol" SG_ 800 BMS_d268_hvpInvalidFirmwareConfi "BMS_d268_hvpInvalidFirmwareConfig";
BA_ "SystemSignalLongSymbol" SG_ 800 BMS_d271_batteryPackSensorFailur "BMS_d271_batteryPackSensorFailure";
BA_ "SystemSignalLongSymbol" SG_ 800 BMS_d272_batteryPackSensorCommsL "BMS_d272_batteryPackSensorCommsLost";
BA_ "SystemSignalLongSymbol" SG_ 800 BMS_d274_packCurrentSensorACircu "BMS_d274_packCurrentSensorACircuitFailure";
BA_ "SystemSignalLongSymbol" SG_ 800 BMS_d275_packPosContactorACircui "BMS_d275_packPosContactorACircuitFailure";
BA_ "SystemSignalLongSymbol" SG_ 800 BMS_d276_packPosContactorAStuckC "BMS_d276_packPosContactorAStuckClosed";
BA_ "SystemSignalLongSymbol" SG_ 800 BMS_d277_packNegContactorACircui "BMS_d277_packNegContactorACircuitFailure";
BA_ "SystemSignalLongSymbol" SG_ 800 BMS_d278_packNegContactorAStuckC "BMS_d278_packNegContactorAStuckClosed";
BA_ "SystemSignalLongSymbol" SG_ 800 BMS_d279_fastChargePosContactorA "BMS_d279_fastChargePosContactorACircuitFailure";
BA_ "SystemSignalLongSymbol" SG_ 800 BMS_d280_fastChargePosContactorA "BMS_d280_fastChargePosContactorAStuckClosed";
BA_ "SystemSignalLongSymbol" SG_ 800 BMS_d281_fastChargePosContactorA "BMS_d281_fastChargePosContactorAStuckOpen";
BA_ "SystemSignalLongSymbol" SG_ 800 BMS_d282_fastChargeNegContactorA "BMS_d282_fastChargeNegContactorACircuitFailure";
BA_ "SystemSignalLongSymbol" SG_ 800 BMS_d283_fastChargeNegContactorA "BMS_d283_fastChargeNegContactorAStuckClosed";
BA_ "SystemSignalLongSymbol" SG_ 800 BMS_d284_fastChargeNegContactorA "BMS_d284_fastChargeNegContactorAStuckOpen";
BA_ "SystemSignalLongSymbol" SG_ 800 BMS_d285_packVoltageSensorACircu "BMS_d285_packVoltageSensorACircuitFailure";
BA_ "SystemSignalLongSymbol" SG_ 800 BMS_d288_batteryPackCellVoltageL "BMS_d288_batteryPackCellVoltageLow";
BA_ "SystemSignalLongSymbol" SG_ 800 BMS_d289_batteryPackAOverTempera "BMS_d289_batteryPackAOverTemperature";
BA_ "SystemSignalLongSymbol" SG_ 800 BMS_d290_batteryPackTempSensorAC "BMS_d290_batteryPackTempSensorACircuitFailure";
BA_ "SystemSignalLongSymbol" SG_ 800 BMS_a291_SOC_Imbalance_By_Delta_ "BMS_a291_SOC_Imbalance_By_Delta_Voltage_Over_Delta_SOC";
BA_ "Confidence" SG_ 818 BMS_bmbMinMaxMultiplexer 1;
BA_ "Confidence" SG_ 818 BMS_thermistorNumTMin 0;
BA_ "Confidence" SG_ 818 BMS_thermistorNumTMax 0;
BA_ "Confidence" SG_ 818 BMS_thermistorTMax 0;
BA_ "Confidence" SG_ 818 BMS_thermistorTMin 0;
BA_ "Confidence" SG_ 818 BMS_thermistorTAvg 0;
BA_ "Confidence" SG_ 818 BMS_brickVoltageMax 0;
BA_ "Confidence" SG_ 818 BMS_brickVoltageMin 0;
BA_ "Confidence" SG_ 818 BMS_brickNumVoltageMax 0;
BA_ "Confidence" SG_ 818 BMS_brickNumVoltageMin 0;
BA_ "Confidence" SG_ 1025 BMS_brickVoltageMultiplexer 1;
BA_ "Confidence" SG_ 1025 BMS_brickVoltageCounter 0;
BA_ "Confidence" SG_ 1025 BMS_brickVoltageStatus1 0;
BA_ "Confidence" SG_ 1025 BMS_brickVoltageStatus2 0;
BA_ "Confidence" SG_ 1025 BMS_brickVoltageStatus3 0;
BA_ "Confidence" SG_ 1025 BMS_brickVoltage1 0;
BA_ "Confidence" SG_ 1025 BMS_brickVoltage2 0;
BA_ "Confidence" SG_ 1025 BMS_brickVoltage3 0;
BA_ "Confidence" SG_ 1025 BMS_brickVoltageStatus4 0;
BA_ "Confidence" SG_ 1025 BMS_brickVoltageStatus5 0;
BA_ "Confidence" SG_ 1025 BMS_brickVoltageStatus6 0;
BA_ "Confidence" SG_ 1025 BMS_brickVoltage4 0;
BA_ "Confidence" SG_ 1025 BMS_brickVoltage5 0;
BA_ "Confidence" SG_ 1025 BMS_brickVoltage6 0;
BA_ "Confidence" SG_ 1025 BMS_brickVoltageStatus7 0;
BA_ "Confidence" SG_ 1025 BMS_brickVoltageStatus8 0;
BA_ "Confidence" SG_ 1025 BMS_brickVoltageStatus9 0;
BA_ "Confidence" SG_ 1025 BMS_brickVoltage7 0;
BA_ "Confidence" SG_ 1025 BMS_brickVoltage8 0;
BA_ "Confidence" SG_ 1025 BMS_brickVoltage9 0;
BA_ "Confidence" SG_ 1025 BMS_brickVoltageStatus10 0;
BA_ "Confidence" SG_ 1025 BMS_brickVoltageStatus11 0;
BA_ "Confidence" SG_ 1025 BMS_brickVoltageStatus12 0;
BA_ "Confidence" SG_ 1025 BMS_brickVoltage10 0;
BA_ "Confidence" SG_ 1025 BMS_brickVoltage11 0;
BA_ "Confidence" SG_ 1025 BMS_brickVoltage12 0;
BA_ "Confidence" SG_ 1025 BMS_brickVoltageStatus13 0;
BA_ "Confidence" SG_ 1025 BMS_brickVoltageStatus14 0;
BA_ "Confidence" SG_ 1025 BMS_brickVoltageStatus15 0;
BA_ "Confidence" SG_ 1025 BMS_brickVoltage13 0;
BA_ "Confidence" SG_ 1025 BMS_brickVoltage14 0;
BA_ "Confidence" SG_ 1025 BMS_brickVoltage15 0;
BA_ "Confidence" SG_ 1025 BMS_brickVoltageStatus16 0;
BA_ "Confidence" SG_ 1025 BMS_brickVoltageStatus17 0;
BA_ "Confidence" SG_ 1025 BMS_brickVoltageStatus18 0;
BA_ "Confidence" SG_ 1025 BMS_brickVoltage16 0;
BA_ "Confidence" SG_ 1025 BMS_brickVoltage17 0;
BA_ "Confidence" SG_ 1025 BMS_brickVoltage18 0;
BA_ "Confidence" SG_ 1025 BMS_brickVoltageStatus19 0;
BA_ "Confidence" SG_ 1025 BMS_brickVoltageStatus20 0;
BA_ "Confidence" SG_ 1025 BMS_brickVoltageStatus21 0;
BA_ "Confidence" SG_ 1025 BMS_brickVoltage19 0;
BA_ "Confidence" SG_ 1025 BMS_brickVoltage20 0;
BA_ "Confidence" SG_ 1025 BMS_brickVoltage21 0;
BA_ "Confidence" SG_ 1025 BMS_brickVoltageStatus22 0;
BA_ "Confidence" SG_ 1025 BMS_brickVoltageStatus23 0;
BA_ "Confidence" SG_ 1025 BMS_brickVoltageStatus24 0;
BA_ "Confidence" SG_ 1025 BMS_brickVoltage22 0;
BA_ "Confidence" SG_ 1025 BMS_brickVoltage23 0;
BA_ "Confidence" SG_ 1025 BMS_brickVoltage24 0;
BA_ "Confidence" SG_ 1025 BMS_brickVoltageStatus25 0;
BA_ "Confidence" SG_ 1025 BMS_brickVoltageStatus26 0;
BA_ "Confidence" SG_ 1025 BMS_brickVoltageStatus27 0;
BA_ "Confidence" SG_ 1025 BMS_brickVoltage25 0;
BA_ "Confidence" SG_ 1025 BMS_brickVoltage26 0;
BA_ "Confidence" SG_ 1025 BMS_brickVoltage27 0;
BA_ "Confidence" SG_ 1025 BMS_brickVoltageStatus28 0;
BA_ "Confidence" SG_ 1025 BMS_brickVoltageStatus29 0;
BA_ "Confidence" SG_ 1025 BMS_brickVoltageStatus30 0;
BA_ "Confidence" SG_ 1025 BMS_brickVoltage28 0;
BA_ "Confidence" SG_ 1025 BMS_brickVoltage29 0;
BA_ "Confidence" SG_ 1025 BMS_brickVoltage30 0;
BA_ "Confidence" SG_ 1025 BMS_brickVoltageStatus31 0;
BA_ "Confidence" SG_ 1025 BMS_brickVoltageStatus32 0;
BA_ "Confidence" SG_ 1025 BMS_brickVoltageStatus33 0;
BA_ "Confidence" SG_ 1025 BMS_brickVoltage31 0;
BA_ "Confidence" SG_ 1025 BMS_brickVoltage32 0;
BA_ "Confidence" SG_ 1025 BMS_brickVoltage33 0;
BA_ "Confidence" SG_ 1025 BMS_brickVoltageStatus34 0;
BA_ "Confidence" SG_ 1025 BMS_brickVoltageStatus35 0;
BA_ "Confidence" SG_ 1025 BMS_brickVoltageStatus36 0;
BA_ "Confidence" SG_ 1025 BMS_brickVoltage34 0;
BA_ "Confidence" SG_ 1025 BMS_brickVoltage35 0;
BA_ "Confidence" SG_ 1025 BMS_brickVoltage36 0;
BA_ "Confidence" SG_ 1025 BMS_brickVoltageStatus37 0;
BA_ "Confidence" SG_ 1025 BMS_brickVoltageStatus38 0;
BA_ "Confidence" SG_ 1025 BMS_brickVoltageStatus39 0;
BA_ "Confidence" SG_ 1025 BMS_brickVoltage37 0;
BA_ "Confidence" SG_ 1025 BMS_brickVoltage38 0;
BA_ "Confidence" SG_ 1025 BMS_brickVoltage39 0;
BA_ "Confidence" SG_ 1025 BMS_brickVoltageStatus40 0;
BA_ "Confidence" SG_ 1025 BMS_brickVoltageStatus41 0;
BA_ "Confidence" SG_ 1025 BMS_brickVoltageStatus42 0;
BA_ "Confidence" SG_ 1025 BMS_brickVoltage40 0;
BA_ "Confidence" SG_ 1025 BMS_brickVoltage41 0;
BA_ "Confidence" SG_ 1025 BMS_brickVoltage42 0;
BA_ "Confidence" SG_ 1025 BMS_brickVoltageStatus43 0;
BA_ "Confidence" SG_ 1025 BMS_brickVoltageStatus44 0;
BA_ "Confidence" SG_ 1025 BMS_brickVoltageStatus45 0;
BA_ "Confidence" SG_ 1025 BMS_brickVoltage43 0;
BA_ "Confidence" SG_ 1025 BMS_brickVoltage44 0;
BA_ "Confidence" SG_ 1025 BMS_brickVoltage45 0;
BA_ "Confidence" SG_ 1025 BMS_brickVoltageStatus46 0;
BA_ "Confidence" SG_ 1025 BMS_brickVoltageStatus47 0;
BA_ "Confidence" SG_ 1025 BMS_brickVoltageStatus48 0;
BA_ "Confidence" SG_ 1025 BMS_brickVoltage46 0;
BA_ "Confidence" SG_ 1025 BMS_brickVoltage47 0;
BA_ "Confidence" SG_ 1025 BMS_brickVoltage48 0;
BA_ "Confidence" SG_ 1025 BMS_brickVoltageStatus49 0;
BA_ "Confidence" SG_ 1025 BMS_brickVoltageStatus50 0;
BA_ "Confidence" SG_ 1025 BMS_brickVoltageStatus51 0;
BA_ "Confidence" SG_ 1025 BMS_brickVoltage49 0;
BA_ "Confidence" SG_ 1025 BMS_brickVoltage50 0;
BA_ "Confidence" SG_ 1025 BMS_brickVoltage51 0;
BA_ "Confidence" SG_ 1025 BMS_brickVoltageStatus52 0;
BA_ "Confidence" SG_ 1025 BMS_brickVoltageStatus53 0;
BA_ "Confidence" SG_ 1025 BMS_brickVoltageStatus54 0;
BA_ "Confidence" SG_ 1025 BMS_brickVoltage52 0;
BA_ "Confidence" SG_ 1025 BMS_brickVoltage53 0;
BA_ "Confidence" SG_ 1025 BMS_brickVoltage54 0;
BA_ "Confidence" SG_ 1025 BMS_brickVoltageStatus55 0;
BA_ "Confidence" SG_ 1025 BMS_brickVoltageStatus56 0;
BA_ "Confidence" SG_ 1025 BMS_brickVoltageStatus57 0;
BA_ "Confidence" SG_ 1025 BMS_brickVoltage55 0;
BA_ "Confidence" SG_ 1025 BMS_brickVoltage56 0;
BA_ "Confidence" SG_ 1025 BMS_brickVoltage57 0;
BA_ "Confidence" SG_ 1025 BMS_brickVoltageStatus58 0;
BA_ "Confidence" SG_ 1025 BMS_brickVoltageStatus59 0;
BA_ "Confidence" SG_ 1025 BMS_brickVoltageStatus60 0;
BA_ "Confidence" SG_ 1025 BMS_brickVoltage58 0;
BA_ "Confidence" SG_ 1025 BMS_brickVoltage59 0;
BA_ "Confidence" SG_ 1025 BMS_brickVoltage60 0;
BA_ "Confidence" SG_ 1025 BMS_brickVoltageStatus61 0;
BA_ "Confidence" SG_ 1025 BMS_brickVoltageStatus62 0;
BA_ "Confidence" SG_ 1025 BMS_brickVoltageStatus63 0;
BA_ "Confidence" SG_ 1025 BMS_brickVoltage61 0;
BA_ "Confidence" SG_ 1025 BMS_brickVoltage62 0;
BA_ "Confidence" SG_ 1025 BMS_brickVoltage63 0;
BA_ "Confidence" SG_ 1025 BMS_brickVoltageStatus64 0;
BA_ "Confidence" SG_ 1025 BMS_brickVoltageStatus65 0;
BA_ "Confidence" SG_ 1025 BMS_brickVoltageStatus66 0;
BA_ "Confidence" SG_ 1025 BMS_brickVoltage64 0;
BA_ "Confidence" SG_ 1025 BMS_brickVoltage65 0;
BA_ "Confidence" SG_ 1025 BMS_brickVoltage66 0;
BA_ "Confidence" SG_ 1025 BMS_brickVoltageStatus67 0;
BA_ "Confidence" SG_ 1025 BMS_brickVoltageStatus68 0;
BA_ "Confidence" SG_ 1025 BMS_brickVoltageStatus69 0;
BA_ "Confidence" SG_ 1025 BMS_brickVoltage67 0;
BA_ "Confidence" SG_ 1025 BMS_brickVoltage68 0;
BA_ "Confidence" SG_ 1025 BMS_brickVoltage69 0;
BA_ "Confidence" SG_ 1025 BMS_brickVoltageStatus70 0;
BA_ "Confidence" SG_ 1025 BMS_brickVoltageStatus71 0;
BA_ "Confidence" SG_ 1025 BMS_brickVoltageStatus72 0;
BA_ "Confidence" SG_ 1025 BMS_brickVoltage70 0;
BA_ "Confidence" SG_ 1025 BMS_brickVoltage71 0;
BA_ "Confidence" SG_ 1025 BMS_brickVoltage72 0;
BA_ "Confidence" SG_ 1025 BMS_brickVoltageStatus73 0;
BA_ "Confidence" SG_ 1025 BMS_brickVoltageStatus74 0;
BA_ "Confidence" SG_ 1025 BMS_brickVoltageStatus75 0;
BA_ "Confidence" SG_ 1025 BMS_brickVoltage73 0;
BA_ "Confidence" SG_ 1025 BMS_brickVoltage74 0;
BA_ "Confidence" SG_ 1025 BMS_brickVoltage75 0;
BA_ "Confidence" SG_ 1025 BMS_brickVoltageStatus76 0;
BA_ "Confidence" SG_ 1025 BMS_brickVoltageStatus77 0;
BA_ "Confidence" SG_ 1025 BMS_brickVoltageStatus78 0;
BA_ "Confidence" SG_ 1025 BMS_brickVoltage76 0;
BA_ "Confidence" SG_ 1025 BMS_brickVoltage77 0;
BA_ "Confidence" SG_ 1025 BMS_brickVoltage78 0;
BA_ "Confidence" SG_ 1025 BMS_brickVoltageStatus79 0;
BA_ "Confidence" SG_ 1025 BMS_brickVoltageStatus80 0;
BA_ "Confidence" SG_ 1025 BMS_brickVoltageStatus81 0;
BA_ "Confidence" SG_ 1025 BMS_brickVoltage79 0;
BA_ "Confidence" SG_ 1025 BMS_brickVoltage80 0;
BA_ "Confidence" SG_ 1025 BMS_brickVoltage81 0;
BA_ "Confidence" SG_ 1025 BMS_brickVoltageStatus82 0;
BA_ "Confidence" SG_ 1025 BMS_brickVoltageStatus83 0;
BA_ "Confidence" SG_ 1025 BMS_brickVoltageStatus84 0;
BA_ "Confidence" SG_ 1025 BMS_brickVoltage82 0;
BA_ "Confidence" SG_ 1025 BMS_brickVoltage83 0;
BA_ "Confidence" SG_ 1025 BMS_brickVoltage84 0;
BA_ "Confidence" SG_ 1025 BMS_brickVoltageStatus85 0;
BA_ "Confidence" SG_ 1025 BMS_brickVoltageStatus86 0;
BA_ "Confidence" SG_ 1025 BMS_brickVoltageStatus87 0;
BA_ "Confidence" SG_ 1025 BMS_brickVoltage85 0;
BA_ "Confidence" SG_ 1025 BMS_brickVoltage86 0;
BA_ "Confidence" SG_ 1025 BMS_brickVoltage87 0;
BA_ "Confidence" SG_ 1025 BMS_brickVoltageStatus88 0;
BA_ "Confidence" SG_ 1025 BMS_brickVoltageStatus89 0;
BA_ "Confidence" SG_ 1025 BMS_brickVoltageStatus90 0;
BA_ "Confidence" SG_ 1025 BMS_brickVoltage88 0;
BA_ "Confidence" SG_ 1025 BMS_brickVoltage89 0;
BA_ "Confidence" SG_ 1025 BMS_brickVoltage90 0;
BA_ "Confidence" SG_ 1025 BMS_brickVoltageStatus91 0;
BA_ "Confidence" SG_ 1025 BMS_brickVoltageStatus92 0;
BA_ "Confidence" SG_ 1025 BMS_brickVoltageStatus93 0;
BA_ "Confidence" SG_ 1025 BMS_brickVoltage91 0;
BA_ "Confidence" SG_ 1025 BMS_brickVoltage92 0;
BA_ "Confidence" SG_ 1025 BMS_brickVoltage93 0;
BA_ "Confidence" SG_ 1025 BMS_brickVoltageStatus94 0;
BA_ "Confidence" SG_ 1025 BMS_brickVoltageStatus95 0;
BA_ "Confidence" SG_ 1025 BMS_brickVoltageStatus96 0;
BA_ "Confidence" SG_ 1025 BMS_brickVoltage94 0;
BA_ "Confidence" SG_ 1025 BMS_brickVoltage95 0;
BA_ "Confidence" SG_ 1025 BMS_brickVoltage96 0;
BA_ "Confidence" SG_ 1025 BMS_brickVoltageStatus97 0;
BA_ "Confidence" SG_ 1025 BMS_brickVoltageStatus98 0;
BA_ "Confidence" SG_ 1025 BMS_brickVoltageStatus99 0;
BA_ "Confidence" SG_ 1025 BMS_brickVoltage97 0;
BA_ "Confidence" SG_ 1025 BMS_brickVoltage98 0;
BA_ "Confidence" SG_ 1025 BMS_brickVoltage99 0;
BA_ "Confidence" SG_ 1025 BMS_brickVoltageStatus100 0;
BA_ "Confidence" SG_ 1025 BMS_brickVoltageStatus101 0;
BA_ "Confidence" SG_ 1025 BMS_brickVoltageStatus102 0;
BA_ "Confidence" SG_ 1025 BMS_brickVoltage100 0;
BA_ "Confidence" SG_ 1025 BMS_brickVoltage101 0;
BA_ "Confidence" SG_ 1025 BMS_brickVoltage102 0;
BA_ "Confidence" SG_ 1025 BMS_brickVoltageStatus103 0;
BA_ "Confidence" SG_ 1025 BMS_brickVoltageStatus104 0;
BA_ "Confidence" SG_ 1025 BMS_brickVoltageStatus105 0;
BA_ "Confidence" SG_ 1025 BMS_brickVoltage103 0;
BA_ "Confidence" SG_ 1025 BMS_brickVoltage104 0;
BA_ "Confidence" SG_ 1025 BMS_brickVoltage105 0;
BA_ "Confidence" SG_ 1025 BMS_brickVoltageStatus106 0;
BA_ "Confidence" SG_ 1025 BMS_brickVoltageStatus107 0;
BA_ "Confidence" SG_ 1025 BMS_brickVoltageStatus108 0;
BA_ "Confidence" SG_ 1025 BMS_brickVoltage106 0;
BA_ "Confidence" SG_ 1025 BMS_brickVoltage107 0;
BA_ "Confidence" SG_ 1025 BMS_brickVoltage108 0;
BA_ "Confidence" SG_ 1138 BMS_acChargePowerSample 0;
BA_ "GenSigSNA" SG_ 1138 BMS_acChargePowerSample "255";
BA_ "Confidence" SG_ 1138 BMS_voltageRegCurrentTarget 0;
BA_ "Confidence" SG_ 1138 BMS_vehicleChargeDcCurrentLimit 0;
BA_ "Confidence" SG_ 1138 BMS_userChargeCurrentLimitMode 0;
BA_ "Confidence" SG_ 1138 BMS_chargeCurrentLimitMode 0;
BA_ "Confidence" SG_ 1138 BMS_timeToFinishHeatForCharge 0;
BA_ "GenSigSNA" SG_ 1138 BMS_timeToFinishHeatForCharge "127";
BA_ "Confidence" SG_ 1138 BMS_timeToTripPlanChargingTarget 0;
BA_ "GenSigSNA" SG_ 1138 BMS_timeToTripPlanChargingTarget "2047";
BA_ "Confidence" SG_ 1138 BMS_useChargeTimeEstimate 0;
BA_ "Confidence" SG_ 562 BMS_fcContactorRequest 1;
BA_ "Confidence" SG_ 562 BMS_packContactorRequest 1;
BA_ "Confidence" SG_ 562 BMS_gpoHasCompleted 1;
BA_ "Confidence" SG_ 562 BMS_ensShouldBeActiveForDrive 1;
BA_ "Confidence" SG_ 562 BMS_pcsPwmDisable 1;
BA_ "Confidence" SG_ 562 BMS_fcLinkOkToEnergizeRequest 1;
BA_ "Confidence" SG_ 562 BMS_internalHvilSenseV 1;
BA_ "Confidence" SG_ 562 BMS_hvilCoverVSense 1;
BA_ "Confidence" SG_ 722 BMS_minBusVoltage 0;
BA_ "Confidence" SG_ 722 BMS_maxBusVoltage 0;
BA_ "Confidence" SG_ 722 BMS_maxChargeCurrent 0;
BA_ "Confidence" SG_ 722 BMS_maxDischargeCurrent 0;
BA_ "Confidence" SG_ 690 BMS_energyStatusMultiplexer 1;
BA_ "Confidence" SG_ 690 BMS_nominalFullPackEnergy 0;
BA_ "GenSigSNA" SG_ 690 BMS_nominalFullPackEnergy "65535";
BA_ "Confidence" SG_ 690 BMS_nominalEnergyRemaining 0;
BA_ "GenSigSNA" SG_ 690 BMS_nominalEnergyRemaining "65535";
BA_ "Confidence" SG_ 690 BMS_idealEnergyRemaining 0;
BA_ "GenSigSNA" SG_ 690 BMS_idealEnergyRemaining "65535";
BA_ "Confidence" SG_ 690 BMS_fullChargeComplete 0;
BA_ "Confidence" SG_ 690 BMS_energyBuffer 0;
BA_ "GenSigSNA" SG_ 690 BMS_energyBuffer "65535";
BA_ "Confidence" SG_ 690 BMS_expectedEnergyRemaining 0;
BA_ "GenSigSNA" SG_ 690 BMS_expectedEnergyRemaining "65535";
BA_ "Confidence" SG_ 690 BMS_energyToChargeComplete 0;
BA_ "GenSigSNA" SG_ 690 BMS_energyToChargeComplete "65535";
BA_ "Confidence" SG_ 690 BMS_energyRemainingDisplay 0;
BA_ "GenSigSNA" SG_ 690 BMS_energyRemainingDisplay "65535";
BA_ "Confidence" SG_ 690 BMS_energyRemainingTDisplay 0;
BA_ "GenSigSNA" SG_ 690 BMS_energyRemainingTDisplay "65535";
BA_ "Confidence" SG_ 690 BMS_energyDisplayErrorBlendRate 0;
BA_ "Confidence" SG_ 690 BMS_userFacingSoe 0;
BA_ "GenSigSNA" SG_ 690 BMS_userFacingSoe "2047";
BA_ "Confidence" SG_ 306 BMS_dcLinkVoltage 0;
BA_ "Confidence" SG_ 306 BMS_packCurrent 0;
BA_ "GenSigSNA" SG_ 306 BMS_packCurrent "32768";
BA_ "Confidence" SG_ 306 BMS_currentUnfiltered 0;
BA_ "GenSigSNA" SG_ 306 BMS_currentUnfiltered "32768";
BA_ "Confidence" SG_ 768 BMS_infoIndex 1;
BA_ "Confidence" SG_ 768 BMS_buildType 0;
BA_ "Confidence" SG_ 768 BMS_buildConfigId 0;
BA_ "Confidence" SG_ 768 BMS_hardwareId 0;
BA_ "Confidence" SG_ 768 BMS_componentId 0;
BA_ "Confidence" SG_ 768 BMS_pcbaId 0;
BA_ "Confidence" SG_ 768 BMS_assemblyId 0;
BA_ "Confidence" SG_ 768 BMS_usageId 0;
BA_ "Confidence" SG_ 768 BMS_subUsageId 0;
BA_ "Confidence" SG_ 768 BMS_platformType 0;
BA_ "Confidence" SG_ 768 BMS_appCrc 0;
BA_ "Confidence" SG_ 768 BMS_appGitHash 0;
BA_ "Confidence" SG_ 768 BMS_bootGitHash 0;
BA_ "Confidence" SG_ 768 BMS_bootUdsProtoVersion 0;
BA_ "Confidence" SG_ 768 BMS_bootCrc 0;
BA_ "Confidence" SG_ 978 BMS_kwhDischargeTotal 0;
BA_ "Confidence" SG_ 978 BMS_kwhChargeTotal 0;
BA_ "Confidence" SG_ 1010 BMS_kwhCounter_Id 1;
BA_ "Confidence" SG_ 1010 BMS_acChargerKwhTotal 0;
BA_ "Confidence" SG_ 1010 BMS_dcChargerKwhTotal 0;
BA_ "Confidence" SG_ 1010 BMS_kwhRegenChargeTotal 0;
BA_ "Confidence" SG_ 1010 BMS_kwhDriveDischargeTotal 0;
BA_ "Confidence" SG_ 1010 BMS_kwhDischargeTotalModule1 0;
BA_ "Confidence" SG_ 1010 BMS_kwhChargeTotalModule1 0;
BA_ "Confidence" SG_ 1010 BMS_kwhAcChargeTotalModule1 0;
BA_ "Confidence" SG_ 1010 BMS_kwhDcChargeTotalModule1 0;
BA_ "Confidence" SG_ 1010 BMS_kwhDischargeTotalModule2 0;
BA_ "Confidence" SG_ 1010 BMS_kwhChargeTotalModule2 0;
BA_ "Confidence" SG_ 1010 BMS_kwhAcChargeTotalModule2 0;
BA_ "Confidence" SG_ 1010 BMS_kwhDcChargeTotalModule2 0;
BA_ "Confidence" SG_ 1010 BMS_kwhDischargeTotalModule3 0;
BA_ "Confidence" SG_ 1010 BMS_kwhChargeTotalModule3 0;
BA_ "Confidence" SG_ 1010 BMS_kwhAcChargeTotalModule3 0;
BA_ "Confidence" SG_ 1010 BMS_kwhDcChargeTotalModule3 0;
BA_ "Confidence" SG_ 1010 BMS_kwhDischargeTotalModule4 0;
BA_ "Confidence" SG_ 1010 BMS_kwhChargeTotalModule4 0;
BA_ "Confidence" SG_ 1010 BMS_kwhAcChargeTotalModule4 0;
BA_ "Confidence" SG_ 1010 BMS_kwhDcChargeTotalModule4 0;
BA_ "Confidence" SG_ 884 BMS_log1MuxId 1;
BA_ "Confidence" SG_ 884 BMS_powerTransferStatus 0;
BA_ "Confidence" SG_ 884 BMS_extDcPrechargeVoltageLimit 0;
BA_ "Confidence" SG_ 884 BMS_dcChargeCurrentRequest 0;
BA_ "Confidence" SG_ 884 BMS_dcChargeCurrentLimit 0;
BA_ "Confidence" SG_ 884 BMS_dcDischargeEnabled 0;
BA_ "Confidence" SG_ 884 BMS_rippleChargeRetryCount 0;
BA_ "Confidence" SG_ 884 BMS_dcChargeVoltageLimit 0;
BA_ "Confidence" SG_ 884 BMS_dcChargePowerLimit 0;
BA_ "Confidence" SG_ 884 BMS_acRealPowerRequest 0;
BA_ "Confidence" SG_ 884 BMS_maxExtIsoFcLinkV 0;
BA_ "Confidence" SG_ 884 BMS_minModeledPackTemp 1;
BA_ "Confidence" SG_ 884 BMS_maxModeledPackTemp 1;
BA_ "Confidence" SG_ 884 BMS_energyMaxPredictedBrickTemp 0;
BA_ "Confidence" SG_ 884 BMS_energyTempGradientAtMaxTemp 0;
BA_ "Confidence" SG_ 884 BMS_energyWalkMaxSoc 0;
BA_ "Confidence" SG_ 884 BMS_energyWalkMinSoc 0;
BA_ "Confidence" SG_ 884 BMS_chargeEnergyWalkState 0;
BA_ "Confidence" SG_ 884 BMS_packVoltage 0;
BA_ "Confidence" SG_ 884 BMS_energyWalkMaxPackCurrent 0;
BA_ "GenSigSNA" SG_ 884 BMS_energyWalkMaxPackCurrent "32768";
BA_ "Confidence" SG_ 884 BMS_energyWalkMaxVehiclePower 0;
BA_ "Confidence" SG_ 884 BMS_battTempPct 0;
BA_ "GenSigSNA" SG_ 884 BMS_battTempPct "255";
BA_ "Confidence" SG_ 884 BMS_powerTransferDisableType 0;
BA_ "Confidence" SG_ 884 BMS_powerTransferDisableReason 0;
BA_ "Confidence" SG_ 884 BMS_powerTransferWaitCondition 0;
BA_ "Confidence" SG_ 884 BMS_dischargeRetryCount 0;
BA_ "Confidence" SG_ 884 BMS_acChargeDesired 0;
BA_ "Confidence" SG_ 884 BMS_tetheringDesired 0;
BA_ "Confidence" SG_ 884 BMS_gridFormDesired 0;
BA_ "Confidence" SG_ 884 BMS_gridFollowDesired 0;
BA_ "Confidence" SG_ 946 BMS_log2MuxId 1;
BA_ "Confidence" SG_ 946 BMS_maxChargeRestartNeededByVolt 0;
BA_ "SystemSignalLongSymbol" SG_ 946 BMS_maxChargeRestartNeededByVolt "BMS_maxChargeRestartNeededByVoltage";
BA_ "Confidence" SG_ 946 BMS_cacAvg 0;
BA_ "Confidence" SG_ 946 BMS_maxChargeNearComplete 0;
BA_ "Confidence" SG_ 946 BMS_cacMin 0;
BA_ "Confidence" SG_ 946 BMS_cacMinBrickId 0;
BA_ "Confidence" SG_ 946 BMS_cacMax 0;
BA_ "Confidence" SG_ 946 BMS_cacMaxBrickId 0;
BA_ "Confidence" SG_ 946 BMS_acRippleConfigNvramValid 0;
BA_ "Confidence" SG_ 946 BMS_hvChain_useLeakyBucket 0;
BA_ "Confidence" SG_ 946 BMS_hvChain_iLimit 0;
BA_ "GenSigSNA" SG_ 946 BMS_hvChain_iLimit "16383";
BA_ "Confidence" SG_ 946 BMS_hvChain_limitingState 0;
BA_ "GenSigSNA" SG_ 946 BMS_hvChain_limitingState "511";
BA_ "Confidence" SG_ 946 BMS_hvChain_limitingStateTempera 0;
BA_ "GenSigSNA" SG_ 946 BMS_hvChain_limitingStateTempera "4096";
BA_ "SystemSignalLongSymbol" SG_ 946 BMS_hvChain_limitingStateTempera "BMS_hvChain_limitingStateTemperature";
BA_ "Confidence" SG_ 946 BMS_acRippleIsSupported 0;
BA_ "Confidence" SG_ 946 BMS_acRippleStartTemperatureMax 0;
BA_ "Confidence" SG_ 946 BMS_acRippleStartTemperatureMin 0;
BA_ "Confidence" SG_ 946 BMS_fcLinkTestDecayTime 0;
BA_ "GenSigSNA" SG_ 946 BMS_fcLinkTestDecayTime "1023";
BA_ "Confidence" SG_ 946 BMS_fcLinkTestTimeSinceLastRun 0;
BA_ "Confidence" SG_ 946 BMS_pcsPrechargeRequest 0;
BA_ "Confidence" SG_ 946 BMS_pcsPrechargeTargetVoltage 0;
BA_ "Confidence" SG_ 946 BMS_recentOvUvAlert 0;
BA_ "Confidence" SG_ 946 BMS_recentIsoAlert 0;
BA_ "Confidence" SG_ 946 BMS_recentBmbMiaAlert 0;
BA_ "Confidence" SG_ 946 BMS_cacBlendingConfigNvramValid 0;
BA_ "Confidence" SG_ 946 BMS_cacBlendingEnabled 0;
BA_ "Confidence" SG_ 946 BMS_cacBlendPercentPerCycle 0;
BA_ "Confidence" SG_ 946 BMS_energyVariableChgRequested 0;
BA_ "Confidence" SG_ 946 BMS_packRestTime 0;
BA_ "Confidence" SG_ 946 BMS_idealEnergyFloor 0;
BA_ "GenSigSNA" SG_ 946 BMS_idealEnergyFloor "1023";
BA_ "Confidence" SG_ 946 BMS_thmGradientSlopeCondition 0;
BA_ "Confidence" SG_ 946 BMS_recentSlopeConditon 0;
BA_ "Confidence" SG_ 946 BMS_dynamicEnergyBuffer 0;
BA_ "GenSigSNA" SG_ 946 BMS_dynamicEnergyBuffer "1023";
BA_ "Confidence" SG_ 946 BMS_temperatureCondition 0;
BA_ "Confidence" SG_ 946 BMS_thmGradientSlope 0;
BA_ "Confidence" SG_ 946 BMS_thmGradient 0;
BA_ "Confidence" SG_ 946 BMS_epochTimeEstimate 1;
BA_ "Confidence" SG_ 946 BMS_histogramStartTimeIrrational 1;
BA_ "Confidence" SG_ 946 BMS_histogramDischargeThroughput 1;
BA_ "SystemSignalLongSymbol" SG_ 946 BMS_histogramDischargeThroughput "BMS_histogramDischargeThroughputIrrational";
BA_ "Confidence" SG_ 946 BMS_histogramChargeThroughputIrr 1;
BA_ "SystemSignalLongSymbol" SG_ 946 BMS_histogramChargeThroughputIrr "BMS_histogramChargeThroughputIrrational";
BA_ "Confidence" SG_ 946 BMS_histogramTotalTimeIrrational 1;
BA_ "Confidence" SG_ 946 BMS_histogramStorageDataIsLow 1;
BA_ "Confidence" SG_ 946 BMS_tempVsSocTotalChgEnergy 0;
BA_ "Confidence" SG_ 946 BMS_powerVsVoltageTotalChgEnergy 0;
BA_ "Confidence" SG_ 946 BMS_lifeModelOutputsAreTrustwort 0;
BA_ "SystemSignalLongSymbol" SG_ 946 BMS_lifeModelOutputsAreTrustwort "BMS_lifeModelOutputsAreTrustworthy";
BA_ "Confidence" SG_ 946 BMS_dSocNormalizedMin 0;
BA_ "GenSigSNA" SG_ 946 BMS_dSocNormalizedMin "4095";
BA_ "Confidence" SG_ 946 BMS_dSocNormalizedFiltMin 0;
BA_ "GenSigSNA" SG_ 946 BMS_dSocNormalizedFiltMin "4095";
BA_ "Confidence" SG_ 946 BMS_dSocMinAlpha 0;
BA_ "GenSigSNA" SG_ 946 BMS_dSocMinAlpha "4095";
BA_ "Confidence" SG_ 946 BMS_dSocMaxLowAlphaCounter 0;
BA_ "Confidence" SG_ 946 BMS_dSocMinAlphaBrickID 0;
BA_ "Confidence" SG_ 946 BMS_dSocCacMargin 0;
BA_ "GenSigSNA" SG_ 946 BMS_dSocCacMargin "511";
BA_ "Confidence" SG_ 946 BMS_lifeModelNoCurrentStorageCap 0;
BA_ "GenSigSNA" SG_ 946 BMS_lifeModelNoCurrentStorageCap "511";
BA_ "SystemSignalLongSymbol" SG_ 946 BMS_lifeModelNoCurrentStorageCap "BMS_lifeModelNoCurrentStorageCapacityLoss";
BA_ "Confidence" SG_ 946 BMS_lifeModelShortDcr 0;
BA_ "GenSigSNA" SG_ 946 BMS_lifeModelShortDcr "255";
BA_ "Confidence" SG_ 946 BMS_lifeModelLongDcr 0;
BA_ "GenSigSNA" SG_ 946 BMS_lifeModelLongDcr "4096";
BA_ "Confidence" SG_ 946 BMS_lifeModelStorageCapacityLoss 0;
BA_ "GenSigSNA" SG_ 946 BMS_lifeModelStorageCapacityLoss "511";
BA_ "Confidence" SG_ 946 BMS_lifeModelThroughputCapacityL 0;
BA_ "GenSigSNA" SG_ 946 BMS_lifeModelThroughputCapacityL "511";
BA_ "SystemSignalLongSymbol" SG_ 946 BMS_lifeModelThroughputCapacityL "BMS_lifeModelThroughputCapacityLoss";
BA_ "Confidence" SG_ 946 BMS_passiveCoolCellTargetT 0;
BA_ "Confidence" SG_ 946 BMS_lifeModelAvgTempSeverity 0;
BA_ "GenSigSNA" SG_ 946 BMS_lifeModelAvgTempSeverity "31";
BA_ "Confidence" SG_ 946 BMS_lifeModelDepthOfDischargeSev 0;
BA_ "GenSigSNA" SG_ 946 BMS_lifeModelDepthOfDischargeSev "255";
BA_ "SystemSignalLongSymbol" SG_ 946 BMS_lifeModelDepthOfDischargeSev "BMS_lifeModelDepthOfDischargeSeverity";
BA_ "Confidence" SG_ 946 BMS_lifeModelHistogramCapacityLo 0;
BA_ "GenSigSNA" SG_ 946 BMS_lifeModelHistogramCapacityLo "511";
BA_ "SystemSignalLongSymbol" SG_ 946 BMS_lifeModelHistogramCapacityLo "BMS_lifeModelHistogramCapacityLoss";
BA_ "Confidence" SG_ 946 BMS_lifeModelHistogramBrickCapac 0;
BA_ "GenSigSNA" SG_ 946 BMS_lifeModelHistogramBrickCapac "8191";
BA_ "SystemSignalLongSymbol" SG_ 946 BMS_lifeModelHistogramBrickCapac "BMS_lifeModelHistogramBrickCapacity";
BA_ "Confidence" SG_ 946 BMS_lifeModelDcrGrowthPercent 0;
BA_ "GenSigSNA" SG_ 946 BMS_lifeModelDcrGrowthPercent "8192";
BA_ "Confidence" SG_ 946 BMS_nominalFullPackEnergyRaw 0;
BA_ "GenSigSNA" SG_ 946 BMS_nominalFullPackEnergyRaw "65535";
BA_ "Confidence" SG_ 946 BMS_nominalEnergyRemainingBuffer 0;
BA_ "GenSigSNA" SG_ 946 BMS_nominalEnergyRemainingBuffer "65535";
BA_ "SystemSignalLongSymbol" SG_ 946 BMS_nominalEnergyRemainingBuffer "BMS_nominalEnergyRemainingBuffered";
BA_ "Confidence" SG_ 946 BMS_idealEnergyRemainingBuffered 0;
BA_ "GenSigSNA" SG_ 946 BMS_idealEnergyRemainingBuffered "65535";
BA_ "Confidence" SG_ 946 BMS_largestSynchronizedCacErrorP 0;
BA_ "GenSigSNA" SG_ 946 BMS_largestSynchronizedCacErrorP "255";
BA_ "SystemSignalLongSymbol" SG_ 946 BMS_largestSynchronizedCacErrorP "BMS_largestSynchronizedCacErrorPct";
BA_ "Confidence" SG_ 946 BMS_lifeModelSpreadMinOffset 1;
BA_ "Confidence" SG_ 946 BMS_lifeModelSpreadMaxOffset 1;
BA_ "Confidence" SG_ 946 BMS_largestCacSpreadErrorLower 0;
BA_ "GenSigSNA" SG_ 946 BMS_largestCacSpreadErrorLower "4095";
BA_ "Confidence" SG_ 946 BMS_lifeModelAverageCac 0;
BA_ "GenSigSNA" SG_ 946 BMS_lifeModelAverageCac "4095";
BA_ "Confidence" SG_ 946 BMS_lifeModelCacBrick1 0;
BA_ "GenSigSNA" SG_ 946 BMS_lifeModelCacBrick1 "4095";
BA_ "Confidence" SG_ 946 BMS_lifeModelAverageOffset 0;
BA_ "GenSigSNA" SG_ 946 BMS_lifeModelAverageOffset "512";
BA_ "Confidence" SG_ 946 BMS_percentCacUpdatesInTimeWindo 0;
BA_ "SystemSignalLongSymbol" SG_ 946 BMS_percentCacUpdatesInTimeWindo "BMS_percentCacUpdatesInTimeWindow";
BA_ "Confidence" SG_ 946 BMS_lifeModelMaxCacBrickId 0;
BA_ "GenSigSNA" SG_ 946 BMS_lifeModelMaxCacBrickId "255";
BA_ "Confidence" SG_ 946 BMS_lifeModelMaxCac 0;
BA_ "GenSigSNA" SG_ 946 BMS_lifeModelMaxCac "4095";
BA_ "Confidence" SG_ 946 BMS_lifeModelMinCacBrickId 0;
BA_ "GenSigSNA" SG_ 946 BMS_lifeModelMinCacBrickId "255";
BA_ "Confidence" SG_ 946 BMS_lifeModelMinCac 0;
BA_ "GenSigSNA" SG_ 946 BMS_lifeModelMinCac "4095";
BA_ "Confidence" SG_ 946 BMS_restingPointCacAvg 0;
BA_ "GenSigSNA" SG_ 946 BMS_restingPointCacAvg "4095";
BA_ "Confidence" SG_ 946 BMS_cacEstimationSource 0;
BA_ "Confidence" SG_ 946 BMS_packCalibrationBirthDateBinn 1;
BA_ "SystemSignalLongSymbol" SG_ 946 BMS_packCalibrationBirthDateBinn "BMS_packCalibrationBirthDateBinned";
BA_ "Confidence" SG_ 946 BMS_synchronizedCacMaxRaw 0;
BA_ "GenSigSNA" SG_ 946 BMS_synchronizedCacMaxRaw "4095";
BA_ "Confidence" SG_ 946 BMS_synchronizedCacMinRaw 0;
BA_ "GenSigSNA" SG_ 946 BMS_synchronizedCacMinRaw "4095";
BA_ "Confidence" SG_ 946 BMS_largestSyncCacErrorStartSoc 0;
BA_ "Confidence" SG_ 946 BMS_largestSyncCacErrorEndSoc 0;
BA_ "Confidence" SG_ 946 BMS_runtimeSocConfigNvramValid 0;
BA_ "Confidence" SG_ 946 BMS_runtimeSocCorrectionsEnabled 0;
BA_ "Confidence" SG_ 946 BMS_rubberBandingEnabled 0;
BA_ "Confidence" SG_ 946 BMS_rubberBandingConfigNvramVali 0;
BA_ "SystemSignalLongSymbol" SG_ 946 BMS_rubberBandingConfigNvramVali "BMS_rubberBandingConfigNvramValid";
BA_ "Confidence" SG_ 946 BMS_runtimeSocMinTempForModel 0;
BA_ "Confidence" SG_ 946 BMS_energyBufferConfigNvramValid 0;
BA_ "Confidence" SG_ 946 BMS_thermalEvent1pDetectConfigDi 0;
BA_ "SystemSignalLongSymbol" SG_ 946 BMS_thermalEvent1pDetectConfigDi "BMS_thermalEvent1pDetectConfigDisabled";
BA_ "Confidence" SG_ 946 BMS_sohEnergy 0;
BA_ "GenSigSNA" SG_ 946 BMS_sohEnergy "2047";
BA_ "Confidence" SG_ 946 BMS_fullCapacitySohEnergy 0;
BA_ "GenSigSNA" SG_ 946 BMS_fullCapacitySohEnergy "2047";
BA_ "Confidence" SG_ 946 BMS_calibratedCapacitySohEnergy 0;
BA_ "GenSigSNA" SG_ 946 BMS_calibratedCapacitySohEnergy "2047";
BA_ "Confidence" SG_ 946 BMS_estimatedCapacitySohEnergy 0;
BA_ "GenSigSNA" SG_ 946 BMS_estimatedCapacitySohEnergy "2047";
BA_ "Confidence" SG_ 946 BMS_prevUserFacingSohEnergy 0;
BA_ "GenSigSNA" SG_ 946 BMS_prevUserFacingSohEnergy "2047";
BA_ "Confidence" SG_ 946 BMS_stateOfHealthMinCac 0;
BA_ "GenSigSNA" SG_ 946 BMS_stateOfHealthMinCac "8191";
BA_ "Confidence" SG_ 946 BMS_lifeModelStorageLossPackAge 0;
BA_ "GenSigSNA" SG_ 946 BMS_lifeModelStorageLossPackAge "16383";
BA_ "Confidence" SG_ 946 BMS_lifeModelThroughputDcrCycleC 0;
BA_ "GenSigSNA" SG_ 946 BMS_lifeModelThroughputDcrCycleC "4095";
BA_ "SystemSignalLongSymbol" SG_ 946 BMS_lifeModelThroughputDcrCycleC "BMS_lifeModelThroughputDcrCycleCount";
BA_ "Confidence" SG_ 946 BMS_stateOfHealthMinCacLowerBoun 0;
BA_ "GenSigSNA" SG_ 946 BMS_stateOfHealthMinCacLowerBoun "8191";
BA_ "SystemSignalLongSymbol" SG_ 946 BMS_stateOfHealthMinCacLowerBoun "BMS_stateOfHealthMinCacLowerBound";
BA_ "Confidence" SG_ 946 BMS_energyWalkCounter 0;
BA_ "Confidence" SG_ 946 BMS_energyWalkTimeoutCounter 0;
BA_ "Confidence" SG_ 946 BMS_dynamicCcvEnabled 0;
BA_ "Confidence" SG_ 946 BMS_chargeTargetLookupSoc 0;
BA_ "Confidence" SG_ 946 BMS_stateOfHealth 0;
BA_ "GenSigSNA" SG_ 946 BMS_stateOfHealth "1023";
BA_ "Confidence" SG_ 946 BMS_avgShuntAsicCurrentOffset 0;
BA_ "GenSigSNA" SG_ 946 BMS_avgShuntAsicCurrentOffset "16384";
BA_ "Confidence" SG_ 946 BMS_cellAttributesGeneralAttribu 0;
BA_ "GenSigSNA" SG_ 946 BMS_cellAttributesGeneralAttribu "0";
BA_ "SystemSignalLongSymbol" SG_ 946 BMS_cellAttributesGeneralAttribu "BMS_cellAttributesGeneralAttributes";
BA_ "Confidence" SG_ 946 BMS_cellAttributesPackManufactur 0;
BA_ "GenSigSNA" SG_ 946 BMS_cellAttributesPackManufactur "0";
BA_ "SystemSignalLongSymbol" SG_ 946 BMS_cellAttributesPackManufactur "BMS_cellAttributesPackManufacturingLocation";
BA_ "Confidence" SG_ 946 BMS_cellAttributesRemanufactured 0;
BA_ "SystemSignalLongSymbol" SG_ 946 BMS_cellAttributesRemanufactured "BMS_cellAttributesRemanufacturedPack";
BA_ "Confidence" SG_ 946 BMS_cellAttributesConfigNvramVal 0;
BA_ "SystemSignalLongSymbol" SG_ 946 BMS_cellAttributesConfigNvramVal "BMS_cellAttributesConfigNvramValid";
BA_ "Confidence" SG_ 946 BMS_cellAttributesCellType 0;
BA_ "GenSigSNA" SG_ 946 BMS_cellAttributesCellType "0";
BA_ "Confidence" SG_ 946 BMS_cellAttributesAutocloseAndSc 0;
BA_ "SystemSignalLongSymbol" SG_ 946 BMS_cellAttributesAutocloseAndSc "BMS_cellAttributesAutocloseAndScrapPackOnFieldReturn";
BA_ "Confidence" SG_ 946 BMS_cellAttributesShipPackForFai 0;
BA_ "SystemSignalLongSymbol" SG_ 946 BMS_cellAttributesShipPackForFai "BMS_cellAttributesShipPackForFailureAnalysis";
BA_ "Confidence" SG_ 946 BMS_lifeModelThroughputCycleCoun 0;
BA_ "GenSigSNA" SG_ 946 BMS_lifeModelThroughputCycleCoun "4095";
BA_ "SystemSignalLongSymbol" SG_ 946 BMS_lifeModelThroughputCycleCoun "BMS_lifeModelThroughputCycleCount";
BA_ "Confidence" SG_ 946 BMS_limpChargeCurrentLimit 0;
BA_ "GenSigSNA" SG_ 946 BMS_limpChargeCurrentLimit "1023";
BA_ "Confidence" SG_ 946 BMS_energyRemainingDisplayError 0;
BA_ "Confidence" SG_ 946 BMS_energyRemainingTDisplayError 0;
BA_ "Confidence" SG_ 946 BMS_numOfThermistors 0;
BA_ "Confidence" SG_ 946 BMS_numOfBricks 0;
BA_ "Confidence" SG_ 946 BMS_cellChargeDcCurrentLimit 0;
BA_ "Confidence" SG_ 946 BMS_socByDeltaVEnabled 0;
BA_ "Confidence" SG_ 946 BMS_socByDvMaxSocLimit 0;
BA_ "Confidence" SG_ 946 BMS_socByDvVoltageChangeOverAh 0;
BA_ "Confidence" SG_ 946 BMS_socByDvMaxSocByAhCorrected 0;
BA_ "Confidence" SG_ 946 BMS_socByDvMaxBrickVoltage 0;
BA_ "Confidence" SG_ 946 BMS_socByDvMaxBrickId 0;
BA_ "Confidence" SG_ 946 BMS_socByDvMaxSocByAhRaw 0;
BA_ "Confidence" SG_ 946 BMS_voltageInstabilityExcessNois 0;
BA_ "SystemSignalLongSymbol" SG_ 946 BMS_voltageInstabilityExcessNois "BMS_voltageInstabilityExcessNoiseLog";
BA_ "Confidence" SG_ 946 BMS_maxModelThermistorTempDelta 0;
BA_ "GenSigSNA" SG_ 946 BMS_maxModelThermistorTempDelta "512";
BA_ "Confidence" SG_ 946 BMS_activeCoolCellTargetT 0;
BA_ "Confidence" SG_ 946 BMS_cellTempTargetMode 0;
BA_ "Confidence" SG_ 946 BMS_minPackTempForChargeToStart 0;
BA_ "Confidence" SG_ 914 BMS_packConfigMultiplexer 1;
BA_ "Confidence" SG_ 914 BMS_reservedConfig_0 0;
BA_ "Confidence" SG_ 914 BMS_moduleType 0;
BA_ "Confidence" SG_ 914 BMS_thermalPackType 0;
BA_ "Confidence" SG_ 914 BMS_packMass 0;
BA_ "Confidence" SG_ 914 BMS_platformMaxBusVoltage 0;
BA_ "Confidence" SG_ 914 BMS_standbySupplyContinuousPower 0;
BA_ "SystemSignalLongSymbol" SG_ 914 BMS_standbySupplyContinuousPower "BMS_standbySupplyContinuousPowerLimit";
BA_ "Confidence" SG_ 914 BMS_beginningOfLifePackEnergy 0;
BA_ "GenSigSNA" SG_ 914 BMS_beginningOfLifePackEnergy "1023";
VAL_ 800 BMS_matrixIndex 4 "AlertMatrix4" 3 "AlertMatrix3" 2 "AlertMatrix2" 1 "AlertMatrix1" 0 "AlertMatrix0" ;
VAL_ 818 BMS_bmbMinMaxMultiplexer 2 "END" 1 "VOLT_MUX1" 0 "THERM_MUX0" ;
VAL_ 1025 BMS_brickVoltageMultiplexer 35 "Mux35" 34 "Mux34" 33 "Mux33" 32 "Mux32" 31 "Mux31" 30 "Mux30" 29 "Mux29" 28 "Mux28" 27 "Mux27" 26 "Mux26" 25 "Mux25" 24 "Mux24" 23 "Mux23" 22 "Mux22" 21 "Mux21" 20 "Mux20" 19 "Mux19" 18 "Mux18" 17 "Mux17" 16 "Mux16" 15 "Mux15" 14 "Mux14" 13 "Mux13" 12 "Mux12" 11 "Mux11" 10 "Mux10" 9 "Mux9" 8 "Mux8" 7 "Mux7" 6 "Mux6" 5 "Mux5" 4 "Mux4" 3 "Mux3" 2 "Mux2" 1 "Mux1" 0 "Mux0" ;
VAL_ 1025 BMS_brickVoltageStatus1 3 "SENSOR_BYPASSED" 2 "SENSOR_NOMINAL" 1 "SENSOR_BAD" 0 "SENSOR_MISSING" ;
VAL_ 1025 BMS_brickVoltageStatus2 3 "SENSOR_BYPASSED" 2 "SENSOR_NOMINAL" 1 "SENSOR_BAD" 0 "SENSOR_MISSING" ;
VAL_ 1025 BMS_brickVoltageStatus3 3 "SENSOR_BYPASSED" 2 "SENSOR_NOMINAL" 1 "SENSOR_BAD" 0 "SENSOR_MISSING" ;
VAL_ 1025 BMS_brickVoltageStatus4 3 "SENSOR_BYPASSED" 2 "SENSOR_NOMINAL" 1 "SENSOR_BAD" 0 "SENSOR_MISSING" ;
VAL_ 1025 BMS_brickVoltageStatus5 3 "SENSOR_BYPASSED" 2 "SENSOR_NOMINAL" 1 "SENSOR_BAD" 0 "SENSOR_MISSING" ;
VAL_ 1025 BMS_brickVoltageStatus6 3 "SENSOR_BYPASSED" 2 "SENSOR_NOMINAL" 1 "SENSOR_BAD" 0 "SENSOR_MISSING" ;
VAL_ 1025 BMS_brickVoltageStatus7 3 "SENSOR_BYPASSED" 2 "SENSOR_NOMINAL" 1 "SENSOR_BAD" 0 "SENSOR_MISSING" ;
VAL_ 1025 BMS_brickVoltageStatus8 3 "SENSOR_BYPASSED" 2 "SENSOR_NOMINAL" 1 "SENSOR_BAD" 0 "SENSOR_MISSING" ;
VAL_ 1025 BMS_brickVoltageStatus9 3 "SENSOR_BYPASSED" 2 "SENSOR_NOMINAL" 1 "SENSOR_BAD" 0 "SENSOR_MISSING" ;
VAL_ 1025 BMS_brickVoltageStatus10 3 "SENSOR_BYPASSED" 2 "SENSOR_NOMINAL" 1 "SENSOR_BAD" 0 "SENSOR_MISSING" ;
VAL_ 1025 BMS_brickVoltageStatus11 3 "SENSOR_BYPASSED" 2 "SENSOR_NOMINAL" 1 "SENSOR_BAD" 0 "SENSOR_MISSING" ;
VAL_ 1025 BMS_brickVoltageStatus12 3 "SENSOR_BYPASSED" 2 "SENSOR_NOMINAL" 1 "SENSOR_BAD" 0 "SENSOR_MISSING" ;
VAL_ 1025 BMS_brickVoltageStatus13 3 "SENSOR_BYPASSED" 2 "SENSOR_NOMINAL" 1 "SENSOR_BAD" 0 "SENSOR_MISSING" ;
VAL_ 1025 BMS_brickVoltageStatus14 3 "SENSOR_BYPASSED" 2 "SENSOR_NOMINAL" 1 "SENSOR_BAD" 0 "SENSOR_MISSING" ;
VAL_ 1025 BMS_brickVoltageStatus15 3 "SENSOR_BYPASSED" 2 "SENSOR_NOMINAL" 1 "SENSOR_BAD" 0 "SENSOR_MISSING" ;
VAL_ 1025 BMS_brickVoltageStatus16 3 "SENSOR_BYPASSED" 2 "SENSOR_NOMINAL" 1 "SENSOR_BAD" 0 "SENSOR_MISSING" ;
VAL_ 1025 BMS_brickVoltageStatus17 3 "SENSOR_BYPASSED" 2 "SENSOR_NOMINAL" 1 "SENSOR_BAD" 0 "SENSOR_MISSING" ;
VAL_ 1025 BMS_brickVoltageStatus18 3 "SENSOR_BYPASSED" 2 "SENSOR_NOMINAL" 1 "SENSOR_BAD" 0 "SENSOR_MISSING" ;
VAL_ 1025 BMS_brickVoltageStatus19 3 "SENSOR_BYPASSED" 2 "SENSOR_NOMINAL" 1 "SENSOR_BAD" 0 "SENSOR_MISSING" ;
VAL_ 1025 BMS_brickVoltageStatus20 3 "SENSOR_BYPASSED" 2 "SENSOR_NOMINAL" 1 "SENSOR_BAD" 0 "SENSOR_MISSING" ;
VAL_ 1025 BMS_brickVoltageStatus21 3 "SENSOR_BYPASSED" 2 "SENSOR_NOMINAL" 1 "SENSOR_BAD" 0 "SENSOR_MISSING" ;
VAL_ 1025 BMS_brickVoltageStatus22 3 "SENSOR_BYPASSED" 2 "SENSOR_NOMINAL" 1 "SENSOR_BAD" 0 "SENSOR_MISSING" ;
VAL_ 1025 BMS_brickVoltageStatus23 3 "SENSOR_BYPASSED" 2 "SENSOR_NOMINAL" 1 "SENSOR_BAD" 0 "SENSOR_MISSING" ;
VAL_ 1025 BMS_brickVoltageStatus24 3 "SENSOR_BYPASSED" 2 "SENSOR_NOMINAL" 1 "SENSOR_BAD" 0 "SENSOR_MISSING" ;
VAL_ 1025 BMS_brickVoltageStatus25 3 "SENSOR_BYPASSED" 2 "SENSOR_NOMINAL" 1 "SENSOR_BAD" 0 "SENSOR_MISSING" ;
VAL_ 1025 BMS_brickVoltageStatus26 3 "SENSOR_BYPASSED" 2 "SENSOR_NOMINAL" 1 "SENSOR_BAD" 0 "SENSOR_MISSING" ;
VAL_ 1025 BMS_brickVoltageStatus27 3 "SENSOR_BYPASSED" 2 "SENSOR_NOMINAL" 1 "SENSOR_BAD" 0 "SENSOR_MISSING" ;
VAL_ 1025 BMS_brickVoltageStatus28 3 "SENSOR_BYPASSED" 2 "SENSOR_NOMINAL" 1 "SENSOR_BAD" 0 "SENSOR_MISSING" ;
VAL_ 1025 BMS_brickVoltageStatus29 3 "SENSOR_BYPASSED" 2 "SENSOR_NOMINAL" 1 "SENSOR_BAD" 0 "SENSOR_MISSING" ;
VAL_ 1025 BMS_brickVoltageStatus30 3 "SENSOR_BYPASSED" 2 "SENSOR_NOMINAL" 1 "SENSOR_BAD" 0 "SENSOR_MISSING" ;
VAL_ 1025 BMS_brickVoltageStatus31 3 "SENSOR_BYPASSED" 2 "SENSOR_NOMINAL" 1 "SENSOR_BAD" 0 "SENSOR_MISSING" ;
VAL_ 1025 BMS_brickVoltageStatus32 3 "SENSOR_BYPASSED" 2 "SENSOR_NOMINAL" 1 "SENSOR_BAD" 0 "SENSOR_MISSING" ;
VAL_ 1025 BMS_brickVoltageStatus33 3 "SENSOR_BYPASSED" 2 "SENSOR_NOMINAL" 1 "SENSOR_BAD" 0 "SENSOR_MISSING" ;
VAL_ 1025 BMS_brickVoltageStatus34 3 "SENSOR_BYPASSED" 2 "SENSOR_NOMINAL" 1 "SENSOR_BAD" 0 "SENSOR_MISSING" ;
VAL_ 1025 BMS_brickVoltageStatus35 3 "SENSOR_BYPASSED" 2 "SENSOR_NOMINAL" 1 "SENSOR_BAD" 0 "SENSOR_MISSING" ;
VAL_ 1025 BMS_brickVoltageStatus36 3 "SENSOR_BYPASSED" 2 "SENSOR_NOMINAL" 1 "SENSOR_BAD" 0 "SENSOR_MISSING" ;
VAL_ 1025 BMS_brickVoltageStatus37 3 "SENSOR_BYPASSED" 2 "SENSOR_NOMINAL" 1 "SENSOR_BAD" 0 "SENSOR_MISSING" ;
VAL_ 1025 BMS_brickVoltageStatus38 3 "SENSOR_BYPASSED" 2 "SENSOR_NOMINAL" 1 "SENSOR_BAD" 0 "SENSOR_MISSING" ;
VAL_ 1025 BMS_brickVoltageStatus39 3 "SENSOR_BYPASSED" 2 "SENSOR_NOMINAL" 1 "SENSOR_BAD" 0 "SENSOR_MISSING" ;
VAL_ 1025 BMS_brickVoltageStatus40 3 "SENSOR_BYPASSED" 2 "SENSOR_NOMINAL" 1 "SENSOR_BAD" 0 "SENSOR_MISSING" ;
VAL_ 1025 BMS_brickVoltageStatus41 3 "SENSOR_BYPASSED" 2 "SENSOR_NOMINAL" 1 "SENSOR_BAD" 0 "SENSOR_MISSING" ;
VAL_ 1025 BMS_brickVoltageStatus42 3 "SENSOR_BYPASSED" 2 "SENSOR_NOMINAL" 1 "SENSOR_BAD" 0 "SENSOR_MISSING" ;
VAL_ 1025 BMS_brickVoltageStatus43 3 "SENSOR_BYPASSED" 2 "SENSOR_NOMINAL" 1 "SENSOR_BAD" 0 "SENSOR_MISSING" ;
VAL_ 1025 BMS_brickVoltageStatus44 3 "SENSOR_BYPASSED" 2 "SENSOR_NOMINAL" 1 "SENSOR_BAD" 0 "SENSOR_MISSING" ;
VAL_ 1025 BMS_brickVoltageStatus45 3 "SENSOR_BYPASSED" 2 "SENSOR_NOMINAL" 1 "SENSOR_BAD" 0 "SENSOR_MISSING" ;
VAL_ 1025 BMS_brickVoltageStatus46 3 "SENSOR_BYPASSED" 2 "SENSOR_NOMINAL" 1 "SENSOR_BAD" 0 "SENSOR_MISSING" ;
VAL_ 1025 BMS_brickVoltageStatus47 3 "SENSOR_BYPASSED" 2 "SENSOR_NOMINAL" 1 "SENSOR_BAD" 0 "SENSOR_MISSING" ;
VAL_ 1025 BMS_brickVoltageStatus48 3 "SENSOR_BYPASSED" 2 "SENSOR_NOMINAL" 1 "SENSOR_BAD" 0 "SENSOR_MISSING" ;
VAL_ 1025 BMS_brickVoltageStatus49 3 "SENSOR_BYPASSED" 2 "SENSOR_NOMINAL" 1 "SENSOR_BAD" 0 "SENSOR_MISSING" ;
VAL_ 1025 BMS_brickVoltageStatus50 3 "SENSOR_BYPASSED" 2 "SENSOR_NOMINAL" 1 "SENSOR_BAD" 0 "SENSOR_MISSING" ;
VAL_ 1025 BMS_brickVoltageStatus51 3 "SENSOR_BYPASSED" 2 "SENSOR_NOMINAL" 1 "SENSOR_BAD" 0 "SENSOR_MISSING" ;
VAL_ 1025 BMS_brickVoltageStatus52 3 "SENSOR_BYPASSED" 2 "SENSOR_NOMINAL" 1 "SENSOR_BAD" 0 "SENSOR_MISSING" ;
VAL_ 1025 BMS_brickVoltageStatus53 3 "SENSOR_BYPASSED" 2 "SENSOR_NOMINAL" 1 "SENSOR_BAD" 0 "SENSOR_MISSING" ;
VAL_ 1025 BMS_brickVoltageStatus54 3 "SENSOR_BYPASSED" 2 "SENSOR_NOMINAL" 1 "SENSOR_BAD" 0 "SENSOR_MISSING" ;
VAL_ 1025 BMS_brickVoltageStatus55 3 "SENSOR_BYPASSED" 2 "SENSOR_NOMINAL" 1 "SENSOR_BAD" 0 "SENSOR_MISSING" ;
VAL_ 1025 BMS_brickVoltageStatus56 3 "SENSOR_BYPASSED" 2 "SENSOR_NOMINAL" 1 "SENSOR_BAD" 0 "SENSOR_MISSING" ;
VAL_ 1025 BMS_brickVoltageStatus57 3 "SENSOR_BYPASSED" 2 "SENSOR_NOMINAL" 1 "SENSOR_BAD" 0 "SENSOR_MISSING" ;
VAL_ 1025 BMS_brickVoltageStatus58 3 "SENSOR_BYPASSED" 2 "SENSOR_NOMINAL" 1 "SENSOR_BAD" 0 "SENSOR_MISSING" ;
VAL_ 1025 BMS_brickVoltageStatus59 3 "SENSOR_BYPASSED" 2 "SENSOR_NOMINAL" 1 "SENSOR_BAD" 0 "SENSOR_MISSING" ;
VAL_ 1025 BMS_brickVoltageStatus60 3 "SENSOR_BYPASSED" 2 "SENSOR_NOMINAL" 1 "SENSOR_BAD" 0 "SENSOR_MISSING" ;
VAL_ 1025 BMS_brickVoltageStatus61 3 "SENSOR_BYPASSED" 2 "SENSOR_NOMINAL" 1 "SENSOR_BAD" 0 "SENSOR_MISSING" ;
VAL_ 1025 BMS_brickVoltageStatus62 3 "SENSOR_BYPASSED" 2 "SENSOR_NOMINAL" 1 "SENSOR_BAD" 0 "SENSOR_MISSING" ;
VAL_ 1025 BMS_brickVoltageStatus63 3 "SENSOR_BYPASSED" 2 "SENSOR_NOMINAL" 1 "SENSOR_BAD" 0 "SENSOR_MISSING" ;
VAL_ 1025 BMS_brickVoltageStatus64 3 "SENSOR_BYPASSED" 2 "SENSOR_NOMINAL" 1 "SENSOR_BAD" 0 "SENSOR_MISSING" ;
VAL_ 1025 BMS_brickVoltageStatus65 3 "SENSOR_BYPASSED" 2 "SENSOR_NOMINAL" 1 "SENSOR_BAD" 0 "SENSOR_MISSING" ;
VAL_ 1025 BMS_brickVoltageStatus66 3 "SENSOR_BYPASSED" 2 "SENSOR_NOMINAL" 1 "SENSOR_BAD" 0 "SENSOR_MISSING" ;
VAL_ 1025 BMS_brickVoltageStatus67 3 "SENSOR_BYPASSED" 2 "SENSOR_NOMINAL" 1 "SENSOR_BAD" 0 "SENSOR_MISSING" ;
VAL_ 1025 BMS_brickVoltageStatus68 3 "SENSOR_BYPASSED" 2 "SENSOR_NOMINAL" 1 "SENSOR_BAD" 0 "SENSOR_MISSING" ;
VAL_ 1025 BMS_brickVoltageStatus69 3 "SENSOR_BYPASSED" 2 "SENSOR_NOMINAL" 1 "SENSOR_BAD" 0 "SENSOR_MISSING" ;
VAL_ 1025 BMS_brickVoltageStatus70 3 "SENSOR_BYPASSED" 2 "SENSOR_NOMINAL" 1 "SENSOR_BAD" 0 "SENSOR_MISSING" ;
VAL_ 1025 BMS_brickVoltageStatus71 3 "SENSOR_BYPASSED" 2 "SENSOR_NOMINAL" 1 "SENSOR_BAD" 0 "SENSOR_MISSING" ;
VAL_ 1025 BMS_brickVoltageStatus72 3 "SENSOR_BYPASSED" 2 "SENSOR_NOMINAL" 1 "SENSOR_BAD" 0 "SENSOR_MISSING" ;
VAL_ 1025 BMS_brickVoltageStatus73 3 "SENSOR_BYPASSED" 2 "SENSOR_NOMINAL" 1 "SENSOR_BAD" 0 "SENSOR_MISSING" ;
VAL_ 1025 BMS_brickVoltageStatus74 3 "SENSOR_BYPASSED" 2 "SENSOR_NOMINAL" 1 "SENSOR_BAD" 0 "SENSOR_MISSING" ;
VAL_ 1025 BMS_brickVoltageStatus75 3 "SENSOR_BYPASSED" 2 "SENSOR_NOMINAL" 1 "SENSOR_BAD" 0 "SENSOR_MISSING" ;
VAL_ 1025 BMS_brickVoltageStatus76 3 "SENSOR_BYPASSED" 2 "SENSOR_NOMINAL" 1 "SENSOR_BAD" 0 "SENSOR_MISSING" ;
VAL_ 1025 BMS_brickVoltageStatus77 3 "SENSOR_BYPASSED" 2 "SENSOR_NOMINAL" 1 "SENSOR_BAD" 0 "SENSOR_MISSING" ;
VAL_ 1025 BMS_brickVoltageStatus78 3 "SENSOR_BYPASSED" 2 "SENSOR_NOMINAL" 1 "SENSOR_BAD" 0 "SENSOR_MISSING" ;
VAL_ 1025 BMS_brickVoltageStatus79 3 "SENSOR_BYPASSED" 2 "SENSOR_NOMINAL" 1 "SENSOR_BAD" 0 "SENSOR_MISSING" ;
VAL_ 1025 BMS_brickVoltageStatus80 3 "SENSOR_BYPASSED" 2 "SENSOR_NOMINAL" 1 "SENSOR_BAD" 0 "SENSOR_MISSING" ;
VAL_ 1025 BMS_brickVoltageStatus81 3 "SENSOR_BYPASSED" 2 "SENSOR_NOMINAL" 1 "SENSOR_BAD" 0 "SENSOR_MISSING" ;
VAL_ 1025 BMS_brickVoltageStatus82 3 "SENSOR_BYPASSED" 2 "SENSOR_NOMINAL" 1 "SENSOR_BAD" 0 "SENSOR_MISSING" ;
VAL_ 1025 BMS_brickVoltageStatus83 3 "SENSOR_BYPASSED" 2 "SENSOR_NOMINAL" 1 "SENSOR_BAD" 0 "SENSOR_MISSING" ;
VAL_ 1025 BMS_brickVoltageStatus84 3 "SENSOR_BYPASSED" 2 "SENSOR_NOMINAL" 1 "SENSOR_BAD" 0 "SENSOR_MISSING" ;
VAL_ 1025 BMS_brickVoltageStatus85 3 "SENSOR_BYPASSED" 2 "SENSOR_NOMINAL" 1 "SENSOR_BAD" 0 "SENSOR_MISSING" ;
VAL_ 1025 BMS_brickVoltageStatus86 3 "SENSOR_BYPASSED" 2 "SENSOR_NOMINAL" 1 "SENSOR_BAD" 0 "SENSOR_MISSING" ;
VAL_ 1025 BMS_brickVoltageStatus87 3 "SENSOR_BYPASSED" 2 "SENSOR_NOMINAL" 1 "SENSOR_BAD" 0 "SENSOR_MISSING" ;
VAL_ 1025 BMS_brickVoltageStatus88 3 "SENSOR_BYPASSED" 2 "SENSOR_NOMINAL" 1 "SENSOR_BAD" 0 "SENSOR_MISSING" ;
VAL_ 1025 BMS_brickVoltageStatus89 3 "SENSOR_BYPASSED" 2 "SENSOR_NOMINAL" 1 "SENSOR_BAD" 0 "SENSOR_MISSING" ;
VAL_ 1025 BMS_brickVoltageStatus90 3 "SENSOR_BYPASSED" 2 "SENSOR_NOMINAL" 1 "SENSOR_BAD" 0 "SENSOR_MISSING" ;
VAL_ 1025 BMS_brickVoltageStatus91 3 "SENSOR_BYPASSED" 2 "SENSOR_NOMINAL" 1 "SENSOR_BAD" 0 "SENSOR_MISSING" ;
VAL_ 1025 BMS_brickVoltageStatus92 3 "SENSOR_BYPASSED" 2 "SENSOR_NOMINAL" 1 "SENSOR_BAD" 0 "SENSOR_MISSING" ;
VAL_ 1025 BMS_brickVoltageStatus93 3 "SENSOR_BYPASSED" 2 "SENSOR_NOMINAL" 1 "SENSOR_BAD" 0 "SENSOR_MISSING" ;
VAL_ 1025 BMS_brickVoltageStatus94 3 "SENSOR_BYPASSED" 2 "SENSOR_NOMINAL" 1 "SENSOR_BAD" 0 "SENSOR_MISSING" ;
VAL_ 1025 BMS_brickVoltageStatus95 3 "SENSOR_BYPASSED" 2 "SENSOR_NOMINAL" 1 "SENSOR_BAD" 0 "SENSOR_MISSING" ;
VAL_ 1025 BMS_brickVoltageStatus96 3 "SENSOR_BYPASSED" 2 "SENSOR_NOMINAL" 1 "SENSOR_BAD" 0 "SENSOR_MISSING" ;
VAL_ 1025 BMS_brickVoltageStatus97 3 "SENSOR_BYPASSED" 2 "SENSOR_NOMINAL" 1 "SENSOR_BAD" 0 "SENSOR_MISSING" ;
VAL_ 1025 BMS_brickVoltageStatus98 3 "SENSOR_BYPASSED" 2 "SENSOR_NOMINAL" 1 "SENSOR_BAD" 0 "SENSOR_MISSING" ;
VAL_ 1025 BMS_brickVoltageStatus99 3 "SENSOR_BYPASSED" 2 "SENSOR_NOMINAL" 1 "SENSOR_BAD" 0 "SENSOR_MISSING" ;
VAL_ 1025 BMS_brickVoltageStatus100 3 "SENSOR_BYPASSED" 2 "SENSOR_NOMINAL" 1 "SENSOR_BAD" 0 "SENSOR_MISSING" ;
VAL_ 1025 BMS_brickVoltageStatus101 3 "SENSOR_BYPASSED" 2 "SENSOR_NOMINAL" 1 "SENSOR_BAD" 0 "SENSOR_MISSING" ;
VAL_ 1025 BMS_brickVoltageStatus102 3 "SENSOR_BYPASSED" 2 "SENSOR_NOMINAL" 1 "SENSOR_BAD" 0 "SENSOR_MISSING" ;
VAL_ 1025 BMS_brickVoltageStatus103 3 "SENSOR_BYPASSED" 2 "SENSOR_NOMINAL" 1 "SENSOR_BAD" 0 "SENSOR_MISSING" ;
VAL_ 1025 BMS_brickVoltageStatus104 3 "SENSOR_BYPASSED" 2 "SENSOR_NOMINAL" 1 "SENSOR_BAD" 0 "SENSOR_MISSING" ;
VAL_ 1025 BMS_brickVoltageStatus105 3 "SENSOR_BYPASSED" 2 "SENSOR_NOMINAL" 1 "SENSOR_BAD" 0 "SENSOR_MISSING" ;
VAL_ 1025 BMS_brickVoltageStatus106 3 "SENSOR_BYPASSED" 2 "SENSOR_NOMINAL" 1 "SENSOR_BAD" 0 "SENSOR_MISSING" ;
VAL_ 1025 BMS_brickVoltageStatus107 3 "SENSOR_BYPASSED" 2 "SENSOR_NOMINAL" 1 "SENSOR_BAD" 0 "SENSOR_MISSING" ;
VAL_ 1025 BMS_brickVoltageStatus108 3 "SENSOR_BYPASSED" 2 "SENSOR_NOMINAL" 1 "SENSOR_BAD" 0 "SENSOR_MISSING" ;
VAL_ 1138 BMS_acChargePowerSample 255 "SNA" ;
VAL_ 1138 BMS_userChargeCurrentLimitMode 4 "USR_CHG_LIMIT_EVSE_RELOCATION_RECOMMENDED" 3 "USR_CHG_LIMIT_HIGH_SOC" 2 "USR_CHG_LIMIT_BATT_TEMP_LOW" 1 "USR_CHG_LIMIT_EVSE" 0 "USR_CHG_LIMIT_NONE" ;
VAL_ 1138 BMS_chargeCurrentLimitMode 20 "CHG_LIMIT_RIPPLE_HEAT_ACTIVE" 19 "CHG_LIMIT_NEAR_HWOT_LIMIT" 18 "CHG_LIMIT_LIMP_MODE" 17 "CHG_LIMIT_MISSING_CELL" 16 "CHG_LIMIT_CAC_IMBALANCE" 15 "CHG_LIMIT_PCS_IMPLICIT" 14 "CHG_LIMIT_EVSE_IMPLICIT" 13 "CHG_LIMIT_RAMP_UP_PHASE" 12 "CHG_LIMIT_HVAC_COOLING" 11 "CHG_LIMIT_HV_CHAIN" 10 "CHG_LIMIT_CONFIG" 9 "CHG_LIMIT_TETHERING" 8 "CHG_LIMIT_LEAKY_BUCKET" 7 "CHG_LIMIT_BRICK_VOLTAGE_REG" 6 "CHG_LIMIT_BRICK_TEMP_TOO_COLD" 5 "CHG_LIMIT_BRICK_TEMP_TOO_HOT" 4 "CHG_LIMIT_BRICK_TEMP_OPTIMAL_CELL_PROFILE" 3 "CHG_LIMIT_CP" 2 "CHG_LIMIT_PCS" 1 "CHG_LIMIT_EVSE" 0 "CHG_LIMIT_NONE" ;
VAL_ 1138 BMS_timeToFinishHeatForCharge 127 "SNA" 126 "CALCULATING" ;
VAL_ 1138 BMS_timeToTripPlanChargingTarget 2047 "SNA" ;
VAL_ 562 BMS_fcContactorRequest 5 "SET_REQUEST_CLOSE_POSITIVE_ONLY" 4 "SET_REQUEST_CLOSE_NEGATIVE_ONLY" 3 "SET_REQUEST_OPEN_IMMEDIATELY" 2 "SET_REQUEST_OPEN" 1 "SET_REQUEST_CLOSE" 0 "SET_REQUEST_SNA" ;
VAL_ 562 BMS_packContactorRequest 5 "SET_REQUEST_CLOSE_POSITIVE_ONLY" 4 "SET_REQUEST_CLOSE_NEGATIVE_ONLY" 3 "SET_REQUEST_OPEN_IMMEDIATELY" 2 "SET_REQUEST_OPEN" 1 "SET_REQUEST_CLOSE" 0 "SET_REQUEST_SNA" ;
VAL_ 562 BMS_fcLinkOkToEnergizeRequest 2 "FC_LINK_ENERGY_DC" 1 "FC_LINK_ENERGY_AC" 0 "FC_LINK_ENERGY_NONE" ;
VAL_ 562 BMS_internalHvilSenseV 65535 "SNA" ;
VAL_ 562 BMS_hvilCoverVSense 65535 "SNA" ;
VAL_ 690 BMS_energyStatusMultiplexer 2 "Mux2" 1 "Mux1" 0 "Mux0" ;
VAL_ 690 BMS_nominalFullPackEnergy 65535 "SNA" ;
VAL_ 690 BMS_nominalEnergyRemaining 65535 "SNA" ;
VAL_ 690 BMS_idealEnergyRemaining 65535 "SNA" ;
VAL_ 690 BMS_energyBuffer 65535 "SNA" ;
VAL_ 690 BMS_expectedEnergyRemaining 65535 "SNA" ;
VAL_ 690 BMS_energyToChargeComplete 65535 "SNA" ;
VAL_ 690 BMS_energyRemainingDisplay 65535 "SNA" ;
VAL_ 690 BMS_energyRemainingTDisplay 65535 "SNA" ;
VAL_ 690 BMS_userFacingSoe 2047 "SNA" ;
VAL_ 306 BMS_packCurrent -32768 "SNA" ;
VAL_ 306 BMS_currentUnfiltered -32768 "SNA" ;
VAL_ 768 BMS_infoIndex 255 "END" 31 "SUBCOMPONENT_GITHASH" 30 "PACKAGE_SN_8_14" 29 "PACKAGE_SN_1_7" 27 "PACKAGE_PN_15_20" 26 "PACKAGE_PN_8_14" 25 "PACKAGE_PN_1_7" 23 "SUBCOMPONENT2" 22 "VARIANTCRC" 20 "UDS_PROTOCOL_BOOTCRC" 19 "VERSION_DEPRECATED" 18 "BOOTLOADER_GITHASH" 17 "APP_GITHASH" 16 "SUBCOMPONENT" 15 "BOOTLOADER_CRC" 14 "BOOTLOADER_SVN" 13 "APP_CRC" 11 "PCBAID_ASSYID_USAGEID" 10 "BUILD_HWID_COMPONENTID" 9 "DEPRECATED_9" 8 "DEPRECATED_8" 7 "DEPRECATED_7" 6 "DEPRECATED_6" 5 "DEPRECATED_5" 4 "DEPRECATED_4" 3 "DEPRECATED_3" 2 "DEPRECATED_2" 1 "DEPRECATED_1" 0 "DEPRECATED_0" ;
VAL_ 768 BMS_buildType 4 "INFO_MFG_BUILD" 3 "INFO_TRACEABLE_CI_BUILD" 2 "INFO_LOCAL_BUILD" 1 "INFO_PLATFORM_BUILD" 0 "INFO_UNKNOWN_BUILD" ;
VAL_ 1010 BMS_kwhCounter_Id 14 "END" 13 "MUX13" 12 "MUX12" 11 "MUX11" 10 "MUX10" 9 "MUX9" 8 "MUX8" 7 "MUX7" 6 "MUX6" 5 "MUX5" 4 "MUX4" 3 "MUX3" 2 "MUX2" 1 "MUX1" 0 "MUX0" ;
VAL_ 884 BMS_log1MuxId 14 "CHARGE_ENERGY_4" 13 "CHARGE_ENERGY_3_AND_PACK_VOLTAGE" 12 "SLEEP_CURRENT_1_STATES_AND_BOOLS" 11 "PACK_DATA" 10 "CHARGE_REGULATION" 9 "CHARGE_TERMINATION" 8 "RAW_CDCR_2" 7 "RAW_CDCR_1" 6 "BANDOLIER_MODEL_PACK_TEMPS" 5 "CHARGE_INTERFACE_2" 4 "CHARGE_INTERFACE_1" 2 "CPU_USAGE3" 1 "CPU_USAGE2" 0 "CPU_USAGE1" ;
VAL_ 884 BMS_powerTransferStatus 8 "BMS_POWER_TRANSFER_BLOCKED" 7 "BMS_POWER_TRANSFER_FAULTED" 6 "BMS_EMERGENCY_SHUTDOWN" 5 "BMS_GRACEFUL_SHUTDOWN" 4 "BMS_POWER_TRANSFER_ENABLED" 3 "BMS_POWER_TRANSFER_ENABLING" 2 "BMS_EXT_PRECHARGE_ALLOWED" 1 "BMS_EXT_EVSE_TEST_ALLOWED" 0 "BMS_POWER_TRANSFER_STANDBY" ;
VAL_ 884 BMS_chargeEnergyWalkState 3 "ENERGY_WALK_STOPPED" 2 "ENERGY_WALK_COMPLETE" 1 "ENERGY_WALK_RUNNING" 0 "ENERGY_WALK_INIT" ;
VAL_ 884 BMS_energyWalkMaxPackCurrent -32768 "SNA" ;
VAL_ 884 BMS_battTempPct 255 "SNA" ;
VAL_ 884 BMS_powerTransferDisableType 3 "FAULTED" 2 "ABORTED" 1 "CANCELED" 0 "NONE" ;
VAL_ 884 BMS_powerTransferDisableReason 41 "PRECHARGE_NOT_COMPLETE" 40 "EVSE_OUTPUT_CURRENT_NOT_LOW" 39 "ALL_RETRIES_EXHAUSTED" 38 "TEMP_TOO_LOW" 37 "FEATURE_DISABLED" 36 "SOE_TOO_LOW" 35 "AC_RELAYS_NOT_OPEN" 34 "PCS_NOT_DISABLED" 33 "CP_INLET_STILL_ENERGIZED" 32 "PCS_NOT_ENABLED" 31 "CP_NOT_ENABLED" 30 "CP_NOT_READY" 29 "SYSTEM_NOT_ENABLED" 28 "PCS_DISALLOWS" 27 "CP_DISALLOWS" 26 "SYSTEM_NOT_ALLOWED" 25 "SYSTEM_NOT_POSSIBLE" 24 "PCS_GRACEFUL_SHUTDOWN_REQUESTED" 23 "CP_GRACEFUL_SHUTDOWN_REQUESTED" 22 "NOT_NEEDED_OR_WANTED" 21 "EVSE_NOT_READY" 20 "EVSE_NOT_PRESENT" 19 "STATE_TIMEOUT_EXPIRED" 18 "FC_LINK_NOT_READY" 17 "FC_CONTACTORS_NOT_CLOSED" 16 "FC_CONTACTORS_NOT_OPEN" 15 "EVSE_NOT_COMPATIBLE" 14 "FC_LINK_NOT_ALLOWED_TO_ENERGIZE" 13 "ABORT_SUPERDISCHARGE_ALERT_SET" 12 "ABORT_CHARGE_ALERT_SET" 11 "PCS_ESCALATED_SHUTDOWN_REQUESTED" 10 "CP_ESCALATED_SHUTDOWN_REQUESTED" 7 "POWERSHARE_PROTECTION_TRIPPED" 6 "SYSTEM_DIRECTOR_FAULT_REQUESTED" 5 "CP_FAULT_LINE_ASSERTED" 4 "PCS_EMERGENCY_SHUTDOWN_REQUESTED" 3 "CP_EMERGENCY_SHUTDOWN_REQUESTED" 2 "PCS_MIA" 1 "CP_MIA" 0 "COND_NONE" ;
VAL_ 884 BMS_powerTransferWaitCondition 41 "PRECHARGE_NOT_COMPLETE" 40 "EVSE_OUTPUT_CURRENT_NOT_LOW" 39 "ALL_RETRIES_EXHAUSTED" 38 "TEMP_TOO_LOW" 37 "FEATURE_DISABLED" 36 "SOE_TOO_LOW" 35 "AC_RELAYS_NOT_OPEN" 34 "PCS_NOT_DISABLED" 33 "CP_INLET_STILL_ENERGIZED" 32 "PCS_NOT_ENABLED" 31 "CP_NOT_ENABLED" 30 "CP_NOT_READY" 29 "SYSTEM_NOT_ENABLED" 28 "PCS_DISALLOWS" 27 "CP_DISALLOWS" 26 "SYSTEM_NOT_ALLOWED" 25 "SYSTEM_NOT_POSSIBLE" 24 "PCS_GRACEFUL_SHUTDOWN_REQUESTED" 23 "CP_GRACEFUL_SHUTDOWN_REQUESTED" 22 "NOT_NEEDED_OR_WANTED" 21 "EVSE_NOT_READY" 20 "EVSE_NOT_PRESENT" 19 "STATE_TIMEOUT_EXPIRED" 18 "FC_LINK_NOT_READY" 17 "FC_CONTACTORS_NOT_CLOSED" 16 "FC_CONTACTORS_NOT_OPEN" 15 "EVSE_NOT_COMPATIBLE" 14 "FC_LINK_NOT_ALLOWED_TO_ENERGIZE" 13 "ABORT_SUPERDISCHARGE_ALERT_SET" 12 "ABORT_CHARGE_ALERT_SET" 11 "PCS_ESCALATED_SHUTDOWN_REQUESTED" 10 "CP_ESCALATED_SHUTDOWN_REQUESTED" 7 "POWERSHARE_PROTECTION_TRIPPED" 6 "SYSTEM_DIRECTOR_FAULT_REQUESTED" 5 "CP_FAULT_LINE_ASSERTED" 4 "PCS_EMERGENCY_SHUTDOWN_REQUESTED" 3 "CP_EMERGENCY_SHUTDOWN_REQUESTED" 2 "PCS_MIA" 1 "CP_MIA" 0 "COND_NONE" ;
VAL_ 946 BMS_log2MuxId 95 "MUX_95" 94 "SOC_IMBALANCE_BY_DV_DSOC" 93 "MUX_93" 92 "BANDOLIER_MODEL_THERMISTOR_TEMPS_2" 91 "MUX_91" 90 "MUX_90" 89 "MUX_89" 88 "MUX_88" 87 "MUX_87" 86 "MUX_86" 85 "MUX_85" 84 "MUX_84" 83 "MUX_83" 82 "MUX_82" 81 "MUX_81" 80 "MUX_80" 79 "MUX_79" 78 "BANDOLIER_MODEL_THERMISTOR_TEMPS_1" 77 "MUX_77" 76 "MUX_76" 75 "MUX_75" 74 "MUX_74" 73 "MUX_73" 72 "MUX_72" 71 "MUX_71" 70 "MUX_70" 69 "MUX_69" 68 "MUX_68" 67 "MUX_67" 66 "MUX_66" 65 "MUX_65" 64 "MUX_64" 63 "MUX_63" 62 "MUX_62" 61 "MUX_61" 60 "MUX_60" 59 "MUX_59" 58 "MUX_58" 57 "MUX_57" 56 "MUX_56" 55 "LIFE_MODEL_HIST_SUMMARY_DATA" 54 "LIFE_MODEL_STORAGE_HIST_DATA" 53 "SPME_MAX_SOC_BRICK_DATA" 52 "SPME_MIN_SOC_BRICK_DATA" 51 "SPME_DATA_3" 50 "SPME_BRICK_1_DATA_2" 49 "SPME_BRICK_1_DATA_1" 48 "SPME_PACK_LEVEL" 47 "BRICK_BLEED_TIMES_5" 46 "HISTOGRAMS_SUMMARY" 45 "SOH" 44 "CAC4" 43 "ISOLATION" 42 "BRICK_BLEED_TIMES_4" 41 "BRICK_BLEED_TIMES_3" 40 "BRICK_BLEED_TIMES_2" 39 "BRICK_BLEED_TIMES_1" 38 "LIFE_MODEL" 37 "BRICK_BALANCE_4" 36 "BRICK_BALANCE_3" 35 "BRICK_BALANCE_2" 34 "BRICK_BALANCE_1" 33 "ALPHA_1" 32 "HISTOGRAMS_4" 31 "HISTOGRAMS_3" 30 "HISTOGRAMS_2" 29 "HISTOGRAMS_1" 28 "HISTOGRAMS_0" 27 "VSH_RES_3" 26 "VSH_RES_2" 25 "VSH_RES_1" 24 "SOC_BY_OCV_CORRECTION" 23 "BRICK_VOLTAGE_CHANGE" 22 "CAC3" 21 "ENERGY_AND_REST_DATA" 20 "FC_LINK_LEAKAGE_TEST" 19 "ENERGY_RESERVE" 18 "HV_CHAIN_MODEL" 17 "NEG_CTR_HEALTH_4" 16 "NEG_CTR_HEALTH_3" 15 "NEG_CTR_HEALTH_2" 14 "NEG_CTR_HEALTH_1" 13 "POS_CTR_HEALTH_4" 12 "POS_CTR_HEALTH_3" 11 "POS_CTR_HEALTH_2" 10 "POS_CTR_HEALTH_1" 9 "CTR_RESISTANCE" 8 "100HZ_1KHZ_TASK_STATS" 7 "10HZ_TASK_STATS" 6 "1HZ_TASK_STATS" 5 "AHR_COUNTER" 4 "CHARGING" 3 "VSH_TEST" 2 "FLOOD_PORT" 1 "CAC2" 0 "CAC1" ;
VAL_ 946 BMS_hvChain_iLimit 16383 "SNA" ;
VAL_ 946 BMS_hvChain_limitingState 511 "SNA" ;
VAL_ 946 BMS_hvChain_limitingStateTempera -4096 "SNA" ;
VAL_ 946 BMS_fcLinkTestDecayTime 1023 "SNA" ;
VAL_ 946 BMS_pcsPrechargeRequest 2 "LV_DISCHARGE" 1 "FC_LINK_TEST" 0 "PRECHARGE_INACTIVE" ;
VAL_ 946 BMS_idealEnergyFloor 1023 "SNA" ;
VAL_ 946 BMS_dynamicEnergyBuffer 1023 "SNA" ;
VAL_ 946 BMS_dSocNormalizedMin 4095 "SNA" ;
VAL_ 946 BMS_dSocNormalizedFiltMin 4095 "SNA" ;
VAL_ 946 BMS_dSocMinAlpha 4095 "SNA" ;
VAL_ 946 BMS_dSocCacMargin 511 "SNA" ;
VAL_ 946 BMS_lifeModelNoCurrentStorageCap 511 "SNA" ;
VAL_ 946 BMS_lifeModelShortDcr 255 "SNA" ;
VAL_ 946 BMS_lifeModelLongDcr -4096 "SNA" ;
VAL_ 946 BMS_lifeModelStorageCapacityLoss 511 "SNA" ;
VAL_ 946 BMS_lifeModelThroughputCapacityL 511 "SNA" ;
VAL_ 946 BMS_lifeModelAvgTempSeverity 31 "SNA" ;
VAL_ 946 BMS_lifeModelDepthOfDischargeSev 255 "SNA" ;
VAL_ 946 BMS_lifeModelHistogramCapacityLo 511 "SNA" ;
VAL_ 946 BMS_lifeModelHistogramBrickCapac 8191 "SNA" ;
VAL_ 946 BMS_lifeModelDcrGrowthPercent -8192 "SNA" ;
VAL_ 946 BMS_nominalFullPackEnergyRaw 65535 "SNA" ;
VAL_ 946 BMS_nominalEnergyRemainingBuffer 65535 "SNA" ;
VAL_ 946 BMS_idealEnergyRemainingBuffered 65535 "SNA" ;
VAL_ 946 BMS_largestSynchronizedCacErrorP 255 "SNA" ;
VAL_ 946 BMS_lifeModelSpreadMinOffset -512 "SNA" ;
VAL_ 946 BMS_lifeModelSpreadMaxOffset -512 "SNA" ;
VAL_ 946 BMS_largestCacSpreadErrorLower 4095 "SNA" ;
VAL_ 946 BMS_lifeModelAverageCac 4095 "SNA" ;
VAL_ 946 BMS_lifeModelCacBrick1 4095 "SNA" ;
VAL_ 946 BMS_lifeModelAverageOffset -512 "SNA" ;
VAL_ 946 BMS_lifeModelMaxCacBrickId 255 "SNA" ;
VAL_ 946 BMS_lifeModelMaxCac 4095 "SNA" ;
VAL_ 946 BMS_lifeModelMinCacBrickId 255 "SNA" ;
VAL_ 946 BMS_lifeModelMinCac 4095 "SNA" ;
VAL_ 946 BMS_restingPointCacAvg 4095 "SNA" ;
VAL_ 946 BMS_cacEstimationSource 2 "CAC_SOURCE_LIFE_MODEL" 1 "CAC_SOURCE_RESTING_POINT_CAC" 0 "CAC_SOURCE_UNKNOWN" ;
VAL_ 946 BMS_synchronizedCacMaxRaw 4095 "SNA" ;
VAL_ 946 BMS_synchronizedCacMinRaw 4095 "SNA" ;
VAL_ 946 BMS_sohEnergy 2047 "SNA" ;
VAL_ 946 BMS_fullCapacitySohEnergy 2047 "SNA" ;
VAL_ 946 BMS_calibratedCapacitySohEnergy 2047 "SNA" ;
VAL_ 946 BMS_estimatedCapacitySohEnergy 2047 "SNA" ;
VAL_ 946 BMS_prevUserFacingSohEnergy 2047 "SNA" ;
VAL_ 946 BMS_stateOfHealthMinCac 8191 "SNA" ;
VAL_ 946 BMS_lifeModelStorageLossPackAge 16383 "SNA" ;
VAL_ 946 BMS_lifeModelThroughputDcrCycleC 4095 "SNA" ;
VAL_ 946 BMS_stateOfHealthMinCacLowerBoun 8191 "SNA" ;
VAL_ 946 BMS_stateOfHealth 1023 "SNA" ;
VAL_ 946 BMS_avgShuntAsicCurrentOffset -16384 "SNA" ;
VAL_ 946 BMS_cellAttributesGeneralAttribu 0 "SNA" ;
VAL_ 946 BMS_cellAttributesPackManufactur 0 "SNA" ;
VAL_ 946 BMS_cellAttributesCellType 0 "SNA" ;
VAL_ 946 BMS_lifeModelThroughputCycleCoun 4095 "SNA" ;
VAL_ 946 BMS_limpChargeCurrentLimit 1023 "SNA" ;
VAL_ 946 BMS_maxModelThermistorTempDelta -512 "SNA" ;
VAL_ 946 BMS_cellTempTargetMode 11 "V2X_SESSION" 10 "PASSIVE_COOL_ON_NAV" 9 "ACTIVE_COOL_ON_NAV" 8 "SOH_HEAT_PACK" 7 "DRAGSTRIP" 6 "PASSIVE_HEAT_ON_NAV" 5 "ACTIVE_HEAT_ON_NAV" 4 "DISCONNECTED_PRECONDITION" 3 "CONNECTED_PRECONDITION" 2 "HIGH_POWER_CHARGE" 1 "LOW_POWER_CHARGE" 0 "DEFAULT" ;
VAL_ 914 BMS_packConfigMultiplexer 1 "Mux1" 0 "Mux0" ;
VAL_ 914 BMS_reservedConfig_0 36 "BMS_CONFIG_36" 35 "BMS_CONFIG_35" 34 "BMS_CONFIG_34" 33 "BMS_CONFIG_33" 32 "BMS_CONFIG_32" 31 "BMS_CONFIG_31" 30 "BMS_CONFIG_30" 29 "BMS_CONFIG_29" 28 "BMS_CONFIG_28" 27 "BMS_CONFIG_27" 26 "BMS_CONFIG_26" 25 "BMS_CONFIG_25" 24 "BMS_CONFIG_24" 23 "BMS_CONFIG_23" 22 "BMS_CONFIG_22" 21 "BMS_CONFIG_21" 20 "BMS_CONFIG_20" 19 "BMS_CONFIG_19" 18 "BMS_CONFIG_18" 17 "BMS_CONFIG_17" 16 "BMS_CONFIG_16" 15 "BMS_CONFIG_15" 14 "BMS_CONFIG_14" 13 "BMS_CONFIG_13" 12 "BMS_CONFIG_12" 11 "BMS_CONFIG_11" 10 "BMS_CONFIG_10" 9 "BMS_CONFIG_9" 8 "BMS_CONFIG_8" 7 "BMS_CONFIG_7" 6 "BMS_CONFIG_6" 5 "BMS_CONFIG_5" 4 "BMS_CONFIG_4" 3 "BMS_CONFIG_3" 2 "BMS_CONFIG_2" 1 "BMS_CONFIG_1" 0 "BMS_CONFIG_0" ;
VAL_ 914 BMS_moduleType 5 "BMS_MOD_TYPE_5" 4 "BMS_MOD_TYPE_4" 3 "BMS_MOD_TYPE_3" 2 "BMS_MOD_TYPE_2" 1 "BMS_MOD_TYPE_1" 0 "BMS_MOD_TYPE_UNKNOWN" ;
VAL_ 914 BMS_thermalPackType 9 "E3D_40P" 8 "E3D" 7 "BLADERUNNER_E1" 6 "BFF00S" 5 "P2" 4 "BFF00_E1" 3 "CATL_E1" 2 "E3" 1 "E1" 0 "UNKNOWN" ;
VAL_ 914 BMS_standbySupplyContinuousPower 3 "17W" 2 "16W" 1 "4W" 0 "0W" ;
VAL_ 914 BMS_beginningOfLifePackEnergy 1023 "SNA" ;
